// PQ35_46_CAN_Antrieb_5.7.6 Generated by BUSNETPQ 7.3.2  © 2009 Sulzer GmbH
VERSION "HNNBNNNYNNNNNNNNNNNNNNNNNNNNNNNNNNNNNNNNNN/4/%%%/4/'%**4NNN///"

NS_ :

BS_:

BU_: AFS Airbag Allrad BAP_Tester BMS_Hybrid Bremse_MK60EC Bremse_MK70MABS Bremse_TRW_EBC450M Bremse_TRW_ESP Daempfer EPB_TRW EPB_TRW_VW411CS FLA Gateway_PQ35 Gateway_Zusatz_EGolf Getriebe_AG6 Getriebe_DQ Getriebe_DQ_Hyb Getriebe_Sele Gurtmikro_PQ35 HCA Ladegeraet_EGolf LEH_Hybrid LH_EPS_APA LH_EPS_ZF_2G LH_EPS_ZF_3G LPG_Interface_Box LWR LWS Magne_Ride Motor_Diesel Motor_EGolf Motor_Hybrid Motor_Otto PDC_PLA Quersperre_VAQ RKA_Plus SAK Waehlhebel Waehlhebel_Sele

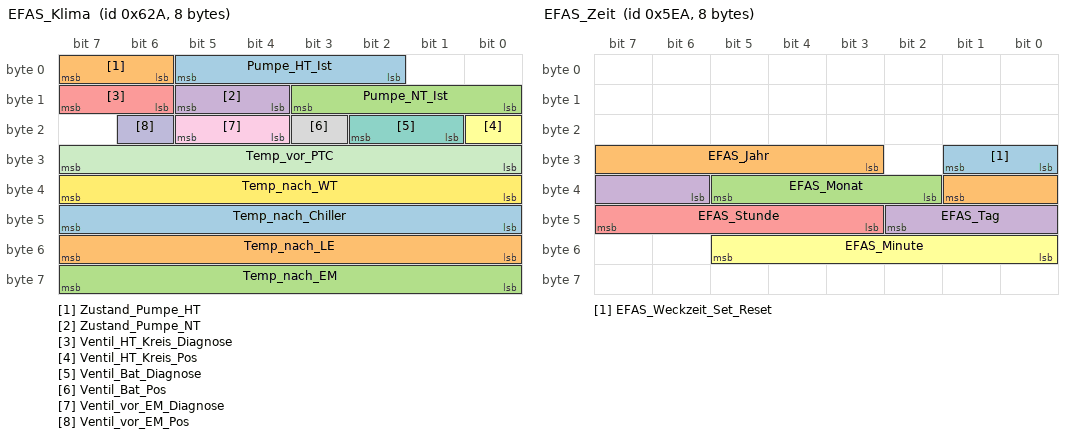
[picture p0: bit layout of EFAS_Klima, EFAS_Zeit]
BO_ 1578 EFAS_Klima: 8 Motor_EGolf
 SG_ Pumpe_HT_Ist : 2|4@1+ (10,0) [0|100] "Unit_PerCent"  Gateway_Zusatz_EGolf
 SG_ Zustand_Pumpe_HT : 6|2@1+ (1,0) [0|3] ""  Gateway_Zusatz_EGolf
 SG_ Pumpe_NT_Ist : 8|4@1+ (10,0) [0|100] "Unit_PerCent"  Gateway_Zusatz_EGolf
 SG_ Zustand_Pumpe_NT : 12|2@1+ (1,0) [0|3] ""  Gateway_Zusatz_EGolf
 SG_ Ventil_HT_Kreis_Diagnose : 14|2@1+ (1,0) [0|3] ""  Gateway_Zusatz_EGolf
 SG_ Ventil_HT_Kreis_Pos : 16|1@1+ (1,0) [0|1] ""  Gateway_Zusatz_EGolf
 SG_ Ventil_Bat_Diagnose : 17|2@1+ (1,0) [0|3] ""  Gateway_Zusatz_EGolf
 SG_ Ventil_Bat_Pos : 19|1@1+ (1,0) [0|1] ""  Gateway_Zusatz_EGolf
 SG_ Ventil_vor_EM_Diagnose : 20|2@1+ (1,0) [0|3] ""  Gateway_Zusatz_EGolf
 SG_ Ventil_vor_EM_Pos : 22|1@1+ (1,0) [0|1] ""  Gateway_Zusatz_EGolf
 SG_ Temp_vor_PTC : 24|8@1+ (1,-40) [-40|213] "Unit_DegreCelsi"  Gateway_Zusatz_EGolf
 SG_ Temp_nach_WT : 32|8@1+ (1,-40) [-40|213] "Unit_DegreCelsi"  Gateway_Zusatz_EGolf
 SG_ Temp_nach_Chiller : 40|8@1+ (1,-40) [-40|213] "Unit_DegreCelsi"  BMS_Hybrid,Gateway_Zusatz_EGolf
 SG_ Temp_nach_LE : 48|8@1+ (1,-40) [-40|213] "Unit_DegreCelsi"  Gateway_Zusatz_EGolf
 SG_ Temp_nach_EM : 56|8@1+ (1,-40) [-40|213] "Unit_DegreCelsi"  Gateway_Zusatz_EGolf

BO_ 1514 EFAS_Zeit: 8 Ladegeraet_EGolf
 SG_ EFAS_Weckzeit_Set_Reset : 24|2@1+ (1,0) [0|3] ""  Gateway_Zusatz_EGolf
 SG_ EFAS_Jahr : 27|7@1+ (1,2000) [2000|2127] "Unit_Year"  Gateway_Zusatz_EGolf
 SG_ EFAS_Monat : 34|4@1+ (1,0) [1|12] "Unit_Month"  Gateway_Zusatz_EGolf
 SG_ EFAS_Tag : 38|5@1+ (1,0) [0|31] "Unit_Day"  Gateway_Zusatz_EGolf
 SG_ EFAS_Stunde : 43|5@1+ (1,0) [0|23] "Unit_Hours"  Gateway_Zusatz_EGolf
 SG_ EFAS_Minute : 48|6@1+ (1,0) [0|59] "Unit_Minut"  Gateway_Zusatz_EGolf

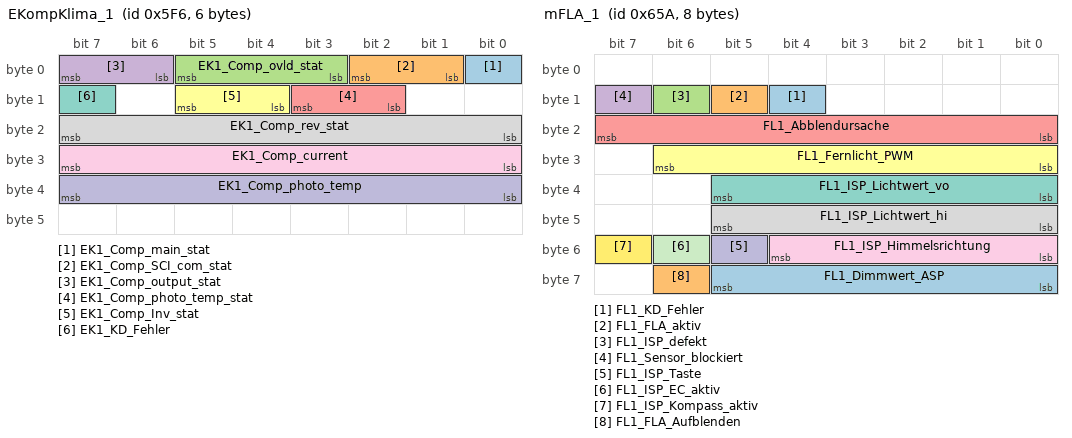
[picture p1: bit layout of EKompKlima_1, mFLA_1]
BO_ 1526 EKompKlima_1: 6 Gateway_PQ35
 SG_ EK1_Comp_main_stat : 0|1@1+ (1,0) [0|1] ""  Gateway_PQ35
 SG_ EK1_Comp_SCI_com_stat : 1|2@1+ (1,0) [0|3] ""  Gateway_PQ35
 SG_ EK1_Comp_ovld_stat : 3|3@1+ (1,0) [0|7] ""  Gateway_PQ35
 SG_ EK1_Comp_output_stat : 6|2@1+ (1,0) [0|3] ""  Gateway_PQ35
 SG_ EK1_Comp_photo_temp_stat : 10|2@1+ (1,0) [0|3] ""  Gateway_PQ35
 SG_ EK1_Comp_Inv_stat : 12|2@1+ (1,0) [0|3] ""  Gateway_PQ35
 SG_ EK1_KD_Fehler : 15|1@1+ (1,0) [0|1] ""  Gateway_PQ35
 SG_ EK1_Comp_rev_stat : 16|8@1+ (50,0) [0|8600] "Unit_MinutInver"  Gateway_PQ35
 SG_ EK1_Comp_current : 24|8@1+ (0.1,0) [0|25.4] "Unit_Amper"  Gateway_PQ35,Motor_Hybrid
 SG_ EK1_Comp_photo_temp : 32|8@1+ (1,0) [0|254] "Unit_DegreCelsi"  Gateway_PQ35

BO_ 1406 EM_Hybrid_1: 1 LEH_Hybrid
 SG_ EY1_KD_Fehler : 0|1@1+ (1,0) [0|1] ""  Gateway_PQ35

BO_ 1472 EPB_1: 8 EPB_TRW
 SG_ EP1_Zaehler : 0|4@1+ (1,0) [0|15] ""  Bremse_MK60EC,Daempfer,Gateway_PQ35,Motor_Diesel,Motor_Otto
 SG_ EP1_Fehler_Sta : 4|2@1+ (1,0) [0|3] ""  Bremse_MK60EC,Gateway_PQ35,PDC_PLA
 SG_ EP1_Sta_EPB : 6|1@1+ (1,0) [0|1] ""  Bremse_MK60EC,Gateway_PQ35,Getriebe_DQ,Getriebe_DQ_Hyb,PDC_PLA
 SG_ EP1_Sta_Schalter : 7|1@1+ (1,0) [0|1] ""  Gateway_PQ35
 SG_ EP1_Spannkraft : 8|5@1+ (1,0) [0|30] "Unit_KiloNewto"  Bremse_MK60EC,Gateway_PQ35,Getriebe_DQ,Getriebe_DQ_Hyb
 SG_ EP1_Schalterinfo : 13|2@1+ (1,0) [0|3] ""  Gateway_PQ35,Motor_Diesel,Motor_Otto
 SG_ EP1_Sta_NWS : 15|1@1+ (1,0) [0|1] ""  Gateway_PQ35,Motor_Diesel,Motor_Otto
 SG_ EP1_Neig_winkel : 16|8@1+ (1,-128) [-128|127] "Unit_PerCentOfForceOfGravi"  Gateway_PQ35,Motor_Diesel,Motor_Otto
 SG_ EP1_Verzoegerung : 24|8@1+ (0.048,-7.968) [-7.968|4.224] "Unit_MeterPerSeconSquar"  Bremse_MK60EC,Daempfer,Gateway_PQ35
 SG_ EP1_Fehlereintr : 32|1@1+ (1,0) [0|1] ""  Gateway_PQ35
 SG_ EP1_Freigabe_Ver : 33|1@1+ (1,0) [0|1] ""  Bremse_MK60EC,Daempfer,Gateway_PQ35
 SG_ EP1_AutoHold_zul : 34|1@1+ (1,0) [0|1] ""  Gateway_PQ35
 SG_ EP1_AutoHold_aktiv : 35|1@1+ (1,0) [0|1] ""  Gateway_PQ35,Motor_Diesel,Motor_Otto
 SG_ EP1_SleepInd : 36|1@1+ (1,0) [0|1] ""  Gateway_PQ35
 SG_ EP1_Status_Kl_15 : 37|1@1+ (1,0) [0|1] ""  Gateway_PQ35
 SG_ EP1_Lampe_AutoP : 38|1@1+ (1,0) [0|1] ""  Gateway_PQ35
 SG_ EP1_Bremslicht : 39|1@1+ (1,0) [0|1] ""  Gateway_PQ35
 SG_ EP1_Warnton1 : 40|1@1+ (1,0) [0|1] ""  Gateway_PQ35
 SG_ EP1_Warnton2 : 41|1@1+ (1,0) [0|1] ""  Gateway_PQ35
 SG_ EP1_AnfShLock : 42|1@1+ (1,0) [0|1] ""  Gateway_PQ35
 SG_ EP1_Auto_Schl_Oe : 43|1@1+ (1,0) [0|1] ""  Gateway_PQ35
 SG_ EP1_QualNeigWi : 44|1@1+ (1,0) [0|1] ""  Gateway_PQ35
 SG_ EP1_KuppModBer : 45|2@1+ (1,0) [0|3] ""  Gateway_PQ35,Motor_Diesel,Motor_Otto
 SG_ EP1_HydrHalten : 47|1@1+ (1,0) [0|1] ""  Gateway_PQ35,Getriebe_DQ,Getriebe_DQ_Hyb,Motor_Diesel,Motor_Otto
 SG_ EP1_Fkt_Lampe : 48|1@1+ (1,0) [0|1] ""  Bremse_MK60EC,Gateway_PQ35
 SG_ EP1_Warnton : 49|1@1+ (1,0) [0|1] ""  Gateway_PQ35
 SG_ EP1_Fehler_BKL : 50|1@1+ (1,0) [0|1] ""  Gateway_PQ35
 SG_ EP1_Fehler_gelb : 51|1@1+ (1,0) [0|1] ""  Gateway_PQ35
 SG_ EP1__Text : 52|4@1+ (1,0) [0|15] ""  Gateway_PQ35,Getriebe_DQ,Getriebe_DQ_Hyb
 SG_ EP1_Checksum : 56|8@1+ (1,0) [0|255] ""  Bremse_MK60EC,Daempfer,Gateway_PQ35,Motor_Diesel,Motor_Otto

BO_ 1626 mFLA_1: 8 FLA
 SG_ FL1_KD_Fehler : 12|1@1+ (1,0) [0|1] ""  Gateway_PQ35
 SG_ FL1_FLA_aktiv : 13|1@1+ (1,0) [0|1] ""  Gateway_PQ35
 SG_ FL1_ISP_defekt : 14|1@1+ (1,0) [0|1] ""  Gateway_PQ35
 SG_ FL1_Sensor_blockiert : 15|1@1+ (1,0) [0|1] ""  Gateway_PQ35
 SG_ FL1_Abblendursache : 16|8@1+ (1,0) [0|255] ""  Gateway_PQ35
 SG_ FL1_Fernlicht_PWM : 24|7@1+ (1,0) [0|100] "Unit_PerCent"  Gateway_PQ35
 SG_ FL1_ISP_Lichtwert_vo : 32|6@1+ (1,0) [0|61] ""  Gateway_PQ35
 SG_ FL1_ISP_Lichtwert_hi : 40|6@1+ (1,0) [0|61] ""  Gateway_PQ35
 SG_ FL1_ISP_Himmelsrichtung : 48|5@1+ (12,0) [0|348] "Unit_DegreOfArc"  Gateway_PQ35
 SG_ FL1_ISP_Taste : 53|1@1+ (1,0) [0|1] ""  Gateway_PQ35
 SG_ FL1_ISP_EC_aktiv : 54|1@1+ (1,0) [0|1] ""  Gateway_PQ35
 SG_ FL1_ISP_Kompass_aktiv : 55|1@1+ (1,0) [0|1] ""  Gateway_PQ35
 SG_ FL1_Dimmwert_ASP : 56|6@1+ (1.613,0) [0|100.006] "Unit_PerCent"  Gateway_PQ35
 SG_ FL1_FLA_Aufblenden : 62|1@1+ (1,0) [0|1] ""  Gateway_PQ35

BO_ 912 Gate_Komf_1: 8 Gateway_PQ35
 SG_ GK1_Sta_RDK_Warn : 0|1@1+ (1,0) [0|1] "" Vector__XXX
 SG_ GK1_Sta_Anhaen : 1|1@1+ (1,0) [0|1] ""  Bremse_MK60EC,Bremse_TRW_EBC450M,Bremse_TRW_ESP,Getriebe_DQ,Getriebe_DQ_Hyb,HCA,Motor_Diesel,Motor_Otto,PDC_PLA,RKA_Plus
 SG_ GK1_Sta_Licht1 : 2|1@1+ (1,0) [0|1] ""  AFS,Bremse_MK60EC,Bremse_MK70MABS,Bremse_TRW_EBC450M,Bremse_TRW_ESP,EPB_TRW,EPB_TRW_VW411CS,FLA,LH_EPS_APA,LH_EPS_ZF_2G,LH_EPS_ZF_3G,Motor_Diesel,Motor_Otto,PDC_PLA
 SG_ GK1_Sta_Licht3 : 3|1@1+ (1,0) [0|1] ""  AFS
 SG_ GK1_Sta_Tuerkont : 4|1@1+ (1,0) [0|1] ""  Bremse_MK60EC,Bremse_MK70MABS,Bremse_TRW_EBC450M,Bremse_TRW_ESP,EPB_TRW,EPB_TRW_VW411CS,Getriebe_DQ,Getriebe_DQ_Hyb,Motor_Diesel,Motor_EGolf,Motor_Hybrid,Motor_Otto,PDC_PLA
 SG_ GK1_Sta_Li_vorn : 5|1@1+ (1,0) [0|1] ""  AFS
 SG_ GK1_SleepAckn : 7|1@1+ (1,0) [0|1] ""  Bremse_MK60EC,Bremse_MK70MABS,Bremse_TRW_ESP,EPB_TRW,Getriebe_AG6,Getriebe_DQ,Getriebe_DQ_Hyb,Getriebe_Sele,LH_EPS_APA,LH_EPS_ZF_2G,LH_EPS_ZF_3G,LWS,Motor_Diesel,Motor_EGolf,Motor_Hybrid,Motor_Otto,Waehlhebel,Waehlhebel_Sele
 SG_ GK1_CharismaModus m1 : 8|4@1+ (1,0) [0|15] ""  Daempfer,Getriebe_AG6,Getriebe_DQ,Getriebe_DQ_Hyb,LH_EPS_APA,LH_EPS_ZF_2G,LH_EPS_ZF_3G,Magne_Ride,Motor_Diesel,Motor_Otto
 SG_ GK1_EfficiencyModus m2 : 8|4@1+ (1,0) [0|15] "" Vector__XXX
 SG_ GK1_SportModus m3 : 8|4@1+ (1,0) [0|15] "" Vector__XXX
 SG_ GK1_DriveSelectModus_1 m4 : 8|4@1+ (1,0) [0|15] "" Vector__XXX
 SG_ GK1_DriveSelectModus_2 m5 : 8|4@1+ (1,0) [0|15] "" Vector__XXX
 SG_ GK1_SamFktNr M : 12|4@1+ (1,0) [0|15] ""  Daempfer,Getriebe_AG6,Getriebe_DQ,Getriebe_DQ_Hyb,LH_EPS_APA,LH_EPS_ZF_2G,LH_EPS_ZF_3G,Magne_Ride,Motor_Diesel,Motor_Otto
 SG_ GK1_Fa_Tuerkont : 16|1@1+ (1,0) [0|1] ""  Bremse_MK60EC,Bremse_MK70MABS,Bremse_TRW_EBC450M,Bremse_TRW_ESP,EPB_TRW,EPB_TRW_VW411CS,Getriebe_DQ,Getriebe_DQ_Hyb,Motor_Diesel,Motor_EGolf,Motor_Hybrid,Motor_Otto
 SG_ GK1_RueckfahrSch : 17|1@1+ (1,0) [0|1] "" Vector__XXX
 SG_ GK1_ELV_verrieg : 18|1@1+ (1,0) [0|1] "" Vector__XXX
 SG_ GK1_Sta_Kessy_2 : 19|1@1+ (1,0) [0|1] "" Vector__XXX
 SG_ GK1_Sta_Stdhzg : 20|1@1+ (1,0) [0|1] ""  Motor_Diesel,Motor_Hybrid,Motor_Otto
 SG_ GK1_SH_Verbau : 21|1@1+ (1,0) [0|1] ""  Motor_Diesel,Motor_Hybrid,Motor_Otto
 SG_ GK1_ParkFrontWi : 22|1@1+ (1,0) [0|1] "" Vector__XXX
 SG_ GK1_KW_Warm : 23|1@1+ (1,0) [0|1] ""  Motor_Diesel,Motor_Hybrid,Motor_Otto
 SG_ BCM_Remotestart_Betrieb : 24|1@1+ (1,0) [0|1] ""  Motor_Diesel,Motor_Otto
 SG_ BCM_Offroad_Taster : 25|1@1+ (1,0) [0|1] ""  Motor_Diesel,Motor_Otto
 SG_ BSK_HL_geoeffnet : 26|1@1+ (1,0) [0|1] ""  Motor_Diesel,Motor_Otto,PDC_PLA
 SG_ BSK_HR_geoeffnet : 27|1@1+ (1,0) [0|1] ""  Motor_Diesel,Motor_Otto,PDC_PLA
 SG_ GK1_Rueckfahr : 28|1@1+ (1,0) [0|1] ""  AFS,Bremse_MK60EC,Bremse_MK70MABS,Bremse_TRW_EBC450M,Bremse_TRW_ESP,EPB_TRW,EPB_TRW_VW411CS,FLA,LH_EPS_APA,LH_EPS_ZF_2G,LH_EPS_ZF_3G,Motor_Diesel,Motor_Otto,PDC_PLA
 SG_ GK1_BrLi_links : 29|1@1+ (1,0) [0|1] "" Vector__XXX
 SG_ GK1_BrLi_rechts : 30|1@1+ (1,0) [0|1] "" Vector__XXX
 SG_ GK1_BrLi_mitte : 31|1@1+ (1,0) [0|1] "" Vector__XXX
 SG_ GK1_BLS_ILM : 32|1@1+ (1,0) [0|1] "" Vector__XXX
 SG_ GK1_EDC_ILM : 33|1@1+ (1,0) [0|1] "" Vector__XXX
 SG_ GK1_Blinker_li : 34|1@1+ (1,0) [0|1] ""  AFS,LWR,Motor_Diesel,Motor_Otto,PDC_PLA
 SG_ GK1_Blinker_re : 35|1@1+ (1,0) [0|1] ""  AFS,LWR,Motor_Diesel,Motor_Otto,PDC_PLA
 SG_ GK1_def_P_verr : 36|1@1+ (1,0) [0|1] ""  Getriebe_AG6,Motor_EGolf
 SG_ GK1_LS1_Fernlicht : 37|1@1+ (1,0) [0|1] ""  FLA
 SG_ GK1_Sta_Licht2 : 38|1@1+ (1,0) [0|1] ""  AFS
 SG_ GK1_Sta_LSM : 39|1@1+ (1,0) [0|1] ""  AFS,FLA,Getriebe_AG6,Motor_Diesel,Motor_Otto,PDC_PLA
 SG_ WI1_Front_Wasch : 40|1@1+ (1,0) [0|1] "" Vector__XXX
 SG_ BSK_BT_geoeffnet : 41|1@1+ (1,0) [0|1] ""  Motor_Diesel,Motor_Otto
 SG_ BCM_CV_Taster : 42|1@1+ (1,0) [0|1] "" Vector__XXX
 SG_ BSK_HD_Hauptraste : 43|1@1+ (1,0) [0|1] ""  Motor_Diesel,Motor_Otto
 SG_ GK1_Anhaenger : 46|1@1+ (1,0) [0|1] ""  Bremse_MK60EC,Bremse_TRW_EBC450M,Bremse_TRW_ESP,Getriebe_DQ,Getriebe_DQ_Hyb,HCA,Motor_Diesel,Motor_Otto,PDC_PLA,RKA_Plus
 SG_ GK1_BrLi_Anhaen : 47|1@1+ (1,0) [0|1] "" Vector__XXX
 SG_ GK1_Abblendlicht : 48|1@1+ (1,0) [0|1] ""  AFS,FLA,LWR
 SG_ GK1_Fernlicht : 49|1@1+ (1,0) [0|1] ""  AFS,FLA,LWR
 SG_ GK1_Wischer_vorn : 50|1@1+ (1,0) [0|1] ""  AFS,Bremse_MK60EC,Bremse_MK70MABS,Bremse_TRW_EBC450M,Bremse_TRW_ESP,HCA,Motor_Diesel
 SG_ GK1_Sta_ILM_F_1 : 51|1@1+ (1,0) [0|1] ""  AFS,Bremse_MK60EC,Bremse_MK70MABS,Bremse_TRW_EBC450M,Bremse_TRW_ESP,HCA
 SG_ GK1_Abbl_VL_def : 52|1@1+ (1,0) [0|1] ""  AFS
 SG_ GK1_Abbl_VR_def : 53|1@1+ (1,0) [0|1] ""  AFS
 SG_ GK1_Blink_Autob : 54|1@1+ (1,0) [0|1] "" Vector__XXX
 SG_ GK1_Warnblk_Status : 55|1@1+ (1,0) [0|1] ""  Bremse_TRW_EBC450M,Bremse_TRW_ESP
 SG_ GK1_SH_laeuft : 56|1@1+ (1,0) [0|1] "" Vector__XXX
 SG_ SH1_ein_Wasserpumpe : 57|1@1+ (1,0) [0|1] "" Vector__XXX
 SG_ GK1_Nebel_ein : 58|1@1+ (1,0) [0|1] ""  AFS,FLA
 SG_ GK1_Bremslicht : 59|1@1+ (1,0) [0|1] "" Vector__XXX
 SG_ GK1_Anh_abgesteckt : 60|1@1+ (1,0) [0|1] "" Vector__XXX
 SG_ GK1_AnhKonLamp : 61|1@1+ (1,0) [0|1] "" Vector__XXX
 SG_ LDS_Stellung_AFL : 62|1@1+ (1,0) [0|1] "" Vector__XXX
 SG_ GK1_SH_Zusatzfkt : 63|1@1+ (1,0) [0|1] "" Vector__XXX

BO_ 914 Gate_Komf_2: 8 Gateway_PQ35
 SG_ GK2_Sta_LSM : 0|1@1+ (1,0) [0|1] "" Vector__XXX
 SG_ GK2_Sta_Lichtsensor : 1|1@1+ (1,0) [0|1] ""  AFS
 SG_ GK2_Sta_Licht1 : 2|1@1+ (1,0) [0|1] ""  AFS,HCA
 SG_ GK2_Sta_VSG : 3|1@1+ (1,0) [0|1] ""  Airbag,Motor_Otto,PDC_PLA
 SG_ GK2_Sta_Schluessel : 4|1@1+ (1,0) [0|1] ""  Daempfer
 SG_ GK2_Sta_Profil : 5|1@1+ (1,0) [0|1] ""  PDC_PLA
 SG_ GK2_Sta_Clima2 : 6|1@1+ (1,0) [0|1] ""  Motor_Diesel,Motor_Otto
 SG_ GK2_Sta_BSG4 : 7|1@1+ (1,0) [0|1] ""  Motor_Diesel,Motor_Otto
 SG_ GK2_Sta_Kessy_4 : 8|1@1+ (1,0) [0|1] ""  Motor_Diesel,Motor_Otto
 SG_ BS4_Gleitende_Leuchtw_Anf : 9|1@1+ (1,0) [0|1] "" Vector__XXX
 SG_ BS4_GLW_Fernlicht_Anf : 10|1@1+ (1,0) [0|1] "" Vector__XXX
 SG_ GK2_Blk_L_Kontrolle : 11|1@1+ (1,0) [0|1] ""  HCA
 SG_ GK2_Blk_R_Kontrolle : 12|1@1+ (1,0) [0|1] ""  HCA
 SG_ GK2_LS_KomFehler : 14|1@1+ (1,0) [0|1] ""  AFS
 SG_ GK2_LS_def : 15|1@1+ (1,0) [0|1] ""  AFS
 SG_ GK2_Helligkeit : 16|3@1+ (714.286,0) [0|5000.002] "Unit_Lux"  AFS
 SG_ GK2_VD_zu_ver : 19|1@1+ (1,0) [0|1] ""  PDC_PLA
 SG_ GK2_VD_entriegelt : 20|1@1+ (1,0) [0|1] ""  PDC_PLA
 SG_ GK2_VD_offen_ver : 21|1@1+ (1,0) [0|1] ""  Airbag,Motor_Otto,PDC_PLA
 SG_ GK2_Verdeck_Anf : 22|1@1+ (1,0) [0|1] ""  PDC_PLA
 SG_ GK2_VDKD_auf : 23|1@1+ (1,0) [0|1] ""  PDC_PLA
 SG_ GK2_Schluessel : 24|4@1+ (1,0) [0|15] "" Vector__XXX
 SG_ GK2_Hardtop : 28|1@1+ (1,0) [0|1] ""  PDC_PLA
 SG_ GK2_AFL_Schalter : 29|1@1+ (1,0) [0|1] ""  AFS
 SG_ GK2_Nebelschluss : 30|1@1+ (1,0) [0|1] ""  AFS
 SG_ GK2_EM_LIN_ungueltig : 31|1@1+ (1,0) [0|1] ""  Motor_Diesel,Motor_Otto
 SG_ GK2_Profil : 32|4@1+ (1,0) [0|15] ""  PDC_PLA
 SG_ GK2_Kl_StSt_Info : 36|2@1+ (1,0) [0|3] ""  Motor_Diesel,Motor_Otto
 SG_ GK2_BSG_StSt_Info : 38|2@1+ (1,0) [0|3] ""  Motor_Diesel,Motor_Otto
 SG_ GK2_BEM_P_Generator : 40|8@1+ (50,0) [0|12700] "Unit_Watt"  Motor_Diesel,Motor_Otto
 SG_ GK2_BEM_Abschaltstufen : 48|3@1+ (1,0) [0|7] "" Vector__XXX
 SG_ GK2_BEM_DFM : 51|5@1+ (3.225,0.025) [0.025|100] "Unit_PerCent"  Motor_Diesel,Motor_Otto
 SG_ GK2_Kessy_StSt_Info : 56|2@1+ (1,0) [0|3] ""  Motor_Diesel,Motor_Otto
 SG_ GK2_BEM_StSt_Info : 58|2@1+ (1,0) [0|3] ""  Motor_Diesel,Motor_Otto
 SG_ BEM_Segel_Info : 60|2@1+ (1,0) [0|3] ""  Getriebe_DQ,Getriebe_DQ_Hyb,Motor_Diesel,Motor_Otto
 SG_ LS1_FAS_Taster : 62|1@1+ (1,0) [0|1] "" Vector__XXX
 SG_ LS1_Fehler_FAS_Taster : 63|1@1+ (1,0) [0|1] "" Vector__XXX

BO_ 915 Gate_Komf_3: 8 Gateway_PQ35
 SG_ GK3_Sta_Kessy_4 : 0|1@1+ (1,0) [0|1] "" Vector__XXX
 SG_ GK3_Sta_BCM_KY1 : 1|1@1+ (1,0) [0|1] "" Vector__XXX
 SG_ GK3_Sta_Clima_3 : 2|1@1+ (1,0) [0|1] "" Vector__XXX
 SG_ GK3_Sta_TSG_FT_3 : 3|1@1+ (1,0) [0|1] "" Vector__XXX
 SG_ GK3_Sta_HD_1 : 4|1@1+ (1,0) [0|1] ""  PDC_PLA
 SG_ GK3_Sta_Memory_1 : 5|1@1+ (1,0) [0|1] "" Vector__XXX
 SG_ GK3_Sta_res_06 : 6|1@1+ (1,0) [0|1] "" Vector__XXX
 SG_ GK3_Sta_res_07 : 7|1@1+ (1,0) [0|1] "" Vector__XXX
 SG_ GK3_KY4_Meldungen : 8|4@1+ (1,0) [0|15] "" Vector__XXX
 SG_ GK3_KY4_Gong_600 : 12|1@1+ (1,0) [0|1] "" Vector__XXX
 SG_ GK3_KY4_PassAL_Menue : 14|1@1+ (1,0) [0|1] "" Vector__XXX
 SG_ GK3_KY4_PassAL_akt : 15|1@1+ (1,0) [0|1] "" Vector__XXX
 SG_ GK3_BK1_IDGeb_1_Sta : 16|3@1+ (1,0) [0|7] "" Vector__XXX
 SG_ GK3_BK1_IDGeb_2_Sta : 19|3@1+ (1,0) [0|7] "" Vector__XXX
 SG_ ME1_EasyEntry_Menu : 22|1@1+ (1,0) [0|1] "" Vector__XXX
 SG_ ME1_EasyEntry_aktiv : 23|1@1+ (1,0) [0|1] "" Vector__XXX
 SG_ GK3_BK1_IDGeb_3_Sta : 24|3@1+ (1,0) [0|7] "" Vector__XXX
 SG_ GK3_BK1_IDGeb_4_Sta : 27|3@1+ (1,0) [0|7] "" Vector__XXX
 SG_ GK3_BK1_Anlern_Info : 30|1@1+ (1,0) [0|1] "" Vector__XXX
 SG_ CL3_SH_Wasserpumpe : 32|1@1+ (1,0) [0|1] "" Vector__XXX
 SG_ FT3_Auto_eKiSi_Menu : 33|1@1+ (1,0) [0|1] "" Vector__XXX
 SG_ FT3_Auto_eKiSi_Aktiv : 34|1@1+ (1,0) [0|1] "" Vector__XXX
 SG_ MKE_Texte : 35|3@1+ (1,0) [0|7] "" Vector__XXX
 SG_ HSA_unplausibel : 38|1@1+ (1,0) [0|1] "" Vector__XXX
 SG_ CHA_Kombi_Texte : 40|4@1+ (1,0) [0|15] "" Vector__XXX
 SG_ HD1_Position : 56|8@1+ (0.5,0) [0|100] "Unit_PerCent"  PDC_PLA

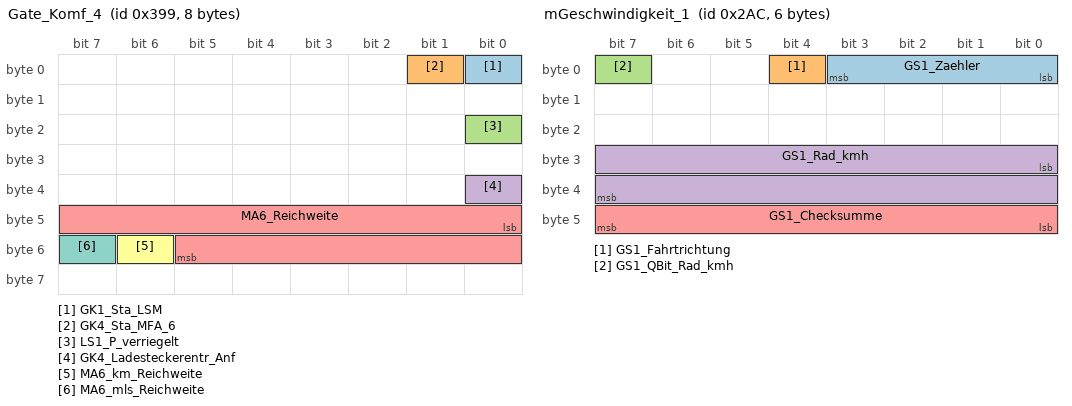
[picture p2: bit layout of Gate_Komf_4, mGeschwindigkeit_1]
BO_ 921 Gate_Komf_4: 8 Gateway_Zusatz_EGolf
 SG_ GK1_Sta_LSM : 0|1@1+ (1,0) [0|1] ""  Motor_EGolf
 SG_ GK4_Sta_MFA_6 : 1|1@1+ (1,0) [0|1] ""  Motor_EGolf
 SG_ LS1_P_verriegelt : 16|1@1+ (1,0) [0|1] ""  Motor_EGolf
 SG_ GK4_Ladesteckerentr_Anf : 32|1@1+ (1,0) [0|1] ""  Ladegeraet_EGolf,Motor_EGolf
 SG_ MA6_Reichweite : 40|14@1+ (1,0) [0|16382] ""  Motor_EGolf
 SG_ MA6_km_Reichweite : 54|1@1+ (1,0) [0|1] ""  Motor_EGolf
 SG_ MA6_mls_Reichweite : 55|1@1+ (1,0) [0|1] ""  Motor_EGolf

BO_ 684 mGeschwindigkeit_1: 6 Bremse_MK60EC
 SG_ GS1_Zaehler : 0|4@1+ (1,0) [0|15] ""  Magne_Ride
 SG_ GS1_Fahrtrichtung : 4|1@1+ (1,0) [0|1] "" Vector__XXX
 SG_ GS1_QBit_Rad_kmh : 7|1@1+ (1,0) [0|1] ""  Magne_Ride
 SG_ GS1_Rad_kmh : 24|16@1+ (0.01,0) [0|654.15] "Unit_KiloMeterPerHour"  Magne_Ride,SAK
 SG_ GS1_Checksumme : 40|8@1+ (1,0) [0|255] ""  Magne_Ride

BO_ 1088 Getriebe_1: 8 Getriebe_AG6
 SG_ GE1_Schaltung : 0|1@1+ (1,0) [0|1] ""  Bremse_MK60EC,Bremse_MK70MABS,Bremse_TRW_EBC450M,Bremse_TRW_ESP,Gateway_PQ35,Motor_Diesel,Motor_Hybrid,Motor_Otto,RKA_Plus
 SG_ GE1_Sta_Schutz : 1|1@1+ (1,0) [0|1] ""  Gateway_PQ35,Motor_Diesel,Motor_Hybrid,Motor_Otto
 SG_ GE1_Klimakompr : 2|1@1+ (1,0) [0|1] ""  Gateway_PQ35,Motor_Diesel,Motor_Hybrid,Motor_Otto
 SG_ GE1_WK : 3|2@1+ (1,0) [0|3] ""  Allrad,Gateway_PQ35,Motor_Diesel,Motor_Hybrid,Motor_Otto,RKA_Plus
 SG_ GE1_StSt_Info : 5|2@1+ (1,0) [0|3] ""  Gateway_PQ35,Motor_Diesel,Motor_Otto
 SG_ GE1_EGS_Anf : 7|1@1+ (1,0) [0|1] ""  Gateway_PQ35,Motor_Diesel,Motor_Hybrid,Motor_Otto
 SG_ GE1_Zielgang : 8|4@1+ (1,0) [0|15] ""  Allrad,Bremse_MK60EC,Bremse_MK70MABS,Bremse_TRW_EBC450M,Bremse_TRW_ESP,Gateway_PQ35,Motor_Diesel,Motor_Hybrid,Motor_Otto,RKA_Plus
 SG_ GE1_Wahl_Pos : 12|4@1+ (1,0) [0|15] ""  BMS_Hybrid,Bremse_MK60EC,Bremse_MK70MABS,Bremse_TRW_EBC450M,Bremse_TRW_ESP,EPB_TRW,EPB_TRW_VW411CS,Gateway_PQ35,Motor_Diesel,Motor_Hybrid,Motor_Otto,PDC_PLA,RKA_Plus
 SG_ GE1_Mrad_Mkurb : 16|8@1+ (0.1,0) [0|25.4] ""  Bremse_MK60EC,Bremse_MK70MABS,Bremse_TRW_EBC450M,Bremse_TRW_ESP,EPB_TRW,EPB_TRW_VW411CS,Gateway_PQ35,Motor_Diesel,Motor_Hybrid,Motor_Otto
 SG_ GE1_Soll_Mo : 24|8@1+ (0.39,0) [0|99.06] "Unit_PerCent"  Gateway_PQ35,Motor_Diesel,Motor_Hybrid,Motor_Otto
 SG_ GE1_Fahrwistd : 32|8@1+ (0.249,-31.623) [-31.623|31.623] ""  Gateway_PQ35,Motor_Diesel,Motor_Hybrid,Motor_Otto
 SG_ GE1_Notlauf : 40|4@1+ (1,0) [0|15] ""  Bremse_TRW_EBC450M,Bremse_TRW_ESP,Gateway_PQ35,Motor_Diesel,Motor_Hybrid,Motor_Otto
 SG_ GE1_Kuehlung : 44|2@1+ (1,0) [0|3] ""  Gateway_PQ35,Motor_Diesel,Motor_Hybrid,Motor_Otto
 SG_ GE1_Sta_OBD : 47|1@1+ (1,0) [0|1] ""  Gateway_PQ35,Motor_Diesel,Motor_Hybrid,Motor_Otto
 SG_ GE1_LaunchControl : 48|1@1+ (1,0) [0|1] ""  Bremse_MK60EC,Bremse_MK70MABS,Gateway_PQ35,Motor_Diesel,Motor_Hybrid,Motor_Otto
 SG_ GE1_Infobit : 49|1@1+ (1,0) [0|1] ""  Gateway_PQ35
 SG_ GE1_SleepInd : 50|1@1+ (1,0) [0|1] ""  Gateway_PQ35
 SG_ GE1_Zaehler : 51|4@1+ (1,0) [0|15] ""  Bremse_MK60EC,Bremse_TRW_EBC450M,Bremse_TRW_ESP,EPB_TRW,EPB_TRW_VW411CS,Gateway_PQ35,Motor_Diesel,Motor_Hybrid,Motor_Otto
 SG_ GE1_Fehlereintr : 55|1@1+ (1,0) [0|1] ""  Gateway_PQ35
 SG_ GE1_WaVerl_Mo : 56|8@1+ (0.39,0) [0|99.06] "Unit_PerCent"  Gateway_PQ35,Motor_Diesel,Motor_Hybrid,Motor_Otto

BO_ 1344 Getriebe_2: 8 Getriebe_AG6
 SG_ GE2_LFR_Adap : 0|1@1+ (1,0) [0|1] ""  Gateway_PQ35,Motor_Diesel,Motor_Hybrid,Motor_Otto
 SG_ GE2_Sta_SAS : 1|1@1+ (1,0) [0|1] ""  Gateway_PQ35,Motor_Otto
 SG_ GE2_SlipStDZEingr : 2|1@1+ (1,0) [0|1] ""  Gateway_PQ35,Motor_Hybrid
 SG_ GE2_Sta_ZwGas : 3|1@1+ (1,0) [0|1] ""  Gateway_PQ35,Motor_Diesel,Motor_Hybrid,Motor_Otto
 SG_ GE2_Zaehler : 4|4@1+ (1,0) [0|15] ""  Gateway_PQ35,Motor_Diesel,Motor_Hybrid,Motor_Otto
 SG_ GE2_LL_Solldz : 8|8@1+ (10,0) [0|2540] "Unit_MinutInver"  Gateway_PQ35,Motor_Diesel,Motor_Hybrid,Motor_Otto
 SG_ GE2_Grad_begr : 16|8@1+ (10,0) [0|2540] "Unit_NewtoMeterPerSecon"  Gateway_PQ35,Motor_Diesel,Motor_Hybrid,Motor_Otto
 SG_ GE2_Sync_Dz : 24|8@1+ (25,0) [0|6375] "Unit_MinutInver"  Gateway_PQ35,Motor_Diesel,Motor_Hybrid,Motor_Otto
 SG_ GE2_invSync_Dz : 32|8@1+ (-25,6375) [0|6375] "Unit_MinutInver"  Gateway_PQ35,Motor_Diesel,Motor_Hybrid,Motor_Otto
 SG_ GE2_Sync_Zeit : 40|8@1+ (20,0) [0|5080] "Unit_MilliSecon"  Gateway_PQ35,Motor_Diesel,Motor_Hybrid,Motor_Otto
 SG_ GE2_DZM_Daempf : 48|1@1+ (1,0) [0|1] ""  Gateway_PQ35,Motor_Diesel,Motor_Otto
 SG_ GE2_invMSB_Sync : 49|1@1+ (1,0) [0|1] ""  Gateway_PQ35,Motor_Otto
 SG_ GE2_Gong : 50|1@1+ (1,0) [0|1] ""  Gateway_PQ35
 SG_ GE2_Segeln_aktiv : 51|1@1+ (1,0) [0|1] ""  Gateway_PQ35
 SG_ GE2_Shift_Lock : 52|1@1+ (1,0) [0|1] ""  Gateway_PQ35
 SG_ GE2_Senderkennung : 53|1@1+ (1,0) [0|1] ""  Allrad,Gateway_PQ35
 SG_ GE2_MSB_Sync : 54|1@1+ (1,0) [0|1] ""  Gateway_PQ35,Motor_Otto
 SG_ GE2_WBA_Blinken : 55|1@1+ (1,0) [0|1] ""  Gateway_PQ35,Motor_Diesel,Motor_Hybrid,Motor_Otto
 SG_ GE2_Variante M : 56|4@1+ (1,0) [0|15] ""  Allrad,Gateway_PQ35,Waehlhebel_Sele
 SG_ GE2_5Gang m0 : 60|4@1+ (1,0) [0|15] ""  Gateway_PQ35
 SG_ GE2_PRND m1 : 60|4@1+ (1,0) [0|15] ""  Gateway_PQ35
 SG_ GE2_4Gang m2 : 60|4@1+ (1,0) [0|15] ""  Gateway_PQ35
 SG_ GE2_ASG m3 : 60|4@1+ (1,0) [0|15] ""  Gateway_PQ35
 SG_ GE2_Selespeed m4 : 60|4@1+ (1,0) [0|15] ""  Gateway_PQ35,Waehlhebel_Sele
 SG_ GE2_res_MUX5 m5 : 60|4@1+ (1,0) [0|15] ""  Gateway_PQ35
 SG_ GE2_PRNDS m6 : 60|4@1+ (1,0) [0|15] ""  Gateway_PQ35
 SG_ GE2_PRNED m7 : 60|4@1+ (1,0) [0|15] ""  Gateway_PQ35
 SG_ GE2_Tip4Gang m8 : 60|4@1+ (1,0) [0|15] ""  Gateway_PQ35
 SG_ GE2_Tip5Gang m9 : 60|4@1+ (1,0) [0|15] ""  Gateway_PQ35
 SG_ GE2_res_MUX10 m10 : 60|4@1+ (1,0) [0|15] ""  Gateway_PQ35
 SG_ GE2_PRNDB m11 : 60|4@1+ (1,0) [0|15] ""  Gateway_PQ35
 SG_ GE2_Tip6Gang m12 : 60|4@1+ (1,0) [0|15] ""  Gateway_PQ35
 SG_ GE2_Tip7Gang m13 : 60|4@1+ (1,0) [0|15] ""  Gateway_PQ35
 SG_ GE2_Tip8Gang m14 : 60|4@1+ (1,0) [0|15] ""  Gateway_PQ35
 SG_ GE2_akt_Gang m15 : 60|4@1+ (1,0) [0|15] ""  Gateway_PQ35,Waehlhebel_Sele

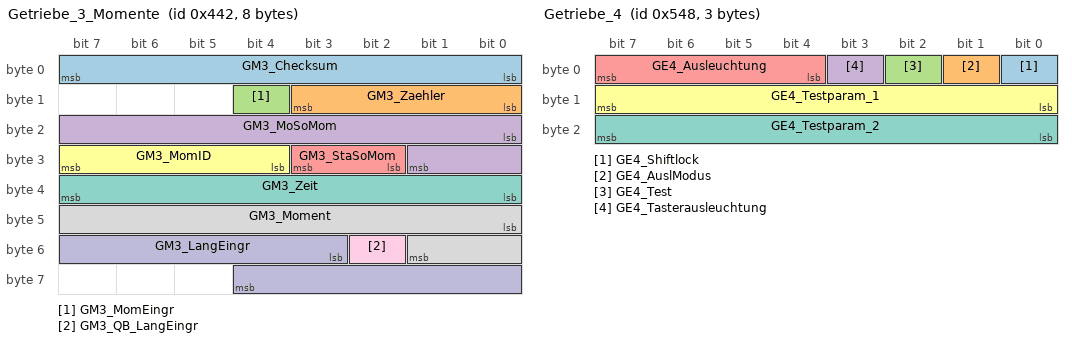
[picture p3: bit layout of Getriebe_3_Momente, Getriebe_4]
BO_ 1090 Getriebe_3_Momente: 8 Getriebe_DQ
 SG_ GM3_Checksum : 0|8@1+ (1,0) [0|255] ""  Motor_Otto
 SG_ GM3_Zaehler : 8|4@1+ (1,0) [0|15] ""  Motor_Otto
 SG_ GM3_MomEingr : 12|1@1+ (1,0) [0|1] ""  Motor_Hybrid,Motor_Otto
 SG_ GM3_MoSoMom : 16|10@1+ (1,0) [0|1021] "Unit_NewtoMeter"  Motor_Hybrid,Motor_Otto
 SG_ GM3_StaSoMom : 26|2@1+ (1,0) [0|3] ""  Motor_Otto
 SG_ GM3_MomID : 28|4@1+ (1,0) [0|15] ""  Motor_Otto
 SG_ GM3_Zeit : 32|8@1+ (10,0) [0|2550] "Unit_MilliSecon"  Motor_Otto
 SG_ GM3_Moment : 40|10@1+ (1,0) [0|1022] "Unit_NewtoMeter"  Motor_Otto
 SG_ GM3_QB_LangEingr : 50|1@1+ (1,0) [0|1] ""  Motor_Otto
 SG_ GM3_LangEingr : 51|10@1+ (1,0) [0|1021] "Unit_NewtoMeter"  Motor_Otto

BO_ 1352 Getriebe_4: 3 Getriebe_DQ
 SG_ GE4_Shiftlock : 0|1@1+ (1,0) [0|1] ""  Waehlhebel
 SG_ GE4_AuslModus : 1|1@1+ (1,0) [0|1] ""  Waehlhebel
 SG_ GE4_Test : 2|1@1+ (1,0) [0|1] ""  Waehlhebel
 SG_ GE4_Tasterausleuchtung : 3|1@1+ (1,0) [0|1] "" Vector__XXX
 SG_ GE4_Ausleuchtung : 4|4@1+ (1,0) [0|15] ""  Waehlhebel
 SG_ GE4_Testparam_1 : 8|8@1+ (1,0) [0|255] ""  Waehlhebel
 SG_ GE4_Testparam_2 : 16|8@1+ (1,0) [0|255] ""  Waehlhebel

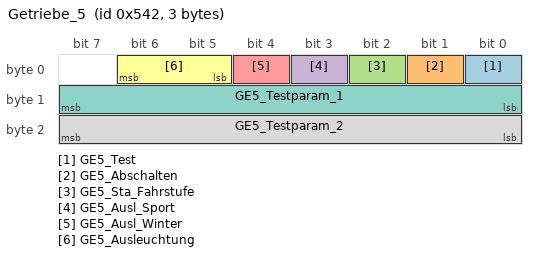
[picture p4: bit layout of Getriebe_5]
BO_ 1346 Getriebe_5: 3 Getriebe_Sele
 SG_ GE5_Test : 0|1@1+ (1,0) [0|1] ""  Waehlhebel_Sele
 SG_ GE5_Abschalten : 1|1@1+ (1,0) [0|1] ""  Waehlhebel_Sele
 SG_ GE5_Sta_Fahrstufe : 2|1@1+ (1,0) [0|1] ""  Waehlhebel_Sele
 SG_ GE5_Ausl_Sport : 3|1@1+ (1,0) [0|1] ""  Waehlhebel_Sele
 SG_ GE5_Ausl_Winter : 4|1@1+ (1,0) [0|1] ""  Waehlhebel_Sele
 SG_ GE5_Ausleuchtung : 5|2@1+ (1,0) [0|3] ""  Waehlhebel_Sele
 SG_ GE5_Testparam_1 : 8|8@1+ (1,0) [0|255] ""  Waehlhebel_Sele
 SG_ GE5_Testparam_2 : 16|8@1+ (1,0) [0|255] ""  Waehlhebel_Sele

BO_TX_BU_ 1472 : EPB_TRW,EPB_TRW_VW411CS;
BO_TX_BU_ 1088 : Getriebe_AG6,Getriebe_DQ,Getriebe_DQ_Hyb,Getriebe_Sele,Motor_EGolf;
BO_TX_BU_ 1344 : Getriebe_AG6,Getriebe_DQ,Getriebe_DQ_Hyb,Getriebe_Sele,Motor_Diesel,Motor_EGolf,Motor_Otto;
BO_TX_BU_ 1090 : Getriebe_DQ,Getriebe_DQ_Hyb,Getriebe_Sele;
BO_TX_BU_ 1352 : Getriebe_DQ,Getriebe_DQ_Hyb,Motor_EGolf;
CM_ SG_ 1578 Pumpe_HT_Ist "Info an das KBT über Ansteuerung der HT-Pumpe für Funktion und Thermomanagement";
CM_ SG_ 1578 Zustand_Pumpe_HT "Zustandsrückmeldung HT Wasserpumpe von MED an Klima";
CM_ SG_ 1578 Pumpe_NT_Ist "Info an das KBT über Ansteuerung der NT-Pumpe für Funktion und Thermomanagement";
CM_ SG_ 1578 Zustand_Pumpe_NT "Zustandsrückmeldung NT Wasserpumpe";
CM_ SG_ 1578 Ventil_HT_Kreis_Diagnose "Diagnoseinformation des 3/2 Wegeventils im HT Absperrkreis";
CM_ SG_ 1578 Ventil_HT_Kreis_Pos "Positionsrückmeldung des Ventils HT-Kreislauf für Klima-SG";
CM_ SG_ 1578 Ventil_Bat_Diagnose "Diagnoseinformation des 3/2 Wegeventils für die HV-Batterie";
CM_ SG_ 1578 Ventil_Bat_Pos "Positionsrückmeldung des Ventils HV-Batterie für Klima-SG";
CM_ SG_ 1578 Ventil_vor_EM_Diagnose "Diagnoseinformation des 3/2 Wegeventils vor der E-Maschine";
CM_ SG_ 1578 Ventil_vor_EM_Pos "Positionsrückmeldung des Ventils vor der E-Maschine für Klima-SG";
CM_ SG_ 1578 Temp_vor_PTC "Wassertemperatur vor PTC";
CM_ SG_ 1578 Temp_nach_WT "Wassertemperatur nach Wärmetauscher";
CM_ SG_ 1578 Temp_nach_Chiller "Wassertemperatur nach Chiller";
CM_ SG_ 1578 Temp_nach_LE "Wassertemperatur nach Leistungselektronik";
CM_ SG_ 1578 Temp_nach_EM "Wassertemperatur nach E-Maschine und Ausgleichsbehälter";
CM_ SG_ 1514 EFAS_Weckzeit_Set_Reset "Weckzeit im GSM setzen oder löschen";
CM_ SG_ 1514 EFAS_Jahr "0 für Datum unbekannt (z.B. keine Funkuhr)
(bei relativem Datum ist auch der Wert 0 gültig siehe Spezifikation_Tageszähler_Kombi_01.doc)";
CM_ SG_ 1514 EFAS_Monat "0 = Monat unbekannt
Dh = ungueltig
Eh = relatives Datum siehe Spezifikation_Tageszähler_Kombi_01.doc
Fh = Keine Funkuhrinformation vorhanden und 12 h Anzeige (Monat, Tag, Jahr fehlen)";
CM_ SG_ 1514 EFAS_Tag "0 für Datum unbekannt (z.B. keine Funkuhr)
(bei relativem Datum ist auch der Wert 0 gültig siehe Spezifikation_Tageszähler_Kombi_01.doc)";
CM_ SG_ 1514 EFAS_Stunde "18h - 1Fh ungueltig";
CM_ SG_ 1514 EFAS_Minute "3Ch - 3Fh ungueltig";
CM_ SG_ 1526 EK1_Comp_main_stat "Real compressor status not CAN board status";
CM_ SG_ 1526 EK1_Comp_SCI_com_stat "'00' normal
'x1' CAN_error (abnormal)
'1x' Inverter_error";
CM_ SG_ 1526 EK1_Comp_ovld_stat "Diagnosis series 1 'Over load'
'0' normal
'2' current restriction
'3' software over current
'4' over load
'6' over input current";
CM_ SG_ 1526 EK1_Comp_output_stat "Diagnosis series 1 'Output'
'0' normal
'1' output line short
'2' output line cut out
'3' abnormal current detection";
CM_ SG_ 1526 EK1_Comp_photo_temp_stat "Diagnosis series 2 'Inverter temp.'
'0' normal
'1' over heat L
'2' over heat S
'3' sermister abnormal";
CM_ SG_ 1526 EK1_Comp_Inv_stat "Diagnosis series 2 'Startability'
'0' normal
'1' start fail
'2' temp protection
'3' system abnormal stop";
CM_ SG_ 1526 EK1_KD_Fehler "Mind. ein Kundendienstfehler ist eingetragen";
CM_ SG_ 1526 EK1_Comp_rev_stat "compressor real revolution
0-8624 rpm is outputted
'output = (actual speed + 25) / 50' speed over 8625rpm: '172'";
CM_ SG_ 1526 EK1_Comp_current "Compressor input current";
CM_ SG_ 1526 EK1_Comp_photo_temp "IGBT temp. measured by inverter.;Photo coupler temp. is not measured in compressor temp. of IGBT (same as EK1_Comp_Inv_temp) will be sent";
CM_ SG_ 1406 EY1_KD_Fehler "Info für Diagnose
bei gesetztem Bit befindet sich mindestens ein Kundendienstfehler im Fehlerspeicher";
CM_ SG_ 1472 EP1_Zaehler "Freilaufender Botschaftszähler";
CM_ SG_ 1472 EP1_Fehler_Sta "Fehlerstatus Parkbremse";
CM_ SG_ 1472 EP1_Sta_EPB "Gibt den Zustand der EPB-Aktuatoren an. Verknüpfung mit Fehlerstatus; wenn z.B. 'Linke Seite Fehlerhaft' und 'Bremse geschlossen', dann ist nur die rechte Seite geschlossen. Das Bit gesetzt, wenn auf einer Seite Spannkraft aufgebaut wird. Wenn auf beiden ";
CM_ SG_ 1472 EP1_Sta_Schalter "Auch bei vollen Funktion kann kurzfristig ein Schalterfehler vorliegen
Schalterstatus Parkbremse";
CM_ SG_ 1472 EP1_Spannkraft "Erzeugte Spannkraft. Bezieht sich auf die Aktuatoren";
CM_ SG_ 1472 EP1_Schalterinfo "Spiegelt die Schalterstellung wider
Schalterinfo Parkbremse";
CM_ SG_ 1472 EP1_Sta_NWS "Funktion des Neigungswinkelsensors
1: Dauerhafter Ausfall oder Fehler Neigungswinkelgeber
Status Neigungswinkelgeber";
CM_ SG_ 1472 EP1_Neig_winkel "Neigungswinkelsignal";
CM_ SG_ 1472 EP1_Verzoegerung "Steuerungsanforderung an andere Systeme (z.B. ESP), um während der Fahrt, durch den Handbremsschalter ausgelöst, zu Bremsen (ECD-Funktion).
Verzoegerungsanforderung (EPB)";
CM_ SG_ 1472 EP1_Fehlereintr "Bei gesetztem Bit ist mindestens ein Kundendienstfehler eingetragen";
CM_ SG_ 1472 EP1_Freigabe_Ver "Freigabe Verzögerungs-Anforderung";
CM_ SG_ 1472 EP1_AutoHold_zul "Mit diesem Bit soll das Kombi den Menüpunkt 'Auto Hold' zur Verfügung stellen und das Bit 'Auto Hold umschalten' (Kombi_3, Byte 3, Bit 6) bedienen.
(geplant für PQ46 ab 22/08, VW469)
Personalisierung Auto Hold zulässig";
CM_ SG_ 1472 EP1_AutoHold_aktiv "Funktion 'Auto Hold' ist in der EPB aktiviert und wird im Kombi zur Anzeige gebracht (nur gültig, wenn Byte 5, Bit 2 Personalisierung zulässt)
(geplant für PQ46 ab 22/08, VW469)
Auto Hold aktiviert";
CM_ SG_ 1472 EP1_SleepInd "Sleep Indication
NMHigh-Teilnehmer der PQ35/46 müssen das Signal nach Kl.-15 aus weiterhin bedienen oder dauerhaft auf 1 = 'Sleep bereit' setzen!";
CM_ SG_ 1472 EP1_Status_Kl_15 "Klemme 15 am EPB-Steuergerät
Statusbit Klemme 15";
CM_ SG_ 1472 EP1_Lampe_AutoP "Fahrerwunsch 'Auto Hold': im Stillstand wird die Parkstellung eingenommen (nur im PQ46)
Funktionslampe Auto Hold";
CM_ SG_ 1472 EP1_Bremslicht "Bremslichtansteuerung bei dynamischer Abbremsung (nur im PQ46)";
CM_ SG_ 1472 EP1_Warnton1 "PQ46-Kombi löst einmal Warnton aus
wird nur zusammen mit gelber Fehlerlampe (Byte 7, Bit 3) gesetzt";
CM_ SG_ 1472 EP1_Warnton2 "PQ46-Kombi löst dreimal Warnton
wird zusammen mit roter Fehlerlampe (Byte 7, Bit 2) gesetzt";
CM_ SG_ 1472 EP1_AnfShLock "EPB kann manuell nur bei betätigter Fußbremse geöffnet werden. Wenn Bit gesetzt ist zeigt PQ46-Kombi die Shift-Lock-Lampe an
Anforderung Shift-Lock-Lampe";
CM_ SG_ 1472 EP1_Auto_Schl_Oe "Automatisches schließen/öffnen' der EPB: z. Zt. nur bei Audi für CVT-Getriebe Projekte
Automatisches Schließen, Öffnen erlaubt";
CM_ SG_ 1472 EP1_QualNeigWi "Mitteilung z. Zt. für ACC um unter bestimmten Zuständen mitzuteilen, dass Neigungswinkel temporär ungültig ist.
Beispiel: Selbsttest Neigungswinkelsensor
Erstmalig Audi C6
Qualifizierungsbit Neigungswinkel";
CM_ SG_ 1472 EP1_KuppModBer "Nur für Handschalter. Wird auf 01 gesetzt, wenn das PWM-Signal des Kupplungspedalsensors im Bereich zwischen 80%-Signalpegel und Minimum liegt.
Der Zustand 10b kann derzeit nur von Audi bedient werden, da der PQ46-Sensor keine Plausibilisierung des Signa";
CM_ SG_ 1472 EP1_HydrHalten "Bit wird gesetzt, wenn das Fahrzeug im Auto-Hold-Modus hydraulisch gehalten wird
Hydraulisches Halten aktiv (Auto-Hold)";
CM_ SG_ 1472 EP1_Fkt_Lampe "Bit wird nur gesetzt, wenn volle Spannkraft auf beiden Seiten erreicht
PQ46: Bit wird gesetzt, wenn BKL direkt vom EPB-SG als Funktionslampe angesteuert wird";
CM_ SG_ 1472 EP1_Warnton "Bit wird gesetzt, wenn bei v > 0 eine Fahreranforderung schließen vorhanden ist (ECD angefordert)
PQ46-Kombi sendet Warnton (600 Hz) solange dieses Bit gesetzt ist
Warnton (EPB 1)";
CM_ SG_ 1472 EP1_Fehler_BKL "Die BKL dient als rote Fehlerlampe für die EPB. Sie wird vom EPB-SG aktiv ausgeschaltet.
(nicht PQ46)
Fehlerlampe (BKL)";
CM_ SG_ 1472 EP1_Fehler_gelb "Fehlerlampe für nicht 'liegenbleiberelevante' Fehler
Fehlerlampe (gelb)";
CM_ SG_ 1472 EP1__Text "0000 keine Textanzeige im Kombi
0001 Neigungswinkel zu groß (nicht PQ46)
0010 Parkbremse von Hand öffnen
0011 EPB in Diagnose (nicht PQ46)
0100 Bremspedal betätigen (wird solange angezeigt, wie Fahrer das Bedienteil drückt und Bremspedal nicht betätig";
CM_ SG_ 1472 EP1_Checksum "Prüfsumme mit Endwert 0x0, Definition im CAN Lastenheft (HS-CAN V4.2a, LS-CAN V1.42)";
CM_ SG_ 1626 FL1_KD_Fehler "mindestens ein Fehler ist im Kundendienstfehlerspeicher eingetragen
(separates FLA-SG Inhibit 200ms)";
CM_ SG_ 1626 FL1_FLA_aktiv "FLA aktiv
(separates FLA-SG Inhibit 200ms)";
CM_ SG_ 1626 FL1_ISP_defekt "FLA Innenspiegel defekt
interner Fehler
(separates FLA-SG Inhibit 200ms)";
CM_ SG_ 1626 FL1_Sensor_blockiert "FLA Sensor blockiert
Sichtbeeinträchtigung CMOS-Kamera
(separates FLA-SG Inhibit 200ms)";
CM_ SG_ 1626 FL1_Abblendursache "FLA Abblendursache
0x0 keine
0x1 entgegenkommendes Fahrzeug
0x2 vorausfahrendes Fahrzeug
0x4 Geschwindigkeitslimit unterschritten
0x8 Ort erkannt
0x10 Umgebungshelligkeit generell zu hell, Abblendlicht aus
0x20 Nebel erkannt
0x40 Übertemperatur Im";
CM_ SG_ 1626 FL1_Fernlicht_PWM "FLA PWM Vorgabe Fernlicht
(separates FLA-SG Inhibit 20ms)";
CM_ SG_ 1626 FL1_ISP_Lichtwert_vo "Innenspiegel: Lichtwert vorne
ISP Lichtwert vorne
(separates FLA-SG Inhibit 200ms)";
CM_ SG_ 1626 FL1_ISP_Lichtwert_hi "Innenspiegel: Lichtwert hinten
ISP Lichtwert hinten
(separates FLA-SG Inhibit 200ms)";
CM_ SG_ 1626 FL1_ISP_Himmelsrichtung "Himmelsrichtung Kompass im EC Spiegel
Wertebereich 0-29 (12°-Schritte, 0-348°)
12 x Wert [Grad]
0x1E nicht verfügbar / Init
0x1F Fehler
ISP Himmelsrichtung
(separates FLA-SG Inhibit 200ms)";
CM_ SG_ 1626 FL1_ISP_Taste "Innenspiegel Taste betätigt
ISP Taste betätigt
(separates FLA-SG Inhibit 200ms)";
CM_ SG_ 1626 FL1_ISP_EC_aktiv "Status Innenspiegel (EC-Spiegel)
ISP EC aktiv
(separates FLA-SG Inhibit 200ms)";
CM_ SG_ 1626 FL1_ISP_Kompass_aktiv "Status Kompass Innenspiegel
ISP Kompass aktiv
(separates FLA-SG Inhibit 200ms)";
CM_ SG_ 1626 FL1_Dimmwert_ASP "Dimmwertvorgabe für Aussenspiegel
0x0 - 0x3E = Dimmwert (0-62 = 0-100%)
ISP Dimmwert ASP
(separates FLA-SG Inhibit 20ms)";
CM_ SG_ 1626 FL1_FLA_Aufblenden "FLA Aufblenden
(separates FLA-SG Inhibit 20ms)";
CM_ SG_ 912 GK1_Sta_RDK_Warn "RDK-Botschaft nicht empfangen (1,6 s/200 ms)";
CM_ SG_ 912 GK1_Sta_Anhaen "Anhänger-Botschaft nicht empfangen (1,6 s/200 ms)

Veraltet-Bit für die Signale:
Byte 6, Bit 6
Byte 6, Bit 7 ";
CM_ SG_ 912 GK1_Sta_Licht1 "Licht-Botschaft nicht empfangen (100 ms)";
CM_ SG_ 912 GK1_Sta_Licht3 "Licht_hinten-Botschaft nicht empfangen (200 ms nur Audi)
mLicht_3-Botschaft veraltet (2 s Colorado)
reserviert im PQ35/46 (Init 0 im PQ35/46)";
CM_ SG_ 912 GK1_Sta_Tuerkont "mBSG_Kombi-Botschaft nicht empfangen (100 ms)

Veraltet-Bit für die Signale:
Byte 3, Bit 0 GK1_Fa_Tuerkont
Byte 4, Bit 0 BCM_Remotestart_Betrieb
Byte 4, Bit 1 BCM_Offroad_Taster
Byte 4, Bit 2 BSK_HL_geoeffnet
Byte 4, Bit 3 BSK_HR_geoeffnet
Byte 6,";
CM_ SG_ 912 GK1_Sta_Li_vorn "Licht_vorne-Botschaft nicht empfangen (2 s, nur Audi)
reserviert im PQ35/46 (Init 0 im PQ35/46)";
CM_ SG_ 912 GK1_SleepAckn "Nach Empfang des 'Sleep-Acknowledge' (Klemme 15 aus) muß der Sendebetrieb sofort eingestellt werden
Die CAN-Schnittstelle (empfangseitig) wird nach der Wartezeit (750 ms) komplett abgeschaltet (nicht Colorado)
Touareg GP u. D1GP setzen das Bit nach 'Kl.";
CM_ SG_ 912 GK1_CharismaModus "Charisma-Modus
Nur gültig, wenn GK1_SamFktNr auf den Wert 1 gesetzt ist
";
CM_ SG_ 912 GK1_EfficiencyModus "Efficiency-Modus
Nur gültig, wenn GK1_SamFktNr auf den Wert 2 gesetzt ist
";
CM_ SG_ 912 GK1_SportModus "Sport-Modus
Nur gültig, wenn GK1_SamFktNr auf den Wert 3 gesetzt ist
";
CM_ SG_ 912 GK1_DriveSelectModus_1 "DriveSelect-Modus 1
Nur gültig, wenn GK1_SamFktNr auf den Wert 4 gesetzt ist
";
CM_ SG_ 912 GK1_DriveSelectModus_2 "DriveSelect-Modus 2
Nur gültig, wenn GK1_SamFktNr auf den Wert 5 gesetzt ist
";
CM_ SG_ 912 GK1_SamFktNr "Sammelfunktions-Nr.
Die gültigen SF werden mit jeder neuen Botschaft hochgezählt. Bei Änderung wird mit Inhibit 50ms das Hochzählen mit der entsprech. SF-Nr. unterbrochen.";
CM_ SG_ 912 GK1_Fa_Tuerkont "Status der Drehfalle Fahrertuer";
CM_ SG_ 912 GK1_RueckfahrSch "Info wird aus 'ILM_Fahrer_1', Byte 2, Bit 1 (nur bei Audi) entnommen
Rückfahrlichtschalter";
CM_ SG_ 912 GK1_ELV_verrieg "ELV im Zustand verriegelt
Für das Signal in der mELV_Kessy_WFS [0x373] gilt: Signal erst nach Rücksprache mit ELV Funktionsverantwortung nutzen.";
CM_ SG_ 912 GK1_Sta_Kessy_2 "Kessy 2 (400 msec Col.), mELV_Kessy_WFS (200 msec PQ46), mELV_1 (2000msec PQ35/PQ25) wird nicht empfangen";
CM_ SG_ 912 GK1_Sta_Stdhzg "mStheizung_1 wird nicht empfangen (400 ms)";
CM_ SG_ 912 GK1_SH_Verbau "1 = Steuergeraet ist Standheizung, d.h. kann auch ohne Klemme 15 heizen
0 = Steuergeraet ist Zuheizer, d.h. kann nur mit Klemme 15 betrieben werden
Status (Verbau) SH-Steuergeraet";
CM_ SG_ 912 GK1_ParkFrontWi "1= Frontwischer in Parklage";
CM_ SG_ 912 GK1_KW_Warm "Bit zeigt an, dass die Standheizung das Wasser im Heizungskreislauf erwaermt hat und dieses in den Kuehlkreislauf des Motors abgibt bzw. kuerzlich abgegeben hat.
Kuehlwasser erwaermt";
CM_ SG_ 912 BCM_Remotestart_Betrieb "Anforderung Remotestartbetrieb";
CM_ SG_ 912 BCM_Offroad_Taster "Zeigt die Betätigung des am BCM angeschlossenen Offroad-Tasters";
CM_ SG_ 912 BSK_HL_geoeffnet "Status der Drehfalle Tuer hinten links";
CM_ SG_ 912 BSK_HR_geoeffnet "Status der Drehfalle Tuer hinten rechts";
CM_ SG_ 912 GK1_Rueckfahr "1 = Rueckfahrlicht ein";
CM_ SG_ 912 GK1_BrLi_links "1 = defekt
Bremsleuchte hinten links defekt (s. Gateway Komfort 1)";
CM_ SG_ 912 GK1_BrLi_rechts "1 = defekt
Bremsleuchte hinten rechts defekt (s. Gateway Komfort 1)";
CM_ SG_ 912 GK1_BrLi_mitte "1 = defekt
3. Bremsleuchte defekt (s. Gateway Komfort 1)";
CM_ SG_ 912 GK1_BLS_ILM "Bremse 1, Byte 2, Bit 3 widerspricht der Hardware-Leitung vom BLS zum ILM hinten (nur bei Audi): Info wird aus 'Licht hinten' entnommen
BLS ILM unplausibel";
CM_ SG_ 912 GK1_EDC_ILM "Bremse 5, Byte 7, Bit 3 widerspricht der Hardware-Leitung vom ESP zum ILM hinten (nur bei Audi): Info wird aus 'Licht hinten' entnommen
ECD ILM unplausibel";
CM_ SG_ 912 GK1_Blinker_li "Richtungsblinken links betaetigt (s. Gateway Komfort)";
CM_ SG_ 912 GK1_Blinker_re "Richtungsblinken rechts betaetigt (s. Gateway Komfort)";
CM_ SG_ 912 GK1_def_P_verr "1 = Defekt des P-Verriegelt-Schalters erkannt
0 = P-Verriegelt-Schalter o.K
eine Anzeige im Kombi soll mit diesem Bit realisiert werden.
Defekterkennung des Park Verriegeltschalters im Waehlhebel";
CM_ SG_ 912 GK1_LS1_Fernlicht "Fernlichtschalter
PQ25: Das Signal wird nur bei verbautem BCM-Licht aktiv bedient. Das Signal kennzeichnet die Betätigung der Lichthupe oder des Fernlichtes.";
CM_ SG_ 912 GK1_Sta_Licht2 "Licht 2-Botschaft wird nicht empfangen (2 s)
ACHTUNG: Quellbotschaft kommt als Event! Keine Ausfalldiagnose möglich!";
CM_ SG_ 912 GK1_Sta_LSM "LSM-Botschaft wird nicht empfangen (200 ms)";
CM_ SG_ 912 WI1_Front_Wasch "1 = Wascherpumpe Front aktiv";
CM_ SG_ 912 BSK_BT_geoeffnet "Status der Drehfalle Beifahrertuer";
CM_ SG_ 912 BCM_CV_Taster "Zeigt die Betätigung des am BCM angeschlossenen Tasters zur Umschaltung des CV-Sensors";
CM_ SG_ 912 BSK_HD_Hauptraste "Status der Heckdeckel-Hauptraste";
CM_ SG_ 912 GK1_Anhaenger "1 = Anhaenger erkannt
Anhaenger erkannt (Gateway Komfort 1)";
CM_ SG_ 912 GK1_BrLi_Anhaen "1 = Anhaenger Bremslicht defekt
Anhaenger Bremslicht defekt (s. Gateway_Komfort_1)";
CM_ SG_ 912 GK1_Abblendlicht "Statusmeldungen fuer Anzeige im Kombi
Kl56b Abblendlicht ein";
CM_ SG_ 912 GK1_Fernlicht "1 = Licht ein
Kl56a Fernlicht ein
PQ25: Das Signal wird nur bei verbautem BCM-Licht aktiv bedient";
CM_ SG_ 912 GK1_Wischer_vorn "1 = Frontwischer aktiv, d.h. Intervall / Regensensor / Sufe1 / Stufe2, d.h. Wischer ist in Bewegung";
CM_ SG_ 912 GK1_Sta_ILM_F_1 "ILM_Fahrer_1-Botschaft nicht empfangen (2 s)
Wischer_1 Botschaft nicht empfangen (400 msec)
ILM_Fahrer_1 veraltet / Wischer 1 veraltet";
CM_ SG_ 912 GK1_Abbl_VL_def "1 = defekt
Abblendlicht vorne links defekt";
CM_ SG_ 912 GK1_Abbl_VR_def "1 = defekt
Abblendlicht vorne rechts defekt";
CM_ SG_ 912 GK1_Blink_Autob "Aktueller Zustand aus Blinkmodi-Botschaft entnommen
Blinken_Autobahn";
CM_ SG_ 912 GK1_Warnblk_Status "1 = solange Warnblinken aktiviert ist
0 = kein Warnblinken aktiv
Statische Anzeige Warnblinklicht ist eingeschaltet";
CM_ SG_ 912 GK1_SH_laeuft "Nur im D3 wird diese Info auch aus 'Klima1_D3' entnommen
Standheizung läuft";
CM_ SG_ 912 SH1_ein_Wasserpumpe "1 = Wasserpumpe der Standheizung (gesteuert von der Climatonic) einschalten";
CM_ SG_ 912 GK1_Nebel_ein "1 = Nebelscheinwerfer eingeschaltet
Kl83a Nebellicht ein";
CM_ SG_ 912 GK1_Bremslicht "1 = Bremslicht eingeschaltet";
CM_ SG_ 912 GK1_Anh_abgesteckt "Aktueller Zustand des Anhängers wird aus Anhänger-Botschaft entnommen
Anhänger abgesteckt";
CM_ SG_ 912 GK1_AnhKonLamp "Akt. Zustand der Anhängerblinklampe (Taktsignal) wird aus BSG-Botschaft entnommen (nur T5)
Kontrolllampe Anhänger";
CM_ SG_ 912 LDS_Stellung_AFL "Nur im Q7: Lichtdrehschalterstellung Auto";
CM_ SG_ 912 GK1_SH_Zusatzfkt "Zusatzfunktionen der Standheizung sind verfügbar, wenn DLC von mStHeizung_1 >=7";
CM_ SG_ 914 GK2_Sta_LSM "LSM-Botschaft wird nicht empfangen (200 ms)";
CM_ SG_ 914 GK2_Sta_Lichtsensor "mLichtsensor_1 - Botschaft nicht empfangen (100 msec) oder mRegen_Licht_Sensor-Botschaft nicht empfangen (200 msec)";
CM_ SG_ 914 GK2_Sta_Licht1 "Licht-Botschaft nicht empfangen (100 ms)";
CM_ SG_ 914 GK2_Sta_VSG "VSG - Botschaft nicht empfangen (200 msec)";
CM_ SG_ 914 GK2_Sta_Schluessel "Botschaft für Fahrberechtigungsschlüssel (Verweis auf Wegfahrsperre) nicht empfangen (200 msec)";
CM_ SG_ 914 GK2_Sta_Profil "Botschaft für Profilnummer nicht empfangen (2000 msec)";
CM_ SG_ 914 GK2_Sta_Clima2 "mClima2-Botschaft nicht empfangen (1600 ms)";
CM_ SG_ 914 GK2_Sta_BSG4 "mBSG4-Botschaft nicht empfangen (1000ms)";
CM_ SG_ 914 GK2_Sta_Kessy_4 "mKessy_4-Botschaft nicht empfangen (400 msec) (PQ35, PQ25)
mELV_Kessy_WFS-Botschaft nicht empfangen (200msec) (VW47x)

Veraltet-Bit für die Signale:
KY4_Kessy_StSt_Info";
CM_ SG_ 914 BS4_Gleitende_Leuchtw_Anf "Funktion 'Gleitende Leuchtweite' im AFS-SG  freischalten";
CM_ SG_ 914 BS4_GLW_Fernlicht_Anf "Harte Fernlichtanforderung von BCM an die Funktion 'gleitende Leuchtweite' im AFS-SG";
CM_ SG_ 914 GK2_Blk_L_Kontrolle "1 = Kontrollampe Blinker links ein
0 = Kontrollampe Blinker links aus
Ansteuerung Blinkerkontrollampe links";
CM_ SG_ 914 GK2_Blk_R_Kontrolle "1 = Kontrollampe Blinker rechts ein
0 = Kontrollampe Blinker rechts aus
Ansteuerung Blinkerkontrollampe rechts";
CM_ SG_ 914 GK2_LS_KomFehler "Veraltetinformation. Der LIN Master setzt dieses Bit, wenn er aktuell keine Daten vom Slave erhalten hat. (z.B. Hochlauf, Nachlauf, Kommunikationsfehler)
Lin Information veraltet";
CM_ SG_ 914 GK2_LS_def "Lichtsensor ist defekt. Signal wird vom Master gesetzt, wenn keine Daten vom Lichtsensor bei aktiver Kommunikation vorliegen";
CM_ SG_ 914 GK2_Helligkeit "Signale bilden die Helligkeit, die der Lichtsensor empfaengt
Helligkeitsinformation in LUX";
CM_ SG_ 914 GK2_VD_zu_ver "1 = Zustand des Verdecks verriegelt und geschlossen";
CM_ SG_ 914 GK2_VD_entriegelt "Verrriegeltzustand des Verdeck bzw. des Verdeckkastendeckel (VDKD)";
CM_ SG_ 914 GK2_VD_offen_ver "1 = Zustand des Verdecks geoeffnet und abgelegt (In Ablage verriegelt)";
CM_ SG_ 914 GK2_Verdeck_Anf "1 = Verdeck nicht in den Zustaenden 'geschlossen verriegelt' oder 'offen verriegelt'";
CM_ SG_ 914 GK2_VDKD_auf "Signal wird gesetzt, wenn der Verdeckkastendeckel vollstaendig geoeffnet ist";
CM_ SG_ 914 GK2_Schluessel "0 = ungueltig, xxxx = Schluessel-Nr.
Schluesselinformation (s. Kombi_3)";
CM_ SG_ 914 GK2_Hardtop "1 = Hardtop ist montiert";
CM_ SG_ 914 GK2_AFL_Schalter "1 = Schalter in Stellung Assistenzfahrlicht";
CM_ SG_ 914 GK2_Nebelschluss "1 = Nebelschlusslicht eingeschaltet
Kl83b Nebelschlussleuchte ein
PQ25: Das Signal wird nur bei verbautem BCM-Licht aktiv bedient";
CM_ SG_ 914 GK2_EM_LIN_ungueltig "Energie-Lin-Signale sind ungültig vom Slave Batteriedatenmodul oder Generator
0 = Signale gültig
1 = Signale ungültig";
CM_ SG_ 914 GK2_Profil "aktuelle Profilnummer";
CM_ SG_ 914 GK2_Kl_StSt_Info "Stopp-Freigabe/Start-Anforderung für den Start-Stopp-Koordinator";
CM_ SG_ 914 GK2_BSG_StSt_Info "Stopp-Freigabe/Start-Anforderung für den Start-Stopp-Koordinator";
CM_ SG_ 914 GK2_BEM_P_Generator "Mechanische Generatorleistung dient dem Motorsteuergerät zur Berechnung der Motorlast; Genauigkeit ca. +/- (500W + 20% vom Messwert)";
CM_ SG_ 914 GK2_BEM_Abschaltstufen "Abschaltstufen des Ruhestrommanagements (Initialisierungswert aus EEprom)
0 = Stufe 0 (keine Einschraenkungen)
1 = Stufe 1
2 = Stufe 2
3 = Stufe 3";
CM_ SG_ 914 GK2_BEM_DFM "Generatorauslastungsgrad, vom Generator über LIN an das Gateway gesandt. Das Motorsteuergerät regelt auf dieses Signal die PTC, das Energiemanagement im BSG/BCM kalkuliert die Bordnetzauslastung";
CM_ SG_ 914 GK2_Kessy_StSt_Info "Stopp-Freigabe/Start-Anforderung für den Start-Stopp-Koordinator
Wert 1:
- Schlüssel nicht gefunden bei KL15=EIN
- Transponderstart
- Antennenfehler (Kessy defekt)";
CM_ SG_ 914 GK2_BEM_StSt_Info "Stopp-Freigabe/Start-Anforderung für den Start-Stopp-Koordinator";
CM_ SG_ 914 BEM_Segel_Info "0: keine Anforderung
(Segeln ist ohne Einschänkung erlaubt)
1: Mindestdrehzahl 1
(Segeln ist mit Einschänkung erlaubt)
2: Mindestdrehzahl 2
(Segeln ist mit Einschänkung erlaubt)
3: Segelveto
(Segeln ist nicht erlaubt)";
CM_ SG_ 914 LS1_FAS_Taster "1 = Bedientaster fuer Fahrerassistenzsysteme betätigt";
CM_ SG_ 914 LS1_Fehler_FAS_Taster "Fehler in Bedientaster fuer Fahrerassistenzsysteme";
CM_ SG_ 915 GK3_Sta_Kessy_4 "mKessy_4-Botschaft nicht empfangen (400 msec)";
CM_ SG_ 915 GK3_Sta_HD_1 "Veraltet-Bit für Botschaft mHeckdeckel_1 (400ms nicht empfangen)";
CM_ SG_ 915 GK3_Sta_Memory_1 "mMemory_1-Botschaft nicht empfangen (1000ms)";
CM_ SG_ 915 GK3_KY4_Meldungen "Kessy-Meldungen:
0 = keine Meldung
1 = Meldung: 'Schlüssel nicht gefunden!' bei Kl.15 ein
2= Meldung: 'Schlüssel im Kofferraum!'
3 = Meldung: 'Schlüssel im Fahrzeug'
4 = Meldung: 'KESSY defekt'
5-15: tbd";
CM_ SG_ 915 GK3_KY4_Gong_600 "Gong zum Meldungstext (1=aktiv)";
CM_ SG_ 915 GK3_KY4_PassAL_Menue "1 = Menue-Eintrag 'Passiv Autolock / Autounlock' aktivieren";
CM_ SG_ 915 GK3_KY4_PassAL_akt "1 = Funktionszustand im Kessy-SG: 'Passiv Autolock / Autounlock'";
CM_ SG_ 915 GK3_BK1_IDGeb_1_Sta "ID Geber 1 Status Authentifizierung (0 = keine Antwort, 1 = authentifiziert, 2 = UHF Antwort, aber nicht authentifiziert, 3 - 7 tbd.)";
CM_ SG_ 915 GK3_BK1_IDGeb_2_Sta "ID Geber 2 wurde authentifiziert (0 = keine Antwort, 1 = authentifiziert, 2 = UHF Antwort, aber nicht authentifiziert, 3 - 7 tbd.)";
CM_ SG_ 915 ME1_EasyEntry_Menu "Easy-Entry-Funktion im Memorysitz verfügbar/nicht verfügbar";
CM_ SG_ 915 ME1_EasyEntry_aktiv "Rückmeldung vom Sitz-Memory-SG an das Kombi-SG (MFA), dass die Easy-Entry-Funktion für den Memorysitz aktiviert wurde.";
CM_ SG_ 915 GK3_BK1_IDGeb_3_Sta "ID Geber 3 wurde authentifiziert (0 = keine Antwort, 1 = authentifiziert, 2 = UHF Antwort, aber nicht authentifiziert, 3 - 7 tbd.)";
CM_ SG_ 915 GK3_BK1_IDGeb_4_Sta "ID Geber 4 wurde authentifiziert (0 = keine Antwort, 1 = authentifiziert, 2 = UHF Antwort, aber nicht authentifiziert, 3 - 7 tbd.)";
CM_ SG_ 915 GK3_BK1_Anlern_Info "1 = Anlernfunkschuß empfangen, Ergebnis in Byte 1+2 der mBCM_Kessy_1-Botschaft.";
CM_ SG_ 915 CL3_SH_Wasserpumpe "Anforderung zur Ansteuerung der SH- Wasserpunmpe im Restwaermebetrieb; 1 = Wasserpumpe ein; 0 = aus";
CM_ SG_ 915 MKE_Texte "Systemhinweis und Sicherheitshinweis für Anzeige im Kombi";
CM_ SG_ 915 HSA_unplausibel "Überblendung der Schaltanzeige im Kombi: vom Motorsteuergerät gesendete Informationen zur Darstellung der Schaltanzeige unplausibel";
CM_ SG_ 915 CHA_Kombi_Texte "Anzeige des aktuellen Charisma-Fahrprofiles im Kombi.
Die Texte werden HUT-Spezifisch in einem Schnittstellen-LAH definiert.";
CM_ SG_ 915 HD1_Position "Dieses Byte zeigt die Oeffnung des Heckdeckels in Prozent
VW428: Sonderwert 0xC8 kennzeichnet die obere Endlage oder eine nicht normierte Heckklappe.";
CM_ SG_ 921 GK1_Sta_LSM "LSM-Botschaft wird nicht empfangen (200 ms)";
CM_ SG_ 921 GK4_Sta_MFA_6 "MFA_6-Botschaft wird nicht empfangen (2000 ms)";
CM_ SG_ 921 LS1_P_verriegelt "Zustand der Zuendschluesselabzugssperre (entsprechend Waehlhebelstellung, aber ueber Draht vom Waehlhebel) Achtung kein weiterer Empfaenger als ELV, da Signal nicht sicher ermittelt werden kann.
Zustand P_verriegelt_Schalter Lenkschloss";
CM_ SG_ 921 GK4_Ladesteckerentr_Anf "Anforderung Ladestecker entriegeln nach ZV Auf Befehl";
CM_ SG_ 921 MA6_Reichweite "3FFF - Ungueltig -> Anzeige lt. HMI-Sezifikation
Gesamtreichweite Fahrzeug";
CM_ SG_ 921 MA6_km_Reichweite "1 = Gesamtreichweite Fahrzeug aus Bit 0...13 wird in km dargestellt
Einheit km";
CM_ SG_ 921 MA6_mls_Reichweite "1 = Gesamtreichweite Fahrzeug aus Bit 0...13 wird in Meilen dargestellt
Einheit mls";
CM_ SG_ 684 GS1_Zaehler "Definition nach CAN-Lastenheft";
CM_ SG_ 684 GS1_Fahrtrichtung "Fahrtrichtung";
CM_ SG_ 684 GS1_QBit_Rad_kmh "Definition nach CAN-Lastenheft
Qualifizierungsbit Geschwindigkeit";
CM_ SG_ 684 GS1_Rad_kmh "Low Byte 4, High Byte 5
Bremse holt sich den Radumfang aus der Botschaft 'Kombi_3'
ESP 5.7: Ausgegeben wird die Geschwindigkeit des linken Vorderrades
ESP 8 Quattro: 4 Räder
ESP 8 Front: 2 Räder VA
Bei MSR oder ASR-Eingriffen wird für >=200ms die ABS";
CM_ SG_ 684 GS1_Checksumme "Prüfsumme mit Endwert 0x0, Definition im CAN Lastenheft (HS-CAN V4.2a, LS-CAN V1.42)";
CM_ SG_ 1088 GE1_Schaltung "Schaltung aktiv (Getriebe 1)";
CM_ SG_ 1088 GE1_Sta_Schutz "Umschaltung permanente Leistungsreduzierung (Ein-spritzausblendung) oder Zündwinkelverstellung (Otto)

Hybrid: Langsamer Eingriff soll für Hybrid implementiert werden.
Status Getriebe und Wandlerschutz";
CM_ SG_ 1088 GE1_Klimakompr "Weiterleiten an Motor, der Klima ausschaltet
Klimakompressor aus (Getriebe 1)";
CM_ SG_ 1088 GE1_WK "auch für Anfahrkupplung beim VL30 und Kupplung beim Ecodrive (geregelt bedeutet in diesem Fall die Kupplung ist nicht vollständig getrennt bzw hat Schlupf) genutzt; bei starken Verstellwegen wird geöffnet gesendet (VQ250)
Wandlerkupplung";
CM_ SG_ 1088 GE1_StSt_Info "Stopp-Freigabe/Start-Anforderung für den Start-Stopp-Koordinator
(Verriegelt über Systemstatus Start/Stopp wegen ESP8 bei AUDI und ggf. alter Motoren: Getriebe darf nur einen Wert ungleich 0 senden, wenn mMotor_10 empfangen wurde und der 'Systemstatus St";
CM_ SG_ 1088 GE1_EGS_Anf "Byte 4 wird damit gültig
EGS-Anforderung";
CM_ SG_ 1088 GE1_Zielgang "Zielgang, wenn Schaltung aktiv
Zielgang oder eingelegter Gang";
CM_ SG_ 1088 GE1_Wahl_Pos "Wählhebelposition / Fahrprogramm

Bei Selespeed Bedeutung 'Fahrprogramm', da keine Wählhebelgasse vorhanden ist.
Empfänger erwartet 'P' wegen Zündschlüsselabzugsperre. Das Selespeed-Getriebe (automatisierter Handschalter) hat den Zustand 'P' nicht, bed";
CM_ SG_ 1088 GE1_Mrad_Mkurb "Mrad / Mkurbelwelle
Übertragungsfunktion";
CM_ SG_ 1088 GE1_Soll_Mo "Getriebeeingriff an den Motor

Hybrid: Getriebeeingriff auf indiziertes Moment (Absolutwert)
Inneres Soll-Motormoment";
CM_ SG_ 1088 GE1_Fahrwistd "auf % Steigung am Berg normiert
Fahrwiderstandsindex";
CM_ SG_ 1088 GE1_Notlauf "Notlauf:
0000B kein Notlauf; Gangwechsel=0; Zielgang erreicht=0
0001B kein Schalten
0010B Schalten nach n
0011B 50% Schalten
0100B Fahren ohne ÜK
0101B kein Notlauf; Gangwechsel=0; Zielgang erreicht=1
0110B kein Notlauf; Gangwechsel=1; Zielgang err";
CM_ SG_ 1088 GE1_Kuehlung "00: keine zusätzliche Kühlleistung
01: Lüfterleistung um 20% erhöhen
10: Lüfterleistung um 40% erhöhen, Wassertemp. ¿10
11: maximale Lüfterleistung; Wassertemp. Senken (max)
Kühlleistung";
CM_ SG_ 1088 GE1_Sta_OBD "Bit 7 steuert (nicht mehr Bit 6) die MIL-Lampe an (Motor-SG reicht diese Info an Kombi weiter)
OBD Status";
CM_ SG_ 1088 GE1_LaunchControl "Während einer LaunchControl-Anfahrt sendet das Getriebesteuergerät das Bit LaunchControl_aktiv. Die Bremse wertet dieses Bit aus, um während einer solchen Anfahrt die Regelgrenzen der Schlupfregelung zu erweitern (z. Zt. nur DQ250)
LaunchControl";
CM_ SG_ 1088 GE1_Infobit "CVT-Getriebe (VL30,..) setzen Bit auf 1
Sonstige Getriebe (z. B. Stufenautomat) geben 0 aus
Getriebeinfobit";
CM_ SG_ 1088 GE1_SleepInd "Die Sleep-Bereitschaft wird nach Klemme 15 aus durch Setzen dieses Bits signalisiert
NMHigh-Teilnehmer der PQ35/46 müssen das Signal nach Kl.-15 aus weiterhin bedienen oder dauerhaft auf 1 = 'Sleep bereit' setzen!";
CM_ SG_ 1088 GE1_Zaehler "Zähler läuft synchron mit dem Zähler in der Getriebe 2 Botschaft (zur Sicherstellung der Synchronität)
Botschaftszähler (Getriebe 1)";
CM_ SG_ 1088 GE1_Fehlereintr "Bei gesetztem Bit ist mindestens ein Kundendienstfehler eingetragen
Fehlerspeichereintrag (Getriebe 1)";
CM_ SG_ 1088 GE1_WaVerl_Mo "Kupplungsmoment bei ASG / DQ-Getriebe; wird als Vorsteuermoment für LFR genutzt
Gesamtes Aufnahmemoment des Getriebes
Hybrid: Kriechvorsteuerung soll bei Hybrid PL71 und PQ35 implementiert sein.
PL71H: im Low-Speed-Modus (elektrisch mit geschlossenem T";
CM_ SG_ 1344 GE2_LFR_Adap "Da das VL30-Getriebe im Stillstand unter gewissen Randbedingungen wechselnde Kupplungsmomente ein-stellt (z.B. Hillholder), sollte die Leerlauffüllungsadaption im Motorsteuergerät für diese Zustände gesperrt werden

Falls Senderkennung = 1 (MSG): Bedien";
CM_ SG_ 1344 GE2_Sta_SAS "Wenn die SAS-Unterstützung aktiv ist, wird vom VL30-Steuergerät sichergestellt, daß die Kupplung nicht schlagartig geöffnet wird.

Falls Senderkennung = 1 (MSG): Bedienung mit Initwert
Schubabschaltunterstützung";
CM_ SG_ 1344 GE2_SlipStDZEingr "(war 'Ecomatic')

Hybrid:
PL71H: Falls Bit 2 aktiv und Bit 3 nicht aktiv, dann wird ein DZ-Eingriff wegen einer Wiederstartanforderung durchgeführt: Byte 4, 5 und 6 sollen ausgeführt werden.
PL71H/PQ35H: Verwendung für DZ-Eingriff Low-Speed-Mode
DZ-E";
CM_ SG_ 1344 GE2_Sta_ZwGas "Byte 4,5 und 6 sollen ausgeführt werden

Hybrid:
Falls Bit 3 aktiv, dann sollen Byte 4, 5 und 6 ausgeführt werden.
- falls Bit 3 und Bit 2 aktiv: DZ-Vorgabe von Getriebe im Low-Speed-Modus (s. Byte 7 Bit 3 (Motor_Hybrid_1)).
- Falls Bit 3 aktiv und B";
CM_ SG_ 1344 GE2_Zaehler "Überwachung von Byte 4 und 5
Zähler läuft synchron mit Zähler in Getriebe 1
Bedienung unabhängig von Senderkennung
Botschaftszähler (Getriebe 2)";
CM_ SG_ 1344 GE2_LL_Solldz "Wunschvorgabewert vom CVT Getriebe, 5HP19, 5HP24 und ASG an Motor

Hybrid:
Getriebe kann auch im Low-Speed-Modus Verbrenner-LLSoll-DZ anfordern (Spiegelung Byte 6 aus Motor 2)

Falls Senderkennung = 1 (MSG): Bedienung mit Initwert
Leerlaufsolldrehza";
CM_ SG_ 1344 GE2_Grad_begr "Drehmomenten-Gradientenbegrenzung für Teillastanfahrten mit dem VL30-Getriebe und Standabkopplung beim 5HP19

Hybrid (Signal 'Gradientenbegrenzung Summenmoment'):
Soll für Summenmoment VM + EM gelten. Soll auch negative Gradienten (Rekuperation) gelten";
CM_ SG_ 1344 GE2_Sync_Dz "Drehzahlverhalten zu Schaltvorgang
(Bei Selespeed-Getriebe im AU714 größerer Wertebereich 0-8128 mit Auflösung 32/min)

Hybrid:
ASG-Drehschnittstelle soll bei Hybrid implementiert sein.
Neu: Soll auch tauglich sein für DZ-reduzierende Eingriffe!

F";
CM_ SG_ 1344 GE2_invSync_Dz "bitinvertiertes Byte 4
(Bei Selespeed-Getriebe im AU714 größerer Wertebereich 0-8128 mit Auflösung 32/min)

Hybrid:
ASG-Drehschnittstelle soll bei Hybrid implementiert sein.
Neu: Soll auch tauglich sein für DZ-reduzierende Eingriffe!
Falls Senderken";
CM_ SG_ 1344 GE2_Sync_Zeit "Falls Senderkennung = 1 (MSG): Bedienung mit Initwert
Synchronisationszeit";
CM_ SG_ 1344 GE2_DZM_Daempf "Beim Getriebe kann die Anzeigedämpfung des Drehzahlmessers beim Schalten geändert werden
Falls Senderkennung = 1 (MSG): Bedienung mit Initwert
Drehzahlmesserdämpfung";
CM_ SG_ 1344 GE2_invMSB_Sync "(war: 'Starter wird angesteuert')
bitinvertiertes Byte 7, Bit 6
Falls Senderkennung = 1 (MSG): Bedienung mit 0
Invertiertes MSB Synchronisations Wunschdrehzahl";
CM_ SG_ 1344 GE2_Gong "Wichtiger Warnhinweis vom Getriebe:
Textanzeige Kupplungstemperaturwarnung für DQ-Getriebe: 'Getriebe überhitzt Stopp Bordbuch'
(VW Text-ID: ID_TXT_2029.0)
Falls Senderkennung = 1 (MSG): Bedienung mit Initwert
Gong / Kupplungstemperaturwarnung";
CM_ SG_ 1344 GE2_Segeln_aktiv "(war 'Unterdrückung von Warnungen')
Getriebe geht in den Segelbetrieb, Antriebsstrang offen
Falls Senderkennung = 1 (MSG): Bedienung mit Initwert";
CM_ SG_ 1344 GE2_Shift_Lock "Wählhebel ist durch Shift-Lock Funktion blockiert
Falls Senderkennung = 1 (MSG): Bedienung mit Initwert
Shift-Lock-Lampe";
CM_ SG_ 1344 GE2_Senderkennung "(war 'ECO-Anzeige')
Die Botschaft Getriebe 2 wird vom Automatgetriebe gesendet, bei Handschaltern alternativ vom Motor. Das Getriebe stellt damit die Wählbereichsanzeige dar, der Motor beim Handschalter die Hochschaltaufforderung für den Fahrer im Kombi.";
CM_ SG_ 1344 GE2_MSB_Sync "(war: 'Anforderung Kriechadaptionsmodus');Bei gesetztem Bit sind zu der Synchronisationswunschdrehzahl in Byte 4 6400 /min (Selespeed 8192) zu addieren. Inverses Bit in Byte 7, Bit 1 beachten
Falls Senderkennung = 1 (MSG): Bedienung mit Initwert
MSB Syn";
CM_ SG_ 1344 GE2_WBA_Blinken "Dieses Bit steuert die Fehlerlampe an oder wird zum Blinken der WBA-Anzeige genutzt (5HP, 6HP, PNG, ASG, VL30)
Falls Senderkennung = 1 (MSG): Bedienung mit Initwert
Fehlerlampe für Kupplung / WBA Blinken";
CM_ SG_ 1344 GE2_Variante "Falls Senderkennung = 0 (GSG): Ganganzeige Kombi Getriebe Variante und eingelegter Gang:
vgl. Multiplex-Information. Übertragung 4x Getriebe-Variante (0x0 bis 0xE möglich), danach 4x der eingelegte Gang (0xFF)

Falls Senderkennung = 1 (MSG): Istgang
W";
CM_ SG_ 1344 GE2_5Gang "5-Gang Automat (PRND432)";
CM_ SG_ 1344 GE2_PRND "Automat (PRND) (4/5/6-Gang), z.B. CVT-Getriebe";
CM_ SG_ 1344 GE2_4Gang "4-Gang Automat (PRND321)";
CM_ SG_ 1344 GE2_ASG "ASG-Getriebe";
CM_ SG_ 1344 GE2_Selespeed "Selespeed-Getriebe
Besonderheit Selespeed:
0000: Es wird nur ein M angezeigt. Diese Anzeige erfolgt, wenn das Getriebe keine Gangposition bestimmen kann. Selespeed besitzt keine Normaldarstellung wie ein echter Automat. Die Fahrstufen M/S/A sind zueinan";
CM_ SG_ 1344 GE2_res_MUX5 "reserviert für Multiplexer Signal 5";
CM_ SG_ 1344 GE2_PRNDS "Automat (PRNDS) (4/5/6-Gang)";
CM_ SG_ 1344 GE2_PRNED "Automat (PRNED) (4/5/6-Gang)";
CM_ SG_ 1344 GE2_Tip4Gang "4 Gang Automat Tiptronic";
CM_ SG_ 1344 GE2_Tip5Gang "5 Gang Automat Tiptronic (auch im 3l Auto)";
CM_ SG_ 1344 GE2_res_MUX10 "reserviert für Multiplexer Signal 10";
CM_ SG_ 1344 GE2_PRNDB "für EGolf (Sender Motor)";
CM_ SG_ 1344 GE2_Tip6Gang "6 Gang Automat Tiptronic";
CM_ SG_ 1344 GE2_Tip7Gang "7 Gang Automat Tiptronic";
CM_ SG_ 1344 GE2_Tip8Gang "8 Gang Automat Tiptronic";
CM_ SG_ 1344 GE2_akt_Gang "Falls Senderkennung = 0 (GSG): aktuell eingelegter Gang/Fahrstufe bei Automatik-Getrieben
vgl. Wertetabelle

Falls Senderkennung = 1 (MSG): Motor sendet bei Handschaltern den Sollgang (Signal wird hierbei nicht von GE2_Variante gemuxt), in den der Fahr";
CM_ SG_ 1090 GM3_Checksum "Prüfsumme mit Endwert 0x0, Definition im CAN Lastenheft (HS-CAN V4.2a, LS-CAN V1.42)";
CM_ SG_ 1090 GM3_Zaehler "Freilaufender Botschaftszähler
Zähler (Getriebe_3_Momente)";
CM_ SG_ 1090 GM3_MomEingr "Freigabe-Bit z. Zt. nur für Luftpfad-Eingriff gültig: 'Eine möglichr Anforderung Momentenreduktion für Hochschaltungen kann umgesetzt werden', Näheres im Lastenheft Luftpfad

Hybrid:
PQ35H: parallel zu Byte 1 Bit 7 aus Getriebe 1.
Freigabe Momentenein";
CM_ SG_ 1090 GM3_MoSoMom "Hybrid:
Getriebeeingriff auf indiziertes Moment (Absolutwert).
- Reduzierendes Moment kann auch von EM erzeugt werden => Eingriff beinhaltet auch EMAnteile.
- Erhöhendes Moment kann auch von EM erzeugt werden => Eingriff beinhaltet auch EM-Anteile.
Mo";
CM_ SG_ 1090 GM3_StaSoMom "Status Sollmoment";
CM_ SG_ 1090 GM3_MomID "Zur Identifizierung der Moment-Zeit-Paare";
CM_ SG_ 1090 GM3_Zeit "Zeit des Moment-Zeit-Paares";
CM_ SG_ 1090 GM3_Moment "Moment des Moment-Zeit-Paares;Anmerkung: Der Faktor zur Normierung der Momente (0,25, 0,5, 1, 2) wird zukünftig aus der 'Motor_Momente'-Botschaft entnommen (vorrübergehend 1)";
CM_ SG_ 1090 GM3_QB_LangEingr "Definition nach CAN Lastenheft
Qualifizierungsbit Langfristiger Eingriff";
CM_ SG_ 1090 GM3_LangEingr "Getriebeschutzmoment
Langfristiger Eingriff";
CM_ BO_ 1352 "zukünftig Zykluszeit 20ms durchgängig für alle Projekte wg. Buslastreduzierung geplant
Für alte Getriebe-Projekte weiterhin 10ms erlaubt!";
CM_ SG_ 1352 GE4_Shiftlock "Shiftlockaktivierung";
CM_ SG_ 1352 GE4_AuslModus "Bei RDW ist die Ausleuchtungsdauer begrenzt (Wählhebel nicht in P)
Ausleuchtungsmodus für Wählhebel";
CM_ SG_ 1352 GE4_Test "Controllertest mit den Testparametern 1 + 2 durchführen
Testfreigabeflag";
CM_ SG_ 1352 GE4_Tasterausleuchtung "Ansteuerung der Ausleuchtung des WH Tasters z.B. S-Taste";
CM_ SG_ 1352 GE4_Ausleuchtung "Mit dieser Botschaft wird die aktive Istgangausleuchtung des Wählhebels gesteuert.
Wählhebelausleuchtung";
CM_ SG_ 1352 GE4_Testparam_1 "Testparameter 1 zum Funktionstest des Wählhebel-Controllers";
CM_ SG_ 1352 GE4_Testparam_2 "Testparameter 2 zum Funktionstest des Wählhebel-Controllers";
CM_ SG_ 1346 GE5_Test "Controllertest mit den Testparametern 1+2 durchführen
Testfreigabeflag";
CM_ SG_ 1346 GE5_Abschalten "Mit diesem Bit kann das Getriebe den Wählhebel im Fehlerfall deaktivieren. Der Wählhebel geht dann in einen Standby-Modus. Alle Wählhebelanzeigen blinken.
Wählhebelmodul abschalten";
CM_ SG_ 1346 GE5_Sta_Fahrstufe "Kann das Getriebe keine Information über die aktuell eingelegte Fahrstufe an den Wählhebel übergeben, so wird dieses Bit gesetzt. Am Wählhebel wird keine Fahrstufe angezeigt, solange das Bit gesetzt ist.
Fahrstufeninformation ungültig";
CM_ SG_ 1346 GE5_Ausl_Sport "Mit dieser Bit wird Ausleuchtung der Sportfunktion am Wählhebel gesteuert
Wählhebelausleuchtung Sport";
CM_ SG_ 1346 GE5_Ausl_Winter "Mit dieser Botschaft wird Ausleuchtung der Winterfunktion am Wählhebel gesteuert
Wählhebelausleuchtung Winter";
CM_ SG_ 1346 GE5_Ausleuchtung "Mit dieser Botschaft wird die aktive Istgangausleuchtung des Wählhebels gesteuert.
Wählhebelausleuchtung Istgang";
CM_ SG_ 1346 GE5_Testparam_1 "Testparameter 1 zum Funktionstest des Wählhebel-Controllers";
CM_ SG_ 1346 GE5_Testparam_2 "Testparameter 2 zum Funktionstest des Wählhebel-Controllers";
BA_DEF_ BO_  "GenMsgAutoGenDsp" ENUM  "No","Yes";
BA_DEF_ BO_  "GenMsgAutoGenSnd" ENUM  "No","Yes";
BA_DEF_ BO_  "GenMsgCycleTime" INT 0 65535;
BA_DEF_ BO_  "GenMsgCycleTimeFast" INT 0 65535;
BA_DEF_ BO_  "GenMsgDelayTime" INT 0 100000;
BA_DEF_ BO_  "GenMsgILSupport" ENUM  "No","Yes";
BA_DEF_ BO_  "GenMsgSendType" ENUM  "Cyclic","not_used","not_used","not_used","not_used","not_used","not_used","IfActive","NoMsgSendType";
BA_DEF_ BO_  "GenMsgStartDelayTime" INT 0 100000;
BA_DEF_ BO_  "NmMessage" ENUM  "No","Yes";
BA_DEF_ BO_  "NmhMessage" ENUM  "No","Yes";
BA_DEF_ BO_  "VAGTP20_API" HEX 0 255;
BA_DEF_ BO_  "VAGTP20_DynConnection" ENUM  "No","Yes";
BA_DEF_ BO_  "VAGTP20_DynSetup" ENUM  "No","Yes";
BA_DEF_ BO_  "VAGTP20_StatConnection" ENUM  "No","Yes";
BA_DEF_ BO_  "Timeoutzeit" INT 0 1000000;
BA_DEF_ BO_  "DiagRequest" ENUM  "No","Yes";
BA_DEF_ BO_  "DiagResponse" ENUM  "No","Yes";
BA_DEF_ BO_  "DiagState" ENUM  "No","Yes";
BA_DEF_ BO_  "GenMsgChkConstant" HEX 0 4095;
BA_DEF_ SG_  "GenSigAutoGenDsp" ENUM  "No","Yes";
BA_DEF_ SG_  "GenSigAutoGenSnd" ENUM  "No","Yes";
BA_DEF_ SG_  "GenSigEnvVarType" ENUM  "int","float","undef";
BA_DEF_ SG_  "GenSigInactiveValue" INT -2147483648 2147483647;
BA_DEF_ SG_  "GenSigSendType" ENUM  "Cyclic","OnWrite","OnWriteWithRepetition","OnChange","OnChangeWithRepetition","IfActive","IfActiveWithRepetition","NoSigSendType","OnChangeAndIfActive","OnChangeAndIfActiveWithRepetition";
BA_DEF_ SG_  "GenSigStartValue" INT -2147483648 2147483647;
BA_DEF_ SG_  "NWM-WakeupAllowed" ENUM  "No","Yes";
BA_DEF_ SG_  "GenSigFuncType" ENUM  "NoFunction","MsgCounter","CRC-8","XOR","XOR-2","DatedBit","SW-Kl15","CHK","Constant","Protocol";
BA_DEF_ SG_  "GenSigSwitchedByIgnition" ENUM  "No","Yes";
BA_DEF_ SG_  "Fehlerwert" HEX 0 2147483647;
BA_DEF_ SG_  "GenSigMissingSourceValue" HEX 0 2147483647;
BA_DEF_REL_ BU_SG_REL_  "GenSigTimeoutTime" INT 0 65535;
BA_DEF_DEF_REL_ "GenSigTimeoutTime" 0;
BA_DEF_DEF_  "GenMsgAutoGenDsp" "Yes";
BA_DEF_DEF_  "GenMsgAutoGenSnd" "Yes";
BA_DEF_DEF_  "GenMsgCycleTime" 0;
BA_DEF_DEF_  "GenMsgCycleTimeFast" 0;
BA_DEF_DEF_  "GenMsgDelayTime" 0;
BA_DEF_DEF_  "GenMsgILSupport" "No";
BA_DEF_DEF_  "GenMsgSendType" "NoMsgSendType";
BA_DEF_DEF_  "GenMsgStartDelayTime" 0;
BA_DEF_DEF_  "NmMessage" "No";
BA_DEF_DEF_  "NmhMessage" "No";
BA_DEF_DEF_  "VAGTP20_API" 0;
BA_DEF_DEF_  "VAGTP20_DynConnection" "No";
BA_DEF_DEF_  "VAGTP20_DynSetup" "No";
BA_DEF_DEF_  "VAGTP20_StatConnection" "No";
BA_DEF_DEF_  "Timeoutzeit" 0;
BA_DEF_DEF_  "DiagRequest" "No";
BA_DEF_DEF_  "DiagResponse" "No";
BA_DEF_DEF_  "DiagState" "No";
BA_DEF_DEF_  "GenMsgChkConstant" 0;
BA_DEF_DEF_  "GenSigAutoGenDsp" "No";
BA_DEF_DEF_  "GenSigAutoGenSnd" "No";
BA_DEF_DEF_  "GenSigEnvVarType" "undef";
BA_DEF_DEF_  "GenSigInactiveValue" 0;
BA_DEF_DEF_  "GenSigSendType" "NoSigSendType";
BA_DEF_DEF_  "GenSigStartValue" 0;
BA_DEF_DEF_  "NWM-WakeupAllowed" "No";
BA_DEF_DEF_  "GenSigFuncType" "NoFunction";
BA_DEF_DEF_  "GenSigSwitchedByIgnition" "Yes";
BA_DEF_DEF_  "Fehlerwert" 0;
BA_DEF_DEF_  "GenSigMissingSourceValue" 0;
BA_ "GenMsgSendType" BO_ 1578 0;
BA_ "GenMsgCycleTime" BO_ 1578 1000;
BA_ "GenMsgSendType" BO_ 1514 0;
BA_ "GenMsgCycleTime" BO_ 1514 1000;
BA_ "GenMsgSendType" BO_ 1526 0;
BA_ "GenMsgILSupport" BO_ 1526 1;
BA_ "GenMsgCycleTime" BO_ 1526 500;
BA_ "GenMsgSendType" BO_ 1406 0;
BA_ "GenMsgILSupport" BO_ 1406 1;
BA_ "GenMsgCycleTime" BO_ 1406 1000;
BA_ "GenMsgSendType" BO_ 1472 0;
BA_ "GenMsgILSupport" BO_ 1472 1;
BA_ "GenMsgCycleTime" BO_ 1472 20;
BA_ "GenMsgSendType" BO_ 1626 0;
BA_ "GenMsgILSupport" BO_ 1626 1;
BA_ "GenMsgDelayTime" BO_ 1626 20;
BA_ "GenMsgCycleTime" BO_ 1626 1000;
BA_ "GenMsgSendType" BO_ 912 0;
BA_ "GenMsgDelayTime" BO_ 912 50;
BA_ "GenMsgCycleTime" BO_ 912 100;
BA_ "GenMsgSendType" BO_ 914 0;
BA_ "GenMsgDelayTime" BO_ 914 10;
BA_ "GenMsgCycleTime" BO_ 914 100;
BA_ "GenMsgSendType" BO_ 915 0;
BA_ "GenMsgDelayTime" BO_ 915 20;
BA_ "GenMsgCycleTime" BO_ 915 200;
BA_ "GenMsgSendType" BO_ 921 0;
BA_ "GenMsgCycleTime" BO_ 921 200;
BA_ "GenMsgSendType" BO_ 684 0;
BA_ "GenMsgILSupport" BO_ 684 1;
BA_ "GenMsgCycleTime" BO_ 684 20;
BA_ "GenMsgSendType" BO_ 1088 0;
BA_ "GenMsgILSupport" BO_ 1088 1;
BA_ "GenMsgCycleTime" BO_ 1088 10;
BA_ "GenMsgSendType" BO_ 1344 0;
BA_ "GenMsgILSupport" BO_ 1344 1;
BA_ "GenMsgCycleTime" BO_ 1344 10;
BA_ "GenMsgSendType" BO_ 1090 0;
BA_ "GenMsgILSupport" BO_ 1090 1;
BA_ "GenMsgCycleTime" BO_ 1090 10;
BA_ "GenMsgSendType" BO_ 1352 0;
BA_ "GenMsgILSupport" BO_ 1352 1;
BA_ "GenMsgCycleTime" BO_ 1352 20;
BA_ "GenMsgSendType" BO_ 1346 0;
BA_ "GenMsgILSupport" BO_ 1346 1;
BA_ "GenMsgCycleTime" BO_ 1346 10;
BA_ "GenSigSwitchedByIgnition" SG_ 1578 Pumpe_HT_Ist 0;
BA_ "GenSigSendType" SG_ 1578 Pumpe_HT_Ist 0;
BA_ "GenSigSwitchedByIgnition" SG_ 1578 Zustand_Pumpe_HT 0;
BA_ "GenSigSendType" SG_ 1578 Zustand_Pumpe_HT 0;
BA_ "GenSigSwitchedByIgnition" SG_ 1578 Pumpe_NT_Ist 0;
BA_ "GenSigSendType" SG_ 1578 Pumpe_NT_Ist 0;
BA_ "GenSigSwitchedByIgnition" SG_ 1578 Zustand_Pumpe_NT 0;
BA_ "GenSigSendType" SG_ 1578 Zustand_Pumpe_NT 0;
BA_ "GenSigSwitchedByIgnition" SG_ 1578 Ventil_HT_Kreis_Diagnose 0;
BA_ "GenSigSendType" SG_ 1578 Ventil_HT_Kreis_Diagnose 0;
BA_ "GenSigSwitchedByIgnition" SG_ 1578 Ventil_HT_Kreis_Pos 0;
BA_ "GenSigSendType" SG_ 1578 Ventil_HT_Kreis_Pos 0;
BA_ "GenSigSwitchedByIgnition" SG_ 1578 Ventil_Bat_Diagnose 0;
BA_ "GenSigSendType" SG_ 1578 Ventil_Bat_Diagnose 0;
BA_ "GenSigSwitchedByIgnition" SG_ 1578 Ventil_Bat_Pos 0;
BA_ "GenSigSendType" SG_ 1578 Ventil_Bat_Pos 0;
BA_ "GenSigSwitchedByIgnition" SG_ 1578 Ventil_vor_EM_Diagnose 0;
BA_ "GenSigSendType" SG_ 1578 Ventil_vor_EM_Diagnose 0;
BA_ "GenSigSwitchedByIgnition" SG_ 1578 Ventil_vor_EM_Pos 0;
BA_ "GenSigSendType" SG_ 1578 Ventil_vor_EM_Pos 0;
BA_ "Fehlerwert" SG_ 1578 Temp_vor_PTC 255;
BA_ "GenSigSwitchedByIgnition" SG_ 1578 Temp_vor_PTC 0;
BA_ "GenSigStartValue" SG_ 1578 Temp_vor_PTC 254;
BA_ "GenSigSendType" SG_ 1578 Temp_vor_PTC 0;
BA_ "Fehlerwert" SG_ 1578 Temp_nach_WT 255;
BA_ "GenSigSwitchedByIgnition" SG_ 1578 Temp_nach_WT 0;
BA_ "GenSigStartValue" SG_ 1578 Temp_nach_WT 254;
BA_ "GenSigSendType" SG_ 1578 Temp_nach_WT 0;
BA_ "Fehlerwert" SG_ 1578 Temp_nach_Chiller 255;
BA_ "GenSigSwitchedByIgnition" SG_ 1578 Temp_nach_Chiller 0;
BA_ "GenSigStartValue" SG_ 1578 Temp_nach_Chiller 254;
BA_ "GenSigSendType" SG_ 1578 Temp_nach_Chiller 0;
BA_ "Fehlerwert" SG_ 1578 Temp_nach_LE 255;
BA_ "GenSigSwitchedByIgnition" SG_ 1578 Temp_nach_LE 0;
BA_ "GenSigStartValue" SG_ 1578 Temp_nach_LE 254;
BA_ "GenSigSendType" SG_ 1578 Temp_nach_LE 0;
BA_ "Fehlerwert" SG_ 1578 Temp_nach_EM 255;
BA_ "GenSigSwitchedByIgnition" SG_ 1578 Temp_nach_EM 0;
BA_ "GenSigStartValue" SG_ 1578 Temp_nach_EM 254;
BA_ "GenSigSendType" SG_ 1578 Temp_nach_EM 0;
BA_ "GenSigSwitchedByIgnition" SG_ 1514 EFAS_Weckzeit_Set_Reset 0;
BA_ "GenSigSendType" SG_ 1514 EFAS_Weckzeit_Set_Reset 0;
BA_ "GenSigSwitchedByIgnition" SG_ 1514 EFAS_Jahr 0;
BA_ "GenSigSendType" SG_ 1514 EFAS_Jahr 0;
BA_ "GenSigAutoGenSnd" SG_ 1514 EFAS_Jahr 1;
BA_ "GenSigAutoGenDsp" SG_ 1514 EFAS_Jahr 1;
BA_ "GenSigSwitchedByIgnition" SG_ 1514 EFAS_Monat 0;
BA_ "GenSigSendType" SG_ 1514 EFAS_Monat 0;
BA_ "GenSigAutoGenSnd" SG_ 1514 EFAS_Monat 1;
BA_ "GenSigAutoGenDsp" SG_ 1514 EFAS_Monat 1;
BA_ "GenSigSwitchedByIgnition" SG_ 1514 EFAS_Tag 0;
BA_ "GenSigSendType" SG_ 1514 EFAS_Tag 0;
BA_ "GenSigAutoGenSnd" SG_ 1514 EFAS_Tag 1;
BA_ "GenSigAutoGenDsp" SG_ 1514 EFAS_Tag 1;
BA_ "GenSigSwitchedByIgnition" SG_ 1514 EFAS_Stunde 0;
BA_ "GenSigSendType" SG_ 1514 EFAS_Stunde 0;
BA_ "GenSigAutoGenSnd" SG_ 1514 EFAS_Stunde 1;
BA_ "GenSigAutoGenDsp" SG_ 1514 EFAS_Stunde 1;
BA_ "GenSigSwitchedByIgnition" SG_ 1514 EFAS_Minute 0;
BA_ "GenSigSendType" SG_ 1514 EFAS_Minute 0;
BA_ "GenSigAutoGenSnd" SG_ 1514 EFAS_Minute 1;
BA_ "GenSigAutoGenDsp" SG_ 1514 EFAS_Minute 1;
BA_ "GenSigSendType" SG_ 1526 EK1_Comp_main_stat 0;
BA_ "GenSigAutoGenSnd" SG_ 1526 EK1_Comp_main_stat 1;
BA_ "GenSigAutoGenDsp" SG_ 1526 EK1_Comp_main_stat 1;
BA_ "GenSigSendType" SG_ 1526 EK1_Comp_SCI_com_stat 0;
BA_ "GenSigAutoGenSnd" SG_ 1526 EK1_Comp_SCI_com_stat 1;
BA_ "GenSigAutoGenDsp" SG_ 1526 EK1_Comp_SCI_com_stat 1;
BA_ "GenSigSendType" SG_ 1526 EK1_Comp_ovld_stat 0;
BA_ "GenSigAutoGenSnd" SG_ 1526 EK1_Comp_ovld_stat 1;
BA_ "GenSigAutoGenDsp" SG_ 1526 EK1_Comp_ovld_stat 1;
BA_ "GenSigSendType" SG_ 1526 EK1_Comp_output_stat 0;
BA_ "GenSigAutoGenSnd" SG_ 1526 EK1_Comp_output_stat 1;
BA_ "GenSigAutoGenDsp" SG_ 1526 EK1_Comp_output_stat 1;
BA_ "GenSigSendType" SG_ 1526 EK1_Comp_photo_temp_stat 0;
BA_ "GenSigAutoGenSnd" SG_ 1526 EK1_Comp_photo_temp_stat 1;
BA_ "GenSigAutoGenDsp" SG_ 1526 EK1_Comp_photo_temp_stat 1;
BA_ "GenSigSendType" SG_ 1526 EK1_Comp_Inv_stat 0;
BA_ "GenSigAutoGenSnd" SG_ 1526 EK1_Comp_Inv_stat 1;
BA_ "GenSigAutoGenDsp" SG_ 1526 EK1_Comp_Inv_stat 1;
BA_ "Fehlerwert" SG_ 1526 EK1_KD_Fehler 1;
BA_ "GenSigSendType" SG_ 1526 EK1_KD_Fehler 0;
BA_ "GenSigAutoGenSnd" SG_ 1526 EK1_KD_Fehler 1;
BA_ "GenSigAutoGenDsp" SG_ 1526 EK1_KD_Fehler 1;
BA_ "GenSigSendType" SG_ 1526 EK1_Comp_rev_stat 0;
BA_ "GenSigAutoGenSnd" SG_ 1526 EK1_Comp_rev_stat 1;
BA_ "GenSigAutoGenDsp" SG_ 1526 EK1_Comp_rev_stat 1;
BA_ "GenSigStartValue" SG_ 1526 EK1_Comp_current 255;
BA_ "GenSigSendType" SG_ 1526 EK1_Comp_current 0;
BA_ "GenSigAutoGenSnd" SG_ 1526 EK1_Comp_current 1;
BA_ "GenSigAutoGenDsp" SG_ 1526 EK1_Comp_current 1;
BA_ "GenSigStartValue" SG_ 1526 EK1_Comp_photo_temp 255;
BA_ "GenSigSendType" SG_ 1526 EK1_Comp_photo_temp 0;
BA_ "GenSigAutoGenSnd" SG_ 1526 EK1_Comp_photo_temp 1;
BA_ "GenSigAutoGenDsp" SG_ 1526 EK1_Comp_photo_temp 1;
BA_ "Fehlerwert" SG_ 1406 EY1_KD_Fehler 1;
BA_ "GenSigSendType" SG_ 1406 EY1_KD_Fehler 0;
BA_ "GenSigAutoGenSnd" SG_ 1406 EY1_KD_Fehler 1;
BA_ "GenSigAutoGenDsp" SG_ 1406 EY1_KD_Fehler 1;
BA_ "GenSigSwitchedByIgnition" SG_ 1472 EP1_Zaehler 0;
BA_ "GenSigFuncType" SG_ 1472 EP1_Zaehler 1;
BA_ "GenSigSendType" SG_ 1472 EP1_Zaehler 0;
BA_ "GenSigAutoGenSnd" SG_ 1472 EP1_Zaehler 1;
BA_ "GenSigAutoGenDsp" SG_ 1472 EP1_Zaehler 1;
BA_ "GenSigSendType" SG_ 1472 EP1_Fehler_Sta 0;
BA_ "GenSigAutoGenSnd" SG_ 1472 EP1_Fehler_Sta 1;
BA_ "GenSigAutoGenDsp" SG_ 1472 EP1_Fehler_Sta 1;
BA_ "GenSigSendType" SG_ 1472 EP1_Sta_EPB 0;
BA_ "GenSigAutoGenSnd" SG_ 1472 EP1_Sta_EPB 1;
BA_ "GenSigAutoGenDsp" SG_ 1472 EP1_Sta_EPB 1;
BA_ "GenSigSendType" SG_ 1472 EP1_Sta_Schalter 0;
BA_ "GenSigAutoGenSnd" SG_ 1472 EP1_Sta_Schalter 1;
BA_ "GenSigAutoGenDsp" SG_ 1472 EP1_Sta_Schalter 1;
BA_ "Fehlerwert" SG_ 1472 EP1_Spannkraft 31;
BA_ "GenSigSendType" SG_ 1472 EP1_Spannkraft 0;
BA_ "GenSigAutoGenSnd" SG_ 1472 EP1_Spannkraft 1;
BA_ "GenSigAutoGenDsp" SG_ 1472 EP1_Spannkraft 1;
BA_ "GenSigSendType" SG_ 1472 EP1_Schalterinfo 0;
BA_ "GenSigAutoGenSnd" SG_ 1472 EP1_Schalterinfo 1;
BA_ "GenSigAutoGenDsp" SG_ 1472 EP1_Schalterinfo 1;
BA_ "GenSigSendType" SG_ 1472 EP1_Sta_NWS 0;
BA_ "GenSigAutoGenSnd" SG_ 1472 EP1_Sta_NWS 1;
BA_ "GenSigAutoGenDsp" SG_ 1472 EP1_Sta_NWS 1;
BA_ "GenSigSendType" SG_ 1472 EP1_Neig_winkel 0;
BA_ "GenSigAutoGenSnd" SG_ 1472 EP1_Neig_winkel 1;
BA_ "GenSigAutoGenDsp" SG_ 1472 EP1_Neig_winkel 1;
BA_ "GenSigSendType" SG_ 1472 EP1_Verzoegerung 0;
BA_ "GenSigAutoGenSnd" SG_ 1472 EP1_Verzoegerung 1;
BA_ "GenSigAutoGenDsp" SG_ 1472 EP1_Verzoegerung 1;
BA_ "GenSigSwitchedByIgnition" SG_ 1472 EP1_Fehlereintr 0;
BA_ "GenSigSendType" SG_ 1472 EP1_Fehlereintr 0;
BA_ "GenSigAutoGenSnd" SG_ 1472 EP1_Fehlereintr 1;
BA_ "GenSigAutoGenDsp" SG_ 1472 EP1_Fehlereintr 1;
BA_ "GenSigSendType" SG_ 1472 EP1_Freigabe_Ver 0;
BA_ "GenSigAutoGenSnd" SG_ 1472 EP1_Freigabe_Ver 1;
BA_ "GenSigAutoGenDsp" SG_ 1472 EP1_Freigabe_Ver 1;
BA_ "GenSigSwitchedByIgnition" SG_ 1472 EP1_AutoHold_zul 0;
BA_ "GenSigSendType" SG_ 1472 EP1_AutoHold_zul 0;
BA_ "GenSigAutoGenSnd" SG_ 1472 EP1_AutoHold_zul 1;
BA_ "GenSigAutoGenDsp" SG_ 1472 EP1_AutoHold_zul 1;
BA_ "GenSigSendType" SG_ 1472 EP1_AutoHold_aktiv 0;
BA_ "GenSigAutoGenSnd" SG_ 1472 EP1_AutoHold_aktiv 1;
BA_ "GenSigAutoGenDsp" SG_ 1472 EP1_AutoHold_aktiv 1;
BA_ "GenSigSwitchedByIgnition" SG_ 1472 EP1_SleepInd 0;
BA_ "GenSigSendType" SG_ 1472 EP1_SleepInd 0;
BA_ "GenSigAutoGenSnd" SG_ 1472 EP1_SleepInd 1;
BA_ "GenSigAutoGenDsp" SG_ 1472 EP1_SleepInd 1;
BA_ "GenSigStartValue" SG_ 1472 EP1_Status_Kl_15 1;
BA_ "GenSigSendType" SG_ 1472 EP1_Status_Kl_15 0;
BA_ "GenSigAutoGenSnd" SG_ 1472 EP1_Status_Kl_15 1;
BA_ "GenSigAutoGenDsp" SG_ 1472 EP1_Status_Kl_15 1;
BA_ "GenSigSendType" SG_ 1472 EP1_Lampe_AutoP 0;
BA_ "GenSigAutoGenSnd" SG_ 1472 EP1_Lampe_AutoP 1;
BA_ "GenSigAutoGenDsp" SG_ 1472 EP1_Lampe_AutoP 1;
BA_ "GenSigSendType" SG_ 1472 EP1_Bremslicht 0;
BA_ "GenSigAutoGenSnd" SG_ 1472 EP1_Bremslicht 1;
BA_ "GenSigAutoGenDsp" SG_ 1472 EP1_Bremslicht 1;
BA_ "GenSigSendType" SG_ 1472 EP1_Warnton1 0;
BA_ "GenSigAutoGenSnd" SG_ 1472 EP1_Warnton1 1;
BA_ "GenSigAutoGenDsp" SG_ 1472 EP1_Warnton1 1;
BA_ "GenSigSendType" SG_ 1472 EP1_Warnton2 0;
BA_ "GenSigAutoGenSnd" SG_ 1472 EP1_Warnton2 1;
BA_ "GenSigAutoGenDsp" SG_ 1472 EP1_Warnton2 1;
BA_ "GenSigSendType" SG_ 1472 EP1_AnfShLock 0;
BA_ "GenSigAutoGenSnd" SG_ 1472 EP1_AnfShLock 1;
BA_ "GenSigAutoGenDsp" SG_ 1472 EP1_AnfShLock 1;
BA_ "GenSigSendType" SG_ 1472 EP1_Auto_Schl_Oe 0;
BA_ "GenSigAutoGenSnd" SG_ 1472 EP1_Auto_Schl_Oe 1;
BA_ "GenSigAutoGenDsp" SG_ 1472 EP1_Auto_Schl_Oe 1;
BA_ "GenSigStartValue" SG_ 1472 EP1_QualNeigWi 1;
BA_ "GenSigSendType" SG_ 1472 EP1_QualNeigWi 0;
BA_ "GenSigAutoGenSnd" SG_ 1472 EP1_QualNeigWi 1;
BA_ "GenSigAutoGenDsp" SG_ 1472 EP1_QualNeigWi 1;
BA_ "GenSigSendType" SG_ 1472 EP1_KuppModBer 0;
BA_ "GenSigAutoGenSnd" SG_ 1472 EP1_KuppModBer 1;
BA_ "GenSigAutoGenDsp" SG_ 1472 EP1_KuppModBer 1;
BA_ "GenSigSendType" SG_ 1472 EP1_HydrHalten 0;
BA_ "GenSigAutoGenSnd" SG_ 1472 EP1_HydrHalten 1;
BA_ "GenSigAutoGenDsp" SG_ 1472 EP1_HydrHalten 1;
BA_ "GenSigSendType" SG_ 1472 EP1_Fkt_Lampe 0;
BA_ "GenSigAutoGenSnd" SG_ 1472 EP1_Fkt_Lampe 1;
BA_ "GenSigAutoGenDsp" SG_ 1472 EP1_Fkt_Lampe 1;
BA_ "GenSigSendType" SG_ 1472 EP1_Warnton 0;
BA_ "GenSigAutoGenSnd" SG_ 1472 EP1_Warnton 1;
BA_ "GenSigAutoGenDsp" SG_ 1472 EP1_Warnton 1;
BA_ "GenSigSendType" SG_ 1472 EP1_Fehler_BKL 0;
BA_ "GenSigAutoGenSnd" SG_ 1472 EP1_Fehler_BKL 1;
BA_ "GenSigAutoGenDsp" SG_ 1472 EP1_Fehler_BKL 1;
BA_ "GenSigSendType" SG_ 1472 EP1_Fehler_gelb 0;
BA_ "GenSigAutoGenSnd" SG_ 1472 EP1_Fehler_gelb 1;
BA_ "GenSigAutoGenDsp" SG_ 1472 EP1_Fehler_gelb 1;
BA_ "GenSigSendType" SG_ 1472 EP1__Text 0;
BA_ "GenSigAutoGenSnd" SG_ 1472 EP1__Text 1;
BA_ "GenSigAutoGenDsp" SG_ 1472 EP1__Text 1;
BA_ "GenSigSwitchedByIgnition" SG_ 1472 EP1_Checksum 0;
BA_ "GenSigFuncType" SG_ 1472 EP1_Checksum 4;
BA_ "GenSigSendType" SG_ 1472 EP1_Checksum 0;
BA_ "GenSigAutoGenSnd" SG_ 1472 EP1_Checksum 1;
BA_ "GenSigAutoGenDsp" SG_ 1472 EP1_Checksum 1;
BA_ "Fehlerwert" SG_ 1626 FL1_KD_Fehler 1;
BA_ "GenSigSendType" SG_ 1626 FL1_KD_Fehler 3;
BA_ "GenSigAutoGenSnd" SG_ 1626 FL1_KD_Fehler 1;
BA_ "GenSigAutoGenDsp" SG_ 1626 FL1_KD_Fehler 1;
BA_ "GenSigSendType" SG_ 1626 FL1_FLA_aktiv 3;
BA_ "GenSigAutoGenSnd" SG_ 1626 FL1_FLA_aktiv 1;
BA_ "GenSigAutoGenDsp" SG_ 1626 FL1_FLA_aktiv 1;
BA_ "GenSigSendType" SG_ 1626 FL1_ISP_defekt 3;
BA_ "GenSigAutoGenSnd" SG_ 1626 FL1_ISP_defekt 1;
BA_ "GenSigAutoGenDsp" SG_ 1626 FL1_ISP_defekt 1;
BA_ "GenSigSendType" SG_ 1626 FL1_Sensor_blockiert 3;
BA_ "GenSigAutoGenSnd" SG_ 1626 FL1_Sensor_blockiert 1;
BA_ "GenSigAutoGenDsp" SG_ 1626 FL1_Sensor_blockiert 1;
BA_ "Fehlerwert" SG_ 1626 FL1_Abblendursache 255;
BA_ "GenSigSendType" SG_ 1626 FL1_Abblendursache 3;
BA_ "GenSigAutoGenSnd" SG_ 1626 FL1_Abblendursache 1;
BA_ "GenSigAutoGenDsp" SG_ 1626 FL1_Abblendursache 1;
BA_ "Fehlerwert" SG_ 1626 FL1_Fernlicht_PWM 127;
BA_ "GenSigStartValue" SG_ 1626 FL1_Fernlicht_PWM 100;
BA_ "GenSigSendType" SG_ 1626 FL1_Fernlicht_PWM 3;
BA_ "GenSigAutoGenSnd" SG_ 1626 FL1_Fernlicht_PWM 1;
BA_ "GenSigAutoGenDsp" SG_ 1626 FL1_Fernlicht_PWM 1;
BA_ "Fehlerwert" SG_ 1626 FL1_ISP_Lichtwert_vo 63;
BA_ "GenSigStartValue" SG_ 1626 FL1_ISP_Lichtwert_vo 62;
BA_ "GenSigSendType" SG_ 1626 FL1_ISP_Lichtwert_vo 3;
BA_ "GenSigAutoGenSnd" SG_ 1626 FL1_ISP_Lichtwert_vo 1;
BA_ "GenSigAutoGenDsp" SG_ 1626 FL1_ISP_Lichtwert_vo 1;
BA_ "Fehlerwert" SG_ 1626 FL1_ISP_Lichtwert_hi 63;
BA_ "GenSigStartValue" SG_ 1626 FL1_ISP_Lichtwert_hi 62;
BA_ "GenSigSendType" SG_ 1626 FL1_ISP_Lichtwert_hi 3;
BA_ "GenSigAutoGenSnd" SG_ 1626 FL1_ISP_Lichtwert_hi 1;
BA_ "GenSigAutoGenDsp" SG_ 1626 FL1_ISP_Lichtwert_hi 1;
BA_ "Fehlerwert" SG_ 1626 FL1_ISP_Himmelsrichtung 31;
BA_ "GenSigStartValue" SG_ 1626 FL1_ISP_Himmelsrichtung 30;
BA_ "GenSigSendType" SG_ 1626 FL1_ISP_Himmelsrichtung 3;
BA_ "GenSigAutoGenSnd" SG_ 1626 FL1_ISP_Himmelsrichtung 1;
BA_ "GenSigAutoGenDsp" SG_ 1626 FL1_ISP_Himmelsrichtung 1;
BA_ "GenSigSendType" SG_ 1626 FL1_ISP_Taste 3;
BA_ "GenSigAutoGenSnd" SG_ 1626 FL1_ISP_Taste 1;
BA_ "GenSigAutoGenDsp" SG_ 1626 FL1_ISP_Taste 1;
BA_ "GenSigStartValue" SG_ 1626 FL1_ISP_EC_aktiv 1;
BA_ "GenSigSendType" SG_ 1626 FL1_ISP_EC_aktiv 3;
BA_ "GenSigAutoGenSnd" SG_ 1626 FL1_ISP_EC_aktiv 1;
BA_ "GenSigAutoGenDsp" SG_ 1626 FL1_ISP_EC_aktiv 1;
BA_ "GenSigStartValue" SG_ 1626 FL1_ISP_Kompass_aktiv 1;
BA_ "GenSigSendType" SG_ 1626 FL1_ISP_Kompass_aktiv 3;
BA_ "GenSigAutoGenSnd" SG_ 1626 FL1_ISP_Kompass_aktiv 1;
BA_ "GenSigAutoGenDsp" SG_ 1626 FL1_ISP_Kompass_aktiv 1;
BA_ "Fehlerwert" SG_ 1626 FL1_Dimmwert_ASP 63;
BA_ "GenSigSendType" SG_ 1626 FL1_Dimmwert_ASP 3;
BA_ "GenSigAutoGenSnd" SG_ 1626 FL1_Dimmwert_ASP 1;
BA_ "GenSigAutoGenDsp" SG_ 1626 FL1_Dimmwert_ASP 1;
BA_ "GenSigSendType" SG_ 1626 FL1_FLA_Aufblenden 3;
BA_ "GenSigAutoGenSnd" SG_ 1626 FL1_FLA_Aufblenden 1;
BA_ "GenSigAutoGenDsp" SG_ 1626 FL1_FLA_Aufblenden 1;
BA_ "GenSigSwitchedByIgnition" SG_ 912 GK1_Sta_RDK_Warn 0;
BA_ "GenSigFuncType" SG_ 912 GK1_Sta_RDK_Warn 5;
BA_ "GenSigStartValue" SG_ 912 GK1_Sta_RDK_Warn 1;
BA_ "GenSigSendType" SG_ 912 GK1_Sta_RDK_Warn 0;
BA_ "GenSigAutoGenSnd" SG_ 912 GK1_Sta_RDK_Warn 1;
BA_ "GenSigAutoGenDsp" SG_ 912 GK1_Sta_RDK_Warn 1;
BA_ "GenSigSwitchedByIgnition" SG_ 912 GK1_Sta_Anhaen 0;
BA_ "GenSigFuncType" SG_ 912 GK1_Sta_Anhaen 5;
BA_ "GenSigStartValue" SG_ 912 GK1_Sta_Anhaen 1;
BA_ "GenSigSendType" SG_ 912 GK1_Sta_Anhaen 0;
BA_ "GenSigAutoGenSnd" SG_ 912 GK1_Sta_Anhaen 1;
BA_ "GenSigAutoGenDsp" SG_ 912 GK1_Sta_Anhaen 1;
BA_ "GenSigSwitchedByIgnition" SG_ 912 GK1_Sta_Licht1 0;
BA_ "GenSigFuncType" SG_ 912 GK1_Sta_Licht1 5;
BA_ "GenSigStartValue" SG_ 912 GK1_Sta_Licht1 1;
BA_ "GenSigSendType" SG_ 912 GK1_Sta_Licht1 0;
BA_ "GenSigAutoGenSnd" SG_ 912 GK1_Sta_Licht1 1;
BA_ "GenSigAutoGenDsp" SG_ 912 GK1_Sta_Licht1 1;
BA_ "GenSigSwitchedByIgnition" SG_ 912 GK1_Sta_Licht3 0;
BA_ "GenSigSendType" SG_ 912 GK1_Sta_Licht3 0;
BA_ "GenSigAutoGenSnd" SG_ 912 GK1_Sta_Licht3 1;
BA_ "GenSigAutoGenDsp" SG_ 912 GK1_Sta_Licht3 1;
BA_ "GenSigSwitchedByIgnition" SG_ 912 GK1_Sta_Tuerkont 0;
BA_ "GenSigFuncType" SG_ 912 GK1_Sta_Tuerkont 5;
BA_ "GenSigStartValue" SG_ 912 GK1_Sta_Tuerkont 1;
BA_ "GenSigSendType" SG_ 912 GK1_Sta_Tuerkont 0;
BA_ "GenSigAutoGenSnd" SG_ 912 GK1_Sta_Tuerkont 1;
BA_ "GenSigAutoGenDsp" SG_ 912 GK1_Sta_Tuerkont 1;
BA_ "GenSigSwitchedByIgnition" SG_ 912 GK1_Sta_Li_vorn 0;
BA_ "GenSigSendType" SG_ 912 GK1_Sta_Li_vorn 0;
BA_ "GenSigAutoGenSnd" SG_ 912 GK1_Sta_Li_vorn 1;
BA_ "GenSigAutoGenDsp" SG_ 912 GK1_Sta_Li_vorn 1;
BA_ "GenSigSwitchedByIgnition" SG_ 912 GK1_SleepAckn 0;
BA_ "GenSigSendType" SG_ 912 GK1_SleepAckn 0;
BA_ "GenSigAutoGenSnd" SG_ 912 GK1_SleepAckn 1;
BA_ "GenSigAutoGenDsp" SG_ 912 GK1_SleepAckn 1;
BA_ "GenSigSwitchedByIgnition" SG_ 912 GK1_CharismaModus 0;
BA_ "GenSigAutoGenSnd" SG_ 912 GK1_CharismaModus 1;
BA_ "GenSigAutoGenDsp" SG_ 912 GK1_CharismaModus 1;
BA_ "GenSigSwitchedByIgnition" SG_ 912 GK1_EfficiencyModus 0;
BA_ "GenSigAutoGenSnd" SG_ 912 GK1_EfficiencyModus 1;
BA_ "GenSigAutoGenDsp" SG_ 912 GK1_EfficiencyModus 1;
BA_ "GenSigSwitchedByIgnition" SG_ 912 GK1_SportModus 0;
BA_ "GenSigAutoGenSnd" SG_ 912 GK1_SportModus 1;
BA_ "GenSigAutoGenDsp" SG_ 912 GK1_SportModus 1;
BA_ "GenSigSwitchedByIgnition" SG_ 912 GK1_DriveSelectModus_1 0;
BA_ "GenSigAutoGenSnd" SG_ 912 GK1_DriveSelectModus_1 1;
BA_ "GenSigAutoGenDsp" SG_ 912 GK1_DriveSelectModus_1 1;
BA_ "GenSigSwitchedByIgnition" SG_ 912 GK1_DriveSelectModus_2 0;
BA_ "GenSigAutoGenSnd" SG_ 912 GK1_DriveSelectModus_2 1;
BA_ "GenSigAutoGenDsp" SG_ 912 GK1_DriveSelectModus_2 1;
BA_ "GenSigSwitchedByIgnition" SG_ 912 GK1_SamFktNr 0;
BA_ "GenSigSendType" SG_ 912 GK1_SamFktNr 3;
BA_ "GenSigAutoGenSnd" SG_ 912 GK1_SamFktNr 1;
BA_ "GenSigAutoGenDsp" SG_ 912 GK1_SamFktNr 1;
BA_ "GenSigSwitchedByIgnition" SG_ 912 GK1_Fa_Tuerkont 0;
BA_ "GenSigSendType" SG_ 912 GK1_Fa_Tuerkont 0;
BA_ "GenSigAutoGenSnd" SG_ 912 GK1_Fa_Tuerkont 1;
BA_ "GenSigAutoGenDsp" SG_ 912 GK1_Fa_Tuerkont 1;
BA_ "GenSigSendType" SG_ 912 GK1_RueckfahrSch 0;
BA_ "GenSigAutoGenSnd" SG_ 912 GK1_RueckfahrSch 1;
BA_ "GenSigAutoGenDsp" SG_ 912 GK1_RueckfahrSch 1;
BA_ "GenSigSwitchedByIgnition" SG_ 912 GK1_ELV_verrieg 0;
BA_ "GenSigSendType" SG_ 912 GK1_ELV_verrieg 3;
BA_ "GenSigAutoGenSnd" SG_ 912 GK1_ELV_verrieg 1;
BA_ "GenSigAutoGenDsp" SG_ 912 GK1_ELV_verrieg 1;
BA_ "GenSigSwitchedByIgnition" SG_ 912 GK1_Sta_Kessy_2 0;
BA_ "GenSigFuncType" SG_ 912 GK1_Sta_Kessy_2 5;
BA_ "GenSigStartValue" SG_ 912 GK1_Sta_Kessy_2 1;
BA_ "GenSigSendType" SG_ 912 GK1_Sta_Kessy_2 0;
BA_ "GenSigAutoGenSnd" SG_ 912 GK1_Sta_Kessy_2 1;
BA_ "GenSigAutoGenDsp" SG_ 912 GK1_Sta_Kessy_2 1;
BA_ "GenSigSwitchedByIgnition" SG_ 912 GK1_Sta_Stdhzg 0;
BA_ "GenSigFuncType" SG_ 912 GK1_Sta_Stdhzg 5;
BA_ "GenSigStartValue" SG_ 912 GK1_Sta_Stdhzg 1;
BA_ "GenSigSendType" SG_ 912 GK1_Sta_Stdhzg 0;
BA_ "GenSigAutoGenSnd" SG_ 912 GK1_Sta_Stdhzg 1;
BA_ "GenSigAutoGenDsp" SG_ 912 GK1_Sta_Stdhzg 1;
BA_ "GenSigSwitchedByIgnition" SG_ 912 GK1_SH_Verbau 0;
BA_ "GenSigSendType" SG_ 912 GK1_SH_Verbau 3;
BA_ "GenSigAutoGenSnd" SG_ 912 GK1_SH_Verbau 1;
BA_ "GenSigAutoGenDsp" SG_ 912 GK1_SH_Verbau 1;
BA_ "GenSigSwitchedByIgnition" SG_ 912 GK1_ParkFrontWi 0;
BA_ "GenSigSendType" SG_ 912 GK1_ParkFrontWi 3;
BA_ "GenSigAutoGenSnd" SG_ 912 GK1_ParkFrontWi 1;
BA_ "GenSigAutoGenDsp" SG_ 912 GK1_ParkFrontWi 1;
BA_ "GenSigSwitchedByIgnition" SG_ 912 GK1_KW_Warm 0;
BA_ "GenSigSendType" SG_ 912 GK1_KW_Warm 3;
BA_ "GenSigAutoGenSnd" SG_ 912 GK1_KW_Warm 1;
BA_ "GenSigAutoGenDsp" SG_ 912 GK1_KW_Warm 1;
BA_ "GenSigSwitchedByIgnition" SG_ 912 BCM_Remotestart_Betrieb 0;
BA_ "GenSigSendType" SG_ 912 BCM_Remotestart_Betrieb 3;
BA_ "GenSigSwitchedByIgnition" SG_ 912 BCM_Offroad_Taster 0;
BA_ "GenSigSendType" SG_ 912 BCM_Offroad_Taster 3;
BA_ "GenSigSwitchedByIgnition" SG_ 912 BSK_HL_geoeffnet 0;
BA_ "GenSigSendType" SG_ 912 BSK_HL_geoeffnet 0;
BA_ "GenSigAutoGenSnd" SG_ 912 BSK_HL_geoeffnet 1;
BA_ "GenSigAutoGenDsp" SG_ 912 BSK_HL_geoeffnet 1;
BA_ "GenSigSwitchedByIgnition" SG_ 912 BSK_HR_geoeffnet 0;
BA_ "GenSigSendType" SG_ 912 BSK_HR_geoeffnet 0;
BA_ "GenSigAutoGenSnd" SG_ 912 BSK_HR_geoeffnet 1;
BA_ "GenSigAutoGenDsp" SG_ 912 BSK_HR_geoeffnet 1;
BA_ "GenSigSwitchedByIgnition" SG_ 912 GK1_Rueckfahr 0;
BA_ "GenSigSendType" SG_ 912 GK1_Rueckfahr 3;
BA_ "GenSigAutoGenSnd" SG_ 912 GK1_Rueckfahr 1;
BA_ "GenSigAutoGenDsp" SG_ 912 GK1_Rueckfahr 1;
BA_ "GenSigSwitchedByIgnition" SG_ 912 GK1_BrLi_links 0;
BA_ "GenSigSendType" SG_ 912 GK1_BrLi_links 4;
BA_ "GenSigAutoGenSnd" SG_ 912 GK1_BrLi_links 1;
BA_ "GenSigAutoGenDsp" SG_ 912 GK1_BrLi_links 1;
BA_ "GenSigSwitchedByIgnition" SG_ 912 GK1_BrLi_rechts 0;
BA_ "GenSigSendType" SG_ 912 GK1_BrLi_rechts 4;
BA_ "GenSigAutoGenSnd" SG_ 912 GK1_BrLi_rechts 1;
BA_ "GenSigAutoGenDsp" SG_ 912 GK1_BrLi_rechts 1;
BA_ "GenSigSwitchedByIgnition" SG_ 912 GK1_BrLi_mitte 0;
BA_ "GenSigSendType" SG_ 912 GK1_BrLi_mitte 4;
BA_ "GenSigAutoGenSnd" SG_ 912 GK1_BrLi_mitte 1;
BA_ "GenSigAutoGenDsp" SG_ 912 GK1_BrLi_mitte 1;
BA_ "GenSigSendType" SG_ 912 GK1_BLS_ILM 0;
BA_ "GenSigAutoGenSnd" SG_ 912 GK1_BLS_ILM 1;
BA_ "GenSigAutoGenDsp" SG_ 912 GK1_BLS_ILM 1;
BA_ "GenSigSendType" SG_ 912 GK1_EDC_ILM 0;
BA_ "GenSigAutoGenSnd" SG_ 912 GK1_EDC_ILM 1;
BA_ "GenSigAutoGenDsp" SG_ 912 GK1_EDC_ILM 1;
BA_ "GenSigSwitchedByIgnition" SG_ 912 GK1_Blinker_li 0;
BA_ "GenSigSendType" SG_ 912 GK1_Blinker_li 3;
BA_ "GenSigAutoGenSnd" SG_ 912 GK1_Blinker_li 1;
BA_ "GenSigAutoGenDsp" SG_ 912 GK1_Blinker_li 1;
BA_ "GenSigSwitchedByIgnition" SG_ 912 GK1_Blinker_re 0;
BA_ "GenSigSendType" SG_ 912 GK1_Blinker_re 3;
BA_ "GenSigAutoGenSnd" SG_ 912 GK1_Blinker_re 1;
BA_ "GenSigAutoGenDsp" SG_ 912 GK1_Blinker_re 1;
BA_ "GenSigSwitchedByIgnition" SG_ 912 GK1_def_P_verr 0;
BA_ "GenSigSendType" SG_ 912 GK1_def_P_verr 3;
BA_ "GenSigAutoGenSnd" SG_ 912 GK1_def_P_verr 1;
BA_ "GenSigAutoGenDsp" SG_ 912 GK1_def_P_verr 1;
BA_ "GenSigSwitchedByIgnition" SG_ 912 GK1_LS1_Fernlicht 0;
BA_ "GenSigSendType" SG_ 912 GK1_LS1_Fernlicht 3;
BA_ "GenSigAutoGenSnd" SG_ 912 GK1_LS1_Fernlicht 1;
BA_ "GenSigAutoGenDsp" SG_ 912 GK1_LS1_Fernlicht 1;
BA_ "GenSigSwitchedByIgnition" SG_ 912 GK1_Sta_Licht2 0;
BA_ "GenSigFuncType" SG_ 912 GK1_Sta_Licht2 5;
BA_ "GenSigStartValue" SG_ 912 GK1_Sta_Licht2 1;
BA_ "GenSigSendType" SG_ 912 GK1_Sta_Licht2 0;
BA_ "GenSigAutoGenSnd" SG_ 912 GK1_Sta_Licht2 1;
BA_ "GenSigAutoGenDsp" SG_ 912 GK1_Sta_Licht2 1;
BA_ "GenSigSwitchedByIgnition" SG_ 912 GK1_Sta_LSM 0;
BA_ "GenSigFuncType" SG_ 912 GK1_Sta_LSM 5;
BA_ "GenSigStartValue" SG_ 912 GK1_Sta_LSM 1;
BA_ "GenSigSendType" SG_ 912 GK1_Sta_LSM 0;
BA_ "GenSigAutoGenSnd" SG_ 912 GK1_Sta_LSM 1;
BA_ "GenSigAutoGenDsp" SG_ 912 GK1_Sta_LSM 1;
BA_ "GenSigSwitchedByIgnition" SG_ 912 WI1_Front_Wasch 0;
BA_ "GenSigSendType" SG_ 912 WI1_Front_Wasch 3;
BA_ "GenSigAutoGenSnd" SG_ 912 WI1_Front_Wasch 1;
BA_ "GenSigAutoGenDsp" SG_ 912 WI1_Front_Wasch 1;
BA_ "GenSigSwitchedByIgnition" SG_ 912 BSK_BT_geoeffnet 0;
BA_ "GenSigSendType" SG_ 912 BSK_BT_geoeffnet 0;
BA_ "GenSigAutoGenSnd" SG_ 912 BSK_BT_geoeffnet 1;
BA_ "GenSigAutoGenDsp" SG_ 912 BSK_BT_geoeffnet 1;
BA_ "GenSigSwitchedByIgnition" SG_ 912 BCM_CV_Taster 0;
BA_ "GenSigSendType" SG_ 912 BCM_CV_Taster 3;
BA_ "GenSigSwitchedByIgnition" SG_ 912 BSK_HD_Hauptraste 0;
BA_ "GenSigSendType" SG_ 912 BSK_HD_Hauptraste 0;
BA_ "GenSigAutoGenSnd" SG_ 912 BSK_HD_Hauptraste 1;
BA_ "GenSigAutoGenDsp" SG_ 912 BSK_HD_Hauptraste 1;
BA_ "GenSigSwitchedByIgnition" SG_ 912 GK1_Anhaenger 0;
BA_ "GenSigSendType" SG_ 912 GK1_Anhaenger 3;
BA_ "GenSigAutoGenSnd" SG_ 912 GK1_Anhaenger 1;
BA_ "GenSigAutoGenDsp" SG_ 912 GK1_Anhaenger 1;
BA_ "GenSigSwitchedByIgnition" SG_ 912 GK1_BrLi_Anhaen 0;
BA_ "GenSigSendType" SG_ 912 GK1_BrLi_Anhaen 3;
BA_ "GenSigAutoGenSnd" SG_ 912 GK1_BrLi_Anhaen 1;
BA_ "GenSigAutoGenDsp" SG_ 912 GK1_BrLi_Anhaen 1;
BA_ "GenSigSwitchedByIgnition" SG_ 912 GK1_Abblendlicht 0;
BA_ "GenSigSendType" SG_ 912 GK1_Abblendlicht 3;
BA_ "GenSigAutoGenSnd" SG_ 912 GK1_Abblendlicht 1;
BA_ "GenSigAutoGenDsp" SG_ 912 GK1_Abblendlicht 1;
BA_ "GenSigSwitchedByIgnition" SG_ 912 GK1_Fernlicht 0;
BA_ "GenSigSendType" SG_ 912 GK1_Fernlicht 3;
BA_ "GenSigAutoGenSnd" SG_ 912 GK1_Fernlicht 1;
BA_ "GenSigAutoGenDsp" SG_ 912 GK1_Fernlicht 1;
BA_ "GenSigSwitchedByIgnition" SG_ 912 GK1_Wischer_vorn 0;
BA_ "GenSigSendType" SG_ 912 GK1_Wischer_vorn 3;
BA_ "GenSigAutoGenSnd" SG_ 912 GK1_Wischer_vorn 1;
BA_ "GenSigAutoGenDsp" SG_ 912 GK1_Wischer_vorn 1;
BA_ "GenSigSwitchedByIgnition" SG_ 912 GK1_Sta_ILM_F_1 0;
BA_ "GenSigFuncType" SG_ 912 GK1_Sta_ILM_F_1 5;
BA_ "GenSigStartValue" SG_ 912 GK1_Sta_ILM_F_1 1;
BA_ "GenSigSendType" SG_ 912 GK1_Sta_ILM_F_1 0;
BA_ "GenSigAutoGenSnd" SG_ 912 GK1_Sta_ILM_F_1 1;
BA_ "GenSigAutoGenDsp" SG_ 912 GK1_Sta_ILM_F_1 1;
BA_ "GenSigSwitchedByIgnition" SG_ 912 GK1_Abbl_VL_def 0;
BA_ "GenSigSendType" SG_ 912 GK1_Abbl_VL_def 4;
BA_ "GenSigAutoGenSnd" SG_ 912 GK1_Abbl_VL_def 1;
BA_ "GenSigAutoGenDsp" SG_ 912 GK1_Abbl_VL_def 1;
BA_ "GenSigSwitchedByIgnition" SG_ 912 GK1_Abbl_VR_def 0;
BA_ "GenSigSendType" SG_ 912 GK1_Abbl_VR_def 4;
BA_ "GenSigAutoGenSnd" SG_ 912 GK1_Abbl_VR_def 1;
BA_ "GenSigAutoGenDsp" SG_ 912 GK1_Abbl_VR_def 1;
BA_ "GenSigSendType" SG_ 912 GK1_Blink_Autob 0;
BA_ "GenSigAutoGenSnd" SG_ 912 GK1_Blink_Autob 1;
BA_ "GenSigAutoGenDsp" SG_ 912 GK1_Blink_Autob 1;
BA_ "GenSigSwitchedByIgnition" SG_ 912 GK1_Warnblk_Status 0;
BA_ "GenSigSendType" SG_ 912 GK1_Warnblk_Status 3;
BA_ "GenSigAutoGenSnd" SG_ 912 GK1_Warnblk_Status 1;
BA_ "GenSigAutoGenDsp" SG_ 912 GK1_Warnblk_Status 1;
BA_ "GenSigSendType" SG_ 912 GK1_SH_laeuft 0;
BA_ "GenSigAutoGenSnd" SG_ 912 GK1_SH_laeuft 1;
BA_ "GenSigAutoGenDsp" SG_ 912 GK1_SH_laeuft 1;
BA_ "GenSigSwitchedByIgnition" SG_ 912 SH1_ein_Wasserpumpe 0;
BA_ "GenSigSendType" SG_ 912 SH1_ein_Wasserpumpe 3;
BA_ "GenSigAutoGenSnd" SG_ 912 SH1_ein_Wasserpumpe 1;
BA_ "GenSigAutoGenDsp" SG_ 912 SH1_ein_Wasserpumpe 1;
BA_ "GenSigSwitchedByIgnition" SG_ 912 GK1_Nebel_ein 0;
BA_ "GenSigSendType" SG_ 912 GK1_Nebel_ein 3;
BA_ "GenSigAutoGenSnd" SG_ 912 GK1_Nebel_ein 1;
BA_ "GenSigAutoGenDsp" SG_ 912 GK1_Nebel_ein 1;
BA_ "GenSigSwitchedByIgnition" SG_ 912 GK1_Bremslicht 0;
BA_ "GenSigSendType" SG_ 912 GK1_Bremslicht 3;
BA_ "GenSigAutoGenSnd" SG_ 912 GK1_Bremslicht 1;
BA_ "GenSigAutoGenDsp" SG_ 912 GK1_Bremslicht 1;
BA_ "GenSigSendType" SG_ 912 GK1_Anh_abgesteckt 0;
BA_ "GenSigAutoGenSnd" SG_ 912 GK1_Anh_abgesteckt 1;
BA_ "GenSigAutoGenDsp" SG_ 912 GK1_Anh_abgesteckt 1;
BA_ "GenSigSendType" SG_ 912 GK1_AnhKonLamp 0;
BA_ "GenSigAutoGenSnd" SG_ 912 GK1_AnhKonLamp 1;
BA_ "GenSigAutoGenDsp" SG_ 912 GK1_AnhKonLamp 1;
BA_ "GenSigSwitchedByIgnition" SG_ 912 LDS_Stellung_AFL 0;
BA_ "GenSigSendType" SG_ 912 LDS_Stellung_AFL 0;
BA_ "GenSigAutoGenSnd" SG_ 912 LDS_Stellung_AFL 1;
BA_ "GenSigAutoGenDsp" SG_ 912 LDS_Stellung_AFL 1;
BA_ "GenSigSwitchedByIgnition" SG_ 912 GK1_SH_Zusatzfkt 0;
BA_ "GenSigSendType" SG_ 912 GK1_SH_Zusatzfkt 0;
BA_ "GenSigAutoGenSnd" SG_ 912 GK1_SH_Zusatzfkt 1;
BA_ "GenSigAutoGenDsp" SG_ 912 GK1_SH_Zusatzfkt 1;
BA_ "GenSigSwitchedByIgnition" SG_ 914 GK2_Sta_LSM 0;
BA_ "GenSigFuncType" SG_ 914 GK2_Sta_LSM 5;
BA_ "GenSigStartValue" SG_ 914 GK2_Sta_LSM 1;
BA_ "GenSigSendType" SG_ 914 GK2_Sta_LSM 0;
BA_ "GenSigAutoGenSnd" SG_ 914 GK2_Sta_LSM 1;
BA_ "GenSigAutoGenDsp" SG_ 914 GK2_Sta_LSM 1;
BA_ "GenSigSwitchedByIgnition" SG_ 914 GK2_Sta_Lichtsensor 0;
BA_ "GenSigFuncType" SG_ 914 GK2_Sta_Lichtsensor 5;
BA_ "GenSigStartValue" SG_ 914 GK2_Sta_Lichtsensor 1;
BA_ "GenSigSendType" SG_ 914 GK2_Sta_Lichtsensor 0;
BA_ "GenSigAutoGenSnd" SG_ 914 GK2_Sta_Lichtsensor 1;
BA_ "GenSigAutoGenDsp" SG_ 914 GK2_Sta_Lichtsensor 1;
BA_ "GenSigSwitchedByIgnition" SG_ 914 GK2_Sta_Licht1 0;
BA_ "GenSigFuncType" SG_ 914 GK2_Sta_Licht1 5;
BA_ "GenSigStartValue" SG_ 914 GK2_Sta_Licht1 1;
BA_ "GenSigSendType" SG_ 914 GK2_Sta_Licht1 0;
BA_ "GenSigAutoGenSnd" SG_ 914 GK2_Sta_Licht1 1;
BA_ "GenSigAutoGenDsp" SG_ 914 GK2_Sta_Licht1 1;
BA_ "GenSigSwitchedByIgnition" SG_ 914 GK2_Sta_VSG 0;
BA_ "GenSigFuncType" SG_ 914 GK2_Sta_VSG 5;
BA_ "GenSigStartValue" SG_ 914 GK2_Sta_VSG 1;
BA_ "GenSigSendType" SG_ 914 GK2_Sta_VSG 0;
BA_ "GenSigAutoGenSnd" SG_ 914 GK2_Sta_VSG 1;
BA_ "GenSigAutoGenDsp" SG_ 914 GK2_Sta_VSG 1;
BA_ "GenSigSwitchedByIgnition" SG_ 914 GK2_Sta_Schluessel 0;
BA_ "GenSigFuncType" SG_ 914 GK2_Sta_Schluessel 5;
BA_ "GenSigStartValue" SG_ 914 GK2_Sta_Schluessel 1;
BA_ "GenSigSendType" SG_ 914 GK2_Sta_Schluessel 0;
BA_ "GenSigAutoGenSnd" SG_ 914 GK2_Sta_Schluessel 1;
BA_ "GenSigAutoGenDsp" SG_ 914 GK2_Sta_Schluessel 1;
BA_ "GenSigSwitchedByIgnition" SG_ 914 GK2_Sta_Profil 0;
BA_ "GenSigFuncType" SG_ 914 GK2_Sta_Profil 5;
BA_ "GenSigStartValue" SG_ 914 GK2_Sta_Profil 1;
BA_ "GenSigSendType" SG_ 914 GK2_Sta_Profil 0;
BA_ "GenSigAutoGenSnd" SG_ 914 GK2_Sta_Profil 1;
BA_ "GenSigAutoGenDsp" SG_ 914 GK2_Sta_Profil 1;
BA_ "GenSigSwitchedByIgnition" SG_ 914 GK2_Sta_Clima2 0;
BA_ "GenSigFuncType" SG_ 914 GK2_Sta_Clima2 5;
BA_ "GenSigStartValue" SG_ 914 GK2_Sta_Clima2 1;
BA_ "GenSigSendType" SG_ 914 GK2_Sta_Clima2 0;
BA_ "GenSigAutoGenSnd" SG_ 914 GK2_Sta_Clima2 1;
BA_ "GenSigAutoGenDsp" SG_ 914 GK2_Sta_Clima2 1;
BA_ "GenSigSwitchedByIgnition" SG_ 914 GK2_Sta_BSG4 0;
BA_ "GenSigFuncType" SG_ 914 GK2_Sta_BSG4 5;
BA_ "GenSigStartValue" SG_ 914 GK2_Sta_BSG4 1;
BA_ "GenSigSendType" SG_ 914 GK2_Sta_BSG4 0;
BA_ "GenSigAutoGenSnd" SG_ 914 GK2_Sta_BSG4 1;
BA_ "GenSigAutoGenDsp" SG_ 914 GK2_Sta_BSG4 1;
BA_ "GenSigSwitchedByIgnition" SG_ 914 GK2_Sta_Kessy_4 0;
BA_ "GenSigFuncType" SG_ 914 GK2_Sta_Kessy_4 5;
BA_ "GenSigStartValue" SG_ 914 GK2_Sta_Kessy_4 1;
BA_ "GenSigSendType" SG_ 914 GK2_Sta_Kessy_4 0;
BA_ "GenSigAutoGenSnd" SG_ 914 GK2_Sta_Kessy_4 1;
BA_ "GenSigAutoGenDsp" SG_ 914 GK2_Sta_Kessy_4 1;
BA_ "GenSigSwitchedByIgnition" SG_ 914 BS4_Gleitende_Leuchtw_Anf 0;
BA_ "GenSigSendType" SG_ 914 BS4_Gleitende_Leuchtw_Anf 3;
BA_ "GenSigAutoGenSnd" SG_ 914 BS4_Gleitende_Leuchtw_Anf 1;
BA_ "GenSigAutoGenDsp" SG_ 914 BS4_Gleitende_Leuchtw_Anf 1;
BA_ "GenSigSwitchedByIgnition" SG_ 914 BS4_GLW_Fernlicht_Anf 0;
BA_ "GenSigSendType" SG_ 914 BS4_GLW_Fernlicht_Anf 3;
BA_ "GenSigAutoGenSnd" SG_ 914 BS4_GLW_Fernlicht_Anf 1;
BA_ "GenSigAutoGenDsp" SG_ 914 BS4_GLW_Fernlicht_Anf 1;
BA_ "GenSigSwitchedByIgnition" SG_ 914 GK2_Blk_L_Kontrolle 0;
BA_ "GenSigSendType" SG_ 914 GK2_Blk_L_Kontrolle 3;
BA_ "GenSigAutoGenSnd" SG_ 914 GK2_Blk_L_Kontrolle 1;
BA_ "GenSigAutoGenDsp" SG_ 914 GK2_Blk_L_Kontrolle 1;
BA_ "GenSigSwitchedByIgnition" SG_ 914 GK2_Blk_R_Kontrolle 0;
BA_ "GenSigSendType" SG_ 914 GK2_Blk_R_Kontrolle 3;
BA_ "GenSigAutoGenSnd" SG_ 914 GK2_Blk_R_Kontrolle 1;
BA_ "GenSigAutoGenDsp" SG_ 914 GK2_Blk_R_Kontrolle 1;
BA_ "GenSigSwitchedByIgnition" SG_ 914 GK2_LS_KomFehler 0;
BA_ "GenSigSendType" SG_ 914 GK2_LS_KomFehler 0;
BA_ "GenSigAutoGenSnd" SG_ 914 GK2_LS_KomFehler 1;
BA_ "GenSigAutoGenDsp" SG_ 914 GK2_LS_KomFehler 1;
BA_ "GenSigSendType" SG_ 914 GK2_LS_def 0;
BA_ "GenSigAutoGenSnd" SG_ 914 GK2_LS_def 1;
BA_ "GenSigAutoGenDsp" SG_ 914 GK2_LS_def 1;
BA_ "GenSigSwitchedByIgnition" SG_ 914 GK2_Helligkeit 0;
BA_ "GenSigSendType" SG_ 914 GK2_Helligkeit 0;
BA_ "GenSigAutoGenSnd" SG_ 914 GK2_Helligkeit 1;
BA_ "GenSigAutoGenDsp" SG_ 914 GK2_Helligkeit 1;
BA_ "GenSigSwitchedByIgnition" SG_ 914 GK2_VD_zu_ver 0;
BA_ "GenSigSendType" SG_ 914 GK2_VD_zu_ver 3;
BA_ "GenSigAutoGenSnd" SG_ 914 GK2_VD_zu_ver 1;
BA_ "GenSigAutoGenDsp" SG_ 914 GK2_VD_zu_ver 1;
BA_ "GenSigSwitchedByIgnition" SG_ 914 GK2_VD_entriegelt 0;
BA_ "GenSigSendType" SG_ 914 GK2_VD_entriegelt 3;
BA_ "GenSigAutoGenSnd" SG_ 914 GK2_VD_entriegelt 1;
BA_ "GenSigAutoGenDsp" SG_ 914 GK2_VD_entriegelt 1;
BA_ "GenSigSwitchedByIgnition" SG_ 914 GK2_VD_offen_ver 0;
BA_ "GenSigSendType" SG_ 914 GK2_VD_offen_ver 3;
BA_ "GenSigAutoGenSnd" SG_ 914 GK2_VD_offen_ver 1;
BA_ "GenSigAutoGenDsp" SG_ 914 GK2_VD_offen_ver 1;
BA_ "GenSigSwitchedByIgnition" SG_ 914 GK2_Verdeck_Anf 0;
BA_ "GenSigSendType" SG_ 914 GK2_Verdeck_Anf 3;
BA_ "GenSigAutoGenSnd" SG_ 914 GK2_Verdeck_Anf 1;
BA_ "GenSigAutoGenDsp" SG_ 914 GK2_Verdeck_Anf 1;
BA_ "GenSigSwitchedByIgnition" SG_ 914 GK2_VDKD_auf 0;
BA_ "GenSigSendType" SG_ 914 GK2_VDKD_auf 3;
BA_ "GenSigAutoGenSnd" SG_ 914 GK2_VDKD_auf 1;
BA_ "GenSigAutoGenDsp" SG_ 914 GK2_VDKD_auf 1;
BA_ "GenSigSwitchedByIgnition" SG_ 914 GK2_Schluessel 0;
BA_ "GenSigSendType" SG_ 914 GK2_Schluessel 0;
BA_ "GenSigAutoGenSnd" SG_ 914 GK2_Schluessel 1;
BA_ "GenSigAutoGenDsp" SG_ 914 GK2_Schluessel 1;
BA_ "GenSigSwitchedByIgnition" SG_ 914 GK2_Hardtop 0;
BA_ "GenSigSendType" SG_ 914 GK2_Hardtop 3;
BA_ "GenSigAutoGenSnd" SG_ 914 GK2_Hardtop 1;
BA_ "GenSigAutoGenDsp" SG_ 914 GK2_Hardtop 1;
BA_ "GenSigSwitchedByIgnition" SG_ 914 GK2_AFL_Schalter 0;
BA_ "GenSigSendType" SG_ 914 GK2_AFL_Schalter 3;
BA_ "GenSigAutoGenSnd" SG_ 914 GK2_AFL_Schalter 1;
BA_ "GenSigAutoGenDsp" SG_ 914 GK2_AFL_Schalter 1;
BA_ "GenSigSwitchedByIgnition" SG_ 914 GK2_Nebelschluss 0;
BA_ "GenSigSendType" SG_ 914 GK2_Nebelschluss 3;
BA_ "GenSigAutoGenSnd" SG_ 914 GK2_Nebelschluss 1;
BA_ "GenSigAutoGenDsp" SG_ 914 GK2_Nebelschluss 1;
BA_ "GenSigSwitchedByIgnition" SG_ 914 GK2_EM_LIN_ungueltig 0;
BA_ "GenSigStartValue" SG_ 914 GK2_EM_LIN_ungueltig 1;
BA_ "GenSigSendType" SG_ 914 GK2_EM_LIN_ungueltig 0;
BA_ "GenSigAutoGenSnd" SG_ 914 GK2_EM_LIN_ungueltig 1;
BA_ "GenSigAutoGenDsp" SG_ 914 GK2_EM_LIN_ungueltig 1;
BA_ "GenSigSwitchedByIgnition" SG_ 914 GK2_Profil 0;
BA_ "GenSigSendType" SG_ 914 GK2_Profil 3;
BA_ "GenSigAutoGenSnd" SG_ 914 GK2_Profil 1;
BA_ "GenSigAutoGenDsp" SG_ 914 GK2_Profil 1;
BA_ "GenSigSwitchedByIgnition" SG_ 914 GK2_Kl_StSt_Info 0;
BA_ "GenSigSendType" SG_ 914 GK2_Kl_StSt_Info 3;
BA_ "GenSigAutoGenSnd" SG_ 914 GK2_Kl_StSt_Info 1;
BA_ "GenSigAutoGenDsp" SG_ 914 GK2_Kl_StSt_Info 1;
BA_ "GenSigSwitchedByIgnition" SG_ 914 GK2_BSG_StSt_Info 0;
BA_ "GenSigSendType" SG_ 914 GK2_BSG_StSt_Info 3;
BA_ "GenSigAutoGenSnd" SG_ 914 GK2_BSG_StSt_Info 1;
BA_ "GenSigAutoGenDsp" SG_ 914 GK2_BSG_StSt_Info 1;
BA_ "Fehlerwert" SG_ 914 GK2_BEM_P_Generator 255;
BA_ "GenSigSwitchedByIgnition" SG_ 914 GK2_BEM_P_Generator 0;
BA_ "GenSigSendType" SG_ 914 GK2_BEM_P_Generator 0;
BA_ "GenSigAutoGenSnd" SG_ 914 GK2_BEM_P_Generator 1;
BA_ "GenSigAutoGenDsp" SG_ 914 GK2_BEM_P_Generator 1;
BA_ "GenSigSwitchedByIgnition" SG_ 914 GK2_BEM_Abschaltstufen 0;
BA_ "GenSigSendType" SG_ 914 GK2_BEM_Abschaltstufen 0;
BA_ "GenSigAutoGenSnd" SG_ 914 GK2_BEM_Abschaltstufen 1;
BA_ "GenSigAutoGenDsp" SG_ 914 GK2_BEM_Abschaltstufen 1;
BA_ "GenSigSwitchedByIgnition" SG_ 914 GK2_BEM_DFM 0;
BA_ "GenSigSendType" SG_ 914 GK2_BEM_DFM 0;
BA_ "GenSigAutoGenSnd" SG_ 914 GK2_BEM_DFM 1;
BA_ "GenSigAutoGenDsp" SG_ 914 GK2_BEM_DFM 1;
BA_ "GenSigSwitchedByIgnition" SG_ 914 GK2_Kessy_StSt_Info 0;
BA_ "GenSigSendType" SG_ 914 GK2_Kessy_StSt_Info 0;
BA_ "GenSigAutoGenSnd" SG_ 914 GK2_Kessy_StSt_Info 1;
BA_ "GenSigAutoGenDsp" SG_ 914 GK2_Kessy_StSt_Info 1;
BA_ "GenSigSwitchedByIgnition" SG_ 914 GK2_BEM_StSt_Info 0;
BA_ "GenSigSendType" SG_ 914 GK2_BEM_StSt_Info 0;
BA_ "GenSigAutoGenSnd" SG_ 914 GK2_BEM_StSt_Info 1;
BA_ "GenSigAutoGenDsp" SG_ 914 GK2_BEM_StSt_Info 1;
BA_ "GenSigSwitchedByIgnition" SG_ 914 BEM_Segel_Info 0;
BA_ "GenSigSendType" SG_ 914 BEM_Segel_Info 0;
BA_ "GenSigSwitchedByIgnition" SG_ 914 LS1_FAS_Taster 0;
BA_ "GenSigSendType" SG_ 914 LS1_FAS_Taster 3;
BA_ "GenSigAutoGenSnd" SG_ 914 LS1_FAS_Taster 1;
BA_ "GenSigAutoGenDsp" SG_ 914 LS1_FAS_Taster 1;
BA_ "Fehlerwert" SG_ 914 LS1_Fehler_FAS_Taster 1;
BA_ "GenSigSwitchedByIgnition" SG_ 914 LS1_Fehler_FAS_Taster 0;
BA_ "GenSigSendType" SG_ 914 LS1_Fehler_FAS_Taster 3;
BA_ "GenSigAutoGenSnd" SG_ 914 LS1_Fehler_FAS_Taster 1;
BA_ "GenSigAutoGenDsp" SG_ 914 LS1_Fehler_FAS_Taster 1;
BA_ "GenSigSwitchedByIgnition" SG_ 915 GK3_Sta_Kessy_4 0;
BA_ "GenSigFuncType" SG_ 915 GK3_Sta_Kessy_4 5;
BA_ "GenSigStartValue" SG_ 915 GK3_Sta_Kessy_4 1;
BA_ "GenSigSendType" SG_ 915 GK3_Sta_Kessy_4 0;
BA_ "GenSigAutoGenSnd" SG_ 915 GK3_Sta_Kessy_4 1;
BA_ "GenSigAutoGenDsp" SG_ 915 GK3_Sta_Kessy_4 1;
BA_ "GenSigSwitchedByIgnition" SG_ 915 GK3_Sta_BCM_KY1 0;
BA_ "GenSigFuncType" SG_ 915 GK3_Sta_BCM_KY1 5;
BA_ "GenSigStartValue" SG_ 915 GK3_Sta_BCM_KY1 1;
BA_ "GenSigSendType" SG_ 915 GK3_Sta_BCM_KY1 0;
BA_ "GenSigAutoGenSnd" SG_ 915 GK3_Sta_BCM_KY1 1;
BA_ "GenSigAutoGenDsp" SG_ 915 GK3_Sta_BCM_KY1 1;
BA_ "GenSigSwitchedByIgnition" SG_ 915 GK3_Sta_Clima_3 0;
BA_ "GenSigFuncType" SG_ 915 GK3_Sta_Clima_3 5;
BA_ "GenSigStartValue" SG_ 915 GK3_Sta_Clima_3 1;
BA_ "GenSigSendType" SG_ 915 GK3_Sta_Clima_3 0;
BA_ "GenSigAutoGenSnd" SG_ 915 GK3_Sta_Clima_3 1;
BA_ "GenSigAutoGenDsp" SG_ 915 GK3_Sta_Clima_3 1;
BA_ "GenSigSwitchedByIgnition" SG_ 915 GK3_Sta_TSG_FT_3 0;
BA_ "GenSigFuncType" SG_ 915 GK3_Sta_TSG_FT_3 5;
BA_ "GenSigStartValue" SG_ 915 GK3_Sta_TSG_FT_3 1;
BA_ "GenSigSendType" SG_ 915 GK3_Sta_TSG_FT_3 0;
BA_ "GenSigAutoGenSnd" SG_ 915 GK3_Sta_TSG_FT_3 1;
BA_ "GenSigAutoGenDsp" SG_ 915 GK3_Sta_TSG_FT_3 1;
BA_ "GenSigSwitchedByIgnition" SG_ 915 GK3_Sta_HD_1 0;
BA_ "GenSigFuncType" SG_ 915 GK3_Sta_HD_1 5;
BA_ "GenSigStartValue" SG_ 915 GK3_Sta_HD_1 1;
BA_ "GenSigSendType" SG_ 915 GK3_Sta_HD_1 0;
BA_ "GenSigAutoGenSnd" SG_ 915 GK3_Sta_HD_1 1;
BA_ "GenSigAutoGenDsp" SG_ 915 GK3_Sta_HD_1 1;
BA_ "GenSigSwitchedByIgnition" SG_ 915 GK3_Sta_Memory_1 0;
BA_ "GenSigFuncType" SG_ 915 GK3_Sta_Memory_1 5;
BA_ "GenSigStartValue" SG_ 915 GK3_Sta_Memory_1 1;
BA_ "GenSigSendType" SG_ 915 GK3_Sta_Memory_1 0;
BA_ "GenSigAutoGenSnd" SG_ 915 GK3_Sta_Memory_1 1;
BA_ "GenSigAutoGenDsp" SG_ 915 GK3_Sta_Memory_1 1;
BA_ "GenSigSwitchedByIgnition" SG_ 915 GK3_Sta_res_06 0;
BA_ "GenSigFuncType" SG_ 915 GK3_Sta_res_06 5;
BA_ "GenSigStartValue" SG_ 915 GK3_Sta_res_06 1;
BA_ "GenSigSendType" SG_ 915 GK3_Sta_res_06 0;
BA_ "GenSigAutoGenSnd" SG_ 915 GK3_Sta_res_06 1;
BA_ "GenSigAutoGenDsp" SG_ 915 GK3_Sta_res_06 1;
BA_ "GenSigSwitchedByIgnition" SG_ 915 GK3_Sta_res_07 0;
BA_ "GenSigFuncType" SG_ 915 GK3_Sta_res_07 5;
BA_ "GenSigStartValue" SG_ 915 GK3_Sta_res_07 1;
BA_ "GenSigSendType" SG_ 915 GK3_Sta_res_07 0;
BA_ "GenSigAutoGenSnd" SG_ 915 GK3_Sta_res_07 1;
BA_ "GenSigAutoGenDsp" SG_ 915 GK3_Sta_res_07 1;
BA_ "GenSigSwitchedByIgnition" SG_ 915 GK3_KY4_Meldungen 0;
BA_ "GenSigSendType" SG_ 915 GK3_KY4_Meldungen 3;
BA_ "GenSigAutoGenSnd" SG_ 915 GK3_KY4_Meldungen 1;
BA_ "GenSigAutoGenDsp" SG_ 915 GK3_KY4_Meldungen 1;
BA_ "GenSigSwitchedByIgnition" SG_ 915 GK3_KY4_Gong_600 0;
BA_ "GenSigSendType" SG_ 915 GK3_KY4_Gong_600 3;
BA_ "GenSigAutoGenSnd" SG_ 915 GK3_KY4_Gong_600 1;
BA_ "GenSigAutoGenDsp" SG_ 915 GK3_KY4_Gong_600 1;
BA_ "GenSigSwitchedByIgnition" SG_ 915 GK3_KY4_PassAL_Menue 0;
BA_ "GenSigSendType" SG_ 915 GK3_KY4_PassAL_Menue 3;
BA_ "GenSigAutoGenSnd" SG_ 915 GK3_KY4_PassAL_Menue 1;
BA_ "GenSigAutoGenDsp" SG_ 915 GK3_KY4_PassAL_Menue 1;
BA_ "GenSigSwitchedByIgnition" SG_ 915 GK3_KY4_PassAL_akt 0;
BA_ "GenSigSendType" SG_ 915 GK3_KY4_PassAL_akt 3;
BA_ "GenSigAutoGenSnd" SG_ 915 GK3_KY4_PassAL_akt 1;
BA_ "GenSigAutoGenDsp" SG_ 915 GK3_KY4_PassAL_akt 1;
BA_ "GenSigSwitchedByIgnition" SG_ 915 GK3_BK1_IDGeb_1_Sta 0;
BA_ "GenSigSendType" SG_ 915 GK3_BK1_IDGeb_1_Sta 3;
BA_ "GenSigAutoGenSnd" SG_ 915 GK3_BK1_IDGeb_1_Sta 1;
BA_ "GenSigAutoGenDsp" SG_ 915 GK3_BK1_IDGeb_1_Sta 1;
BA_ "GenSigSwitchedByIgnition" SG_ 915 GK3_BK1_IDGeb_2_Sta 0;
BA_ "GenSigSendType" SG_ 915 GK3_BK1_IDGeb_2_Sta 3;
BA_ "GenSigAutoGenSnd" SG_ 915 GK3_BK1_IDGeb_2_Sta 1;
BA_ "GenSigAutoGenDsp" SG_ 915 GK3_BK1_IDGeb_2_Sta 1;
BA_ "GenSigSwitchedByIgnition" SG_ 915 ME1_EasyEntry_Menu 0;
BA_ "GenSigSendType" SG_ 915 ME1_EasyEntry_Menu 0;
BA_ "GenSigAutoGenSnd" SG_ 915 ME1_EasyEntry_Menu 1;
BA_ "GenSigAutoGenDsp" SG_ 915 ME1_EasyEntry_Menu 1;
BA_ "GenSigSwitchedByIgnition" SG_ 915 ME1_EasyEntry_aktiv 0;
BA_ "GenSigSendType" SG_ 915 ME1_EasyEntry_aktiv 3;
BA_ "GenSigAutoGenSnd" SG_ 915 ME1_EasyEntry_aktiv 1;
BA_ "GenSigAutoGenDsp" SG_ 915 ME1_EasyEntry_aktiv 1;
BA_ "GenSigSwitchedByIgnition" SG_ 915 GK3_BK1_IDGeb_3_Sta 0;
BA_ "GenSigSendType" SG_ 915 GK3_BK1_IDGeb_3_Sta 3;
BA_ "GenSigAutoGenSnd" SG_ 915 GK3_BK1_IDGeb_3_Sta 1;
BA_ "GenSigAutoGenDsp" SG_ 915 GK3_BK1_IDGeb_3_Sta 1;
BA_ "GenSigSwitchedByIgnition" SG_ 915 GK3_BK1_IDGeb_4_Sta 0;
BA_ "GenSigSendType" SG_ 915 GK3_BK1_IDGeb_4_Sta 3;
BA_ "GenSigAutoGenSnd" SG_ 915 GK3_BK1_IDGeb_4_Sta 1;
BA_ "GenSigAutoGenDsp" SG_ 915 GK3_BK1_IDGeb_4_Sta 1;
BA_ "GenSigSwitchedByIgnition" SG_ 915 GK3_BK1_Anlern_Info 0;
BA_ "GenSigSendType" SG_ 915 GK3_BK1_Anlern_Info 3;
BA_ "GenSigAutoGenSnd" SG_ 915 GK3_BK1_Anlern_Info 1;
BA_ "GenSigAutoGenDsp" SG_ 915 GK3_BK1_Anlern_Info 1;
BA_ "GenSigSwitchedByIgnition" SG_ 915 CL3_SH_Wasserpumpe 0;
BA_ "GenSigSendType" SG_ 915 CL3_SH_Wasserpumpe 3;
BA_ "GenSigAutoGenSnd" SG_ 915 CL3_SH_Wasserpumpe 1;
BA_ "GenSigAutoGenDsp" SG_ 915 CL3_SH_Wasserpumpe 1;
BA_ "GenSigSwitchedByIgnition" SG_ 915 FT3_Auto_eKiSi_Menu 0;
BA_ "GenSigSendType" SG_ 915 FT3_Auto_eKiSi_Menu 0;
BA_ "GenSigAutoGenSnd" SG_ 915 FT3_Auto_eKiSi_Menu 1;
BA_ "GenSigAutoGenDsp" SG_ 915 FT3_Auto_eKiSi_Menu 1;
BA_ "GenSigSwitchedByIgnition" SG_ 915 FT3_Auto_eKiSi_Aktiv 0;
BA_ "GenSigSendType" SG_ 915 FT3_Auto_eKiSi_Aktiv 3;
BA_ "GenSigAutoGenSnd" SG_ 915 FT3_Auto_eKiSi_Aktiv 1;
BA_ "GenSigAutoGenDsp" SG_ 915 FT3_Auto_eKiSi_Aktiv 1;
BA_ "GenSigSwitchedByIgnition" SG_ 915 MKE_Texte 0;
BA_ "GenSigSendType" SG_ 915 MKE_Texte 0;
BA_ "GenSigAutoGenSnd" SG_ 915 MKE_Texte 1;
BA_ "GenSigAutoGenDsp" SG_ 915 MKE_Texte 1;
BA_ "GenSigSwitchedByIgnition" SG_ 915 HSA_unplausibel 0;
BA_ "GenSigSendType" SG_ 915 HSA_unplausibel 3;
BA_ "GenSigSwitchedByIgnition" SG_ 915 CHA_Kombi_Texte 0;
BA_ "GenSigSendType" SG_ 915 CHA_Kombi_Texte 1;
BA_ "GenSigSwitchedByIgnition" SG_ 915 HD1_Position 0;
BA_ "GenSigSendType" SG_ 915 HD1_Position 3;
BA_ "GenSigAutoGenSnd" SG_ 915 HD1_Position 1;
BA_ "GenSigAutoGenDsp" SG_ 915 HD1_Position 1;
BA_ "GenSigSwitchedByIgnition" SG_ 921 GK1_Sta_LSM 0;
BA_ "GenSigFuncType" SG_ 921 GK1_Sta_LSM 5;
BA_ "GenSigStartValue" SG_ 921 GK1_Sta_LSM 1;
BA_ "GenSigSendType" SG_ 921 GK1_Sta_LSM 0;
BA_ "GenSigAutoGenSnd" SG_ 921 GK1_Sta_LSM 1;
BA_ "GenSigAutoGenDsp" SG_ 921 GK1_Sta_LSM 1;
BA_ "GenSigSwitchedByIgnition" SG_ 921 GK4_Sta_MFA_6 0;
BA_ "GenSigFuncType" SG_ 921 GK4_Sta_MFA_6 5;
BA_ "GenSigStartValue" SG_ 921 GK4_Sta_MFA_6 1;
BA_ "GenSigSendType" SG_ 921 GK4_Sta_MFA_6 0;
BA_ "GenSigAutoGenSnd" SG_ 921 GK4_Sta_MFA_6 1;
BA_ "GenSigAutoGenDsp" SG_ 921 GK4_Sta_MFA_6 1;
BA_ "GenSigSwitchedByIgnition" SG_ 921 LS1_P_verriegelt 0;
BA_ "GenSigSendType" SG_ 921 LS1_P_verriegelt 3;
BA_ "GenSigAutoGenSnd" SG_ 921 LS1_P_verriegelt 1;
BA_ "GenSigAutoGenDsp" SG_ 921 LS1_P_verriegelt 1;
BA_ "GenSigSwitchedByIgnition" SG_ 921 GK4_Ladesteckerentr_Anf 0;
BA_ "GenSigSendType" SG_ 921 GK4_Ladesteckerentr_Anf 0;
BA_ "GenSigSwitchedByIgnition" SG_ 921 MA6_Reichweite 0;
BA_ "GenSigSendType" SG_ 921 MA6_Reichweite 0;
BA_ "GenSigAutoGenSnd" SG_ 921 MA6_Reichweite 1;
BA_ "GenSigAutoGenDsp" SG_ 921 MA6_Reichweite 1;
BA_ "GenSigSwitchedByIgnition" SG_ 921 MA6_km_Reichweite 0;
BA_ "GenSigSendType" SG_ 921 MA6_km_Reichweite 0;
BA_ "GenSigAutoGenSnd" SG_ 921 MA6_km_Reichweite 1;
BA_ "GenSigAutoGenDsp" SG_ 921 MA6_km_Reichweite 1;
BA_ "GenSigSwitchedByIgnition" SG_ 921 MA6_mls_Reichweite 0;
BA_ "GenSigSendType" SG_ 921 MA6_mls_Reichweite 0;
BA_ "GenSigAutoGenSnd" SG_ 921 MA6_mls_Reichweite 1;
BA_ "GenSigAutoGenDsp" SG_ 921 MA6_mls_Reichweite 1;
BA_ "GenSigFuncType" SG_ 684 GS1_Zaehler 1;
BA_ "GenSigSendType" SG_ 684 GS1_Zaehler 0;
BA_ "GenSigAutoGenSnd" SG_ 684 GS1_Zaehler 1;
BA_ "GenSigAutoGenDsp" SG_ 684 GS1_Zaehler 1;
BA_ "GenSigSendType" SG_ 684 GS1_Fahrtrichtung 0;
BA_ "GenSigAutoGenSnd" SG_ 684 GS1_Fahrtrichtung 1;
BA_ "GenSigAutoGenDsp" SG_ 684 GS1_Fahrtrichtung 1;
BA_ "GenSigStartValue" SG_ 684 GS1_QBit_Rad_kmh 1;
BA_ "GenSigSendType" SG_ 684 GS1_QBit_Rad_kmh 0;
BA_ "GenSigAutoGenSnd" SG_ 684 GS1_QBit_Rad_kmh 1;
BA_ "GenSigAutoGenDsp" SG_ 684 GS1_QBit_Rad_kmh 1;
BA_ "GenSigStartValue" SG_ 684 GS1_Rad_kmh 65416;
BA_ "GenSigSendType" SG_ 684 GS1_Rad_kmh 0;
BA_ "GenSigAutoGenSnd" SG_ 684 GS1_Rad_kmh 1;
BA_ "GenSigAutoGenDsp" SG_ 684 GS1_Rad_kmh 1;
BA_ "GenSigFuncType" SG_ 684 GS1_Checksumme 4;
BA_ "GenSigSendType" SG_ 684 GS1_Checksumme 0;
BA_ "GenSigAutoGenSnd" SG_ 684 GS1_Checksumme 1;
BA_ "GenSigAutoGenDsp" SG_ 684 GS1_Checksumme 1;
BA_ "GenSigSendType" SG_ 1088 GE1_Schaltung 0;
BA_ "GenSigAutoGenSnd" SG_ 1088 GE1_Schaltung 1;
BA_ "GenSigAutoGenDsp" SG_ 1088 GE1_Schaltung 1;
BA_ "GenSigSendType" SG_ 1088 GE1_Sta_Schutz 0;
BA_ "GenSigAutoGenSnd" SG_ 1088 GE1_Sta_Schutz 1;
BA_ "GenSigAutoGenDsp" SG_ 1088 GE1_Sta_Schutz 1;
BA_ "GenSigSendType" SG_ 1088 GE1_Klimakompr 0;
BA_ "GenSigAutoGenSnd" SG_ 1088 GE1_Klimakompr 1;
BA_ "GenSigAutoGenDsp" SG_ 1088 GE1_Klimakompr 1;
BA_ "Fehlerwert" SG_ 1088 GE1_WK 3;
BA_ "GenSigSendType" SG_ 1088 GE1_WK 0;
BA_ "GenSigAutoGenSnd" SG_ 1088 GE1_WK 1;
BA_ "GenSigAutoGenDsp" SG_ 1088 GE1_WK 1;
BA_ "GenSigSendType" SG_ 1088 GE1_StSt_Info 0;
BA_ "GenSigAutoGenSnd" SG_ 1088 GE1_StSt_Info 1;
BA_ "GenSigAutoGenDsp" SG_ 1088 GE1_StSt_Info 1;
BA_ "GenSigSendType" SG_ 1088 GE1_EGS_Anf 0;
BA_ "GenSigAutoGenSnd" SG_ 1088 GE1_EGS_Anf 1;
BA_ "GenSigAutoGenDsp" SG_ 1088 GE1_EGS_Anf 1;
BA_ "Fehlerwert" SG_ 1088 GE1_Zielgang 15;
BA_ "GenSigSendType" SG_ 1088 GE1_Zielgang 0;
BA_ "GenSigAutoGenSnd" SG_ 1088 GE1_Zielgang 1;
BA_ "GenSigAutoGenDsp" SG_ 1088 GE1_Zielgang 1;
BA_ "Fehlerwert" SG_ 1088 GE1_Wahl_Pos 15;
BA_ "GenSigSendType" SG_ 1088 GE1_Wahl_Pos 0;
BA_ "GenSigAutoGenSnd" SG_ 1088 GE1_Wahl_Pos 1;
BA_ "GenSigAutoGenDsp" SG_ 1088 GE1_Wahl_Pos 1;
BA_ "Fehlerwert" SG_ 1088 GE1_Mrad_Mkurb 255;
BA_ "GenSigSendType" SG_ 1088 GE1_Mrad_Mkurb 0;
BA_ "GenSigAutoGenSnd" SG_ 1088 GE1_Mrad_Mkurb 1;
BA_ "GenSigAutoGenDsp" SG_ 1088 GE1_Mrad_Mkurb 1;
BA_ "Fehlerwert" SG_ 1088 GE1_Soll_Mo 255;
BA_ "GenSigStartValue" SG_ 1088 GE1_Soll_Mo 254;
BA_ "GenSigSendType" SG_ 1088 GE1_Soll_Mo 0;
BA_ "GenSigAutoGenSnd" SG_ 1088 GE1_Soll_Mo 1;
BA_ "GenSigAutoGenDsp" SG_ 1088 GE1_Soll_Mo 1;
BA_ "Fehlerwert" SG_ 1088 GE1_Fahrwistd 255;
BA_ "GenSigStartValue" SG_ 1088 GE1_Fahrwistd 127;
BA_ "GenSigSendType" SG_ 1088 GE1_Fahrwistd 0;
BA_ "GenSigAutoGenSnd" SG_ 1088 GE1_Fahrwistd 1;
BA_ "GenSigAutoGenDsp" SG_ 1088 GE1_Fahrwistd 1;
BA_ "GenSigSendType" SG_ 1088 GE1_Notlauf 0;
BA_ "GenSigAutoGenSnd" SG_ 1088 GE1_Notlauf 1;
BA_ "GenSigAutoGenDsp" SG_ 1088 GE1_Notlauf 1;
BA_ "GenSigSendType" SG_ 1088 GE1_Kuehlung 0;
BA_ "GenSigAutoGenSnd" SG_ 1088 GE1_Kuehlung 1;
BA_ "GenSigAutoGenDsp" SG_ 1088 GE1_Kuehlung 1;
BA_ "GenSigSendType" SG_ 1088 GE1_Sta_OBD 0;
BA_ "GenSigAutoGenSnd" SG_ 1088 GE1_Sta_OBD 1;
BA_ "GenSigAutoGenDsp" SG_ 1088 GE1_Sta_OBD 1;
BA_ "GenSigSendType" SG_ 1088 GE1_LaunchControl 0;
BA_ "GenSigAutoGenSnd" SG_ 1088 GE1_LaunchControl 1;
BA_ "GenSigAutoGenDsp" SG_ 1088 GE1_LaunchControl 1;
BA_ "GenSigSendType" SG_ 1088 GE1_Infobit 0;
BA_ "GenSigAutoGenSnd" SG_ 1088 GE1_Infobit 1;
BA_ "GenSigAutoGenDsp" SG_ 1088 GE1_Infobit 1;
BA_ "GenSigSwitchedByIgnition" SG_ 1088 GE1_SleepInd 0;
BA_ "GenSigSendType" SG_ 1088 GE1_SleepInd 0;
BA_ "GenSigAutoGenSnd" SG_ 1088 GE1_SleepInd 1;
BA_ "GenSigAutoGenDsp" SG_ 1088 GE1_SleepInd 1;
BA_ "GenSigSwitchedByIgnition" SG_ 1088 GE1_Zaehler 0;
BA_ "GenSigFuncType" SG_ 1088 GE1_Zaehler 1;
BA_ "GenSigSendType" SG_ 1088 GE1_Zaehler 0;
BA_ "GenSigAutoGenSnd" SG_ 1088 GE1_Zaehler 1;
BA_ "GenSigAutoGenDsp" SG_ 1088 GE1_Zaehler 1;
BA_ "GenSigSwitchedByIgnition" SG_ 1088 GE1_Fehlereintr 0;
BA_ "GenSigSendType" SG_ 1088 GE1_Fehlereintr 0;
BA_ "GenSigAutoGenSnd" SG_ 1088 GE1_Fehlereintr 1;
BA_ "GenSigAutoGenDsp" SG_ 1088 GE1_Fehlereintr 1;
BA_ "Fehlerwert" SG_ 1088 GE1_WaVerl_Mo 255;
BA_ "GenSigSendType" SG_ 1088 GE1_WaVerl_Mo 0;
BA_ "GenSigAutoGenSnd" SG_ 1088 GE1_WaVerl_Mo 1;
BA_ "GenSigAutoGenDsp" SG_ 1088 GE1_WaVerl_Mo 1;
BA_ "GenSigSendType" SG_ 1344 GE2_LFR_Adap 0;
BA_ "GenSigAutoGenSnd" SG_ 1344 GE2_LFR_Adap 1;
BA_ "GenSigAutoGenDsp" SG_ 1344 GE2_LFR_Adap 1;
BA_ "GenSigSendType" SG_ 1344 GE2_Sta_SAS 0;
BA_ "GenSigAutoGenSnd" SG_ 1344 GE2_Sta_SAS 1;
BA_ "GenSigAutoGenDsp" SG_ 1344 GE2_Sta_SAS 1;
BA_ "GenSigSendType" SG_ 1344 GE2_SlipStDZEingr 0;
BA_ "GenSigAutoGenSnd" SG_ 1344 GE2_SlipStDZEingr 1;
BA_ "GenSigAutoGenDsp" SG_ 1344 GE2_SlipStDZEingr 1;
BA_ "GenSigSendType" SG_ 1344 GE2_Sta_ZwGas 0;
BA_ "GenSigAutoGenSnd" SG_ 1344 GE2_Sta_ZwGas 1;
BA_ "GenSigAutoGenDsp" SG_ 1344 GE2_Sta_ZwGas 1;
BA_ "GenSigSwitchedByIgnition" SG_ 1344 GE2_Zaehler 0;
BA_ "GenSigFuncType" SG_ 1344 GE2_Zaehler 1;
BA_ "GenSigSendType" SG_ 1344 GE2_Zaehler 0;
BA_ "GenSigAutoGenSnd" SG_ 1344 GE2_Zaehler 1;
BA_ "GenSigAutoGenDsp" SG_ 1344 GE2_Zaehler 1;
BA_ "Fehlerwert" SG_ 1344 GE2_LL_Solldz 255;
BA_ "GenSigSendType" SG_ 1344 GE2_LL_Solldz 0;
BA_ "GenSigAutoGenSnd" SG_ 1344 GE2_LL_Solldz 1;
BA_ "GenSigAutoGenDsp" SG_ 1344 GE2_LL_Solldz 1;
BA_ "GenSigStartValue" SG_ 1344 GE2_Grad_begr 255;
BA_ "GenSigSendType" SG_ 1344 GE2_Grad_begr 0;
BA_ "GenSigAutoGenSnd" SG_ 1344 GE2_Grad_begr 1;
BA_ "GenSigAutoGenDsp" SG_ 1344 GE2_Grad_begr 1;
BA_ "GenSigSendType" SG_ 1344 GE2_Sync_Dz 0;
BA_ "GenSigAutoGenSnd" SG_ 1344 GE2_Sync_Dz 1;
BA_ "GenSigAutoGenDsp" SG_ 1344 GE2_Sync_Dz 1;
BA_ "GenSigStartValue" SG_ 1344 GE2_invSync_Dz 255;
BA_ "GenSigSendType" SG_ 1344 GE2_invSync_Dz 0;
BA_ "GenSigAutoGenSnd" SG_ 1344 GE2_invSync_Dz 1;
BA_ "GenSigAutoGenDsp" SG_ 1344 GE2_invSync_Dz 1;
BA_ "Fehlerwert" SG_ 1344 GE2_Sync_Zeit 255;
BA_ "GenSigSendType" SG_ 1344 GE2_Sync_Zeit 0;
BA_ "GenSigAutoGenSnd" SG_ 1344 GE2_Sync_Zeit 1;
BA_ "GenSigAutoGenDsp" SG_ 1344 GE2_Sync_Zeit 1;
BA_ "GenSigSendType" SG_ 1344 GE2_DZM_Daempf 0;
BA_ "GenSigAutoGenSnd" SG_ 1344 GE2_DZM_Daempf 1;
BA_ "GenSigAutoGenDsp" SG_ 1344 GE2_DZM_Daempf 1;
BA_ "GenSigStartValue" SG_ 1344 GE2_invMSB_Sync 1;
BA_ "GenSigSendType" SG_ 1344 GE2_invMSB_Sync 0;
BA_ "GenSigAutoGenSnd" SG_ 1344 GE2_invMSB_Sync 1;
BA_ "GenSigAutoGenDsp" SG_ 1344 GE2_invMSB_Sync 1;
BA_ "GenSigSendType" SG_ 1344 GE2_Gong 0;
BA_ "GenSigAutoGenSnd" SG_ 1344 GE2_Gong 1;
BA_ "GenSigAutoGenDsp" SG_ 1344 GE2_Gong 1;
BA_ "GenSigSendType" SG_ 1344 GE2_Segeln_aktiv 0;
BA_ "GenSigAutoGenSnd" SG_ 1344 GE2_Segeln_aktiv 1;
BA_ "GenSigAutoGenDsp" SG_ 1344 GE2_Segeln_aktiv 1;
BA_ "GenSigSendType" SG_ 1344 GE2_Shift_Lock 0;
BA_ "GenSigAutoGenSnd" SG_ 1344 GE2_Shift_Lock 1;
BA_ "GenSigAutoGenDsp" SG_ 1344 GE2_Shift_Lock 1;
BA_ "GenSigSendType" SG_ 1344 GE2_Senderkennung 0;
BA_ "GenSigAutoGenSnd" SG_ 1344 GE2_Senderkennung 1;
BA_ "GenSigAutoGenDsp" SG_ 1344 GE2_Senderkennung 1;
BA_ "GenSigSendType" SG_ 1344 GE2_MSB_Sync 0;
BA_ "GenSigAutoGenSnd" SG_ 1344 GE2_MSB_Sync 1;
BA_ "GenSigAutoGenDsp" SG_ 1344 GE2_MSB_Sync 1;
BA_ "GenSigSendType" SG_ 1344 GE2_WBA_Blinken 0;
BA_ "GenSigAutoGenSnd" SG_ 1344 GE2_WBA_Blinken 1;
BA_ "GenSigAutoGenDsp" SG_ 1344 GE2_WBA_Blinken 1;
BA_ "GenSigSendType" SG_ 1344 GE2_Variante 0;
BA_ "GenSigAutoGenSnd" SG_ 1344 GE2_Variante 1;
BA_ "GenSigAutoGenDsp" SG_ 1344 GE2_Variante 1;
BA_ "GenSigAutoGenSnd" SG_ 1344 GE2_5Gang 1;
BA_ "GenSigAutoGenDsp" SG_ 1344 GE2_5Gang 1;
BA_ "GenSigAutoGenSnd" SG_ 1344 GE2_PRND 1;
BA_ "GenSigAutoGenDsp" SG_ 1344 GE2_PRND 1;
BA_ "GenSigAutoGenSnd" SG_ 1344 GE2_4Gang 1;
BA_ "GenSigAutoGenDsp" SG_ 1344 GE2_4Gang 1;
BA_ "GenSigAutoGenSnd" SG_ 1344 GE2_ASG 1;
BA_ "GenSigAutoGenDsp" SG_ 1344 GE2_ASG 1;
BA_ "GenSigAutoGenSnd" SG_ 1344 GE2_Selespeed 1;
BA_ "GenSigAutoGenDsp" SG_ 1344 GE2_Selespeed 1;
BA_ "GenSigAutoGenSnd" SG_ 1344 GE2_res_MUX5 1;
BA_ "GenSigAutoGenDsp" SG_ 1344 GE2_res_MUX5 1;
BA_ "GenSigAutoGenSnd" SG_ 1344 GE2_PRNDS 1;
BA_ "GenSigAutoGenDsp" SG_ 1344 GE2_PRNDS 1;
BA_ "GenSigAutoGenSnd" SG_ 1344 GE2_PRNED 1;
BA_ "GenSigAutoGenDsp" SG_ 1344 GE2_PRNED 1;
BA_ "GenSigAutoGenSnd" SG_ 1344 GE2_Tip4Gang 1;
BA_ "GenSigAutoGenDsp" SG_ 1344 GE2_Tip4Gang 1;
BA_ "GenSigAutoGenSnd" SG_ 1344 GE2_Tip5Gang 1;
BA_ "GenSigAutoGenDsp" SG_ 1344 GE2_Tip5Gang 1;
BA_ "GenSigAutoGenSnd" SG_ 1344 GE2_res_MUX10 1;
BA_ "GenSigAutoGenDsp" SG_ 1344 GE2_res_MUX10 1;
BA_ "GenSigAutoGenSnd" SG_ 1344 GE2_PRNDB 1;
BA_ "GenSigAutoGenDsp" SG_ 1344 GE2_PRNDB 1;
BA_ "GenSigAutoGenSnd" SG_ 1344 GE2_Tip6Gang 1;
BA_ "GenSigAutoGenDsp" SG_ 1344 GE2_Tip6Gang 1;
BA_ "GenSigAutoGenSnd" SG_ 1344 GE2_Tip7Gang 1;
BA_ "GenSigAutoGenDsp" SG_ 1344 GE2_Tip7Gang 1;
BA_ "GenSigAutoGenSnd" SG_ 1344 GE2_Tip8Gang 1;
BA_ "GenSigAutoGenDsp" SG_ 1344 GE2_Tip8Gang 1;
BA_ "GenSigAutoGenSnd" SG_ 1344 GE2_akt_Gang 1;
BA_ "GenSigAutoGenDsp" SG_ 1344 GE2_akt_Gang 1;
BA_ "GenSigSwitchedByIgnition" SG_ 1090 GM3_Checksum 0;
BA_ "GenSigFuncType" SG_ 1090 GM3_Checksum 4;
BA_ "GenSigSendType" SG_ 1090 GM3_Checksum 0;
BA_ "GenSigAutoGenSnd" SG_ 1090 GM3_Checksum 1;
BA_ "GenSigAutoGenDsp" SG_ 1090 GM3_Checksum 1;
BA_ "GenSigSwitchedByIgnition" SG_ 1090 GM3_Zaehler 0;
BA_ "GenSigFuncType" SG_ 1090 GM3_Zaehler 1;
BA_ "GenSigSendType" SG_ 1090 GM3_Zaehler 0;
BA_ "GenSigAutoGenSnd" SG_ 1090 GM3_Zaehler 1;
BA_ "GenSigAutoGenDsp" SG_ 1090 GM3_Zaehler 1;
BA_ "GenSigSendType" SG_ 1090 GM3_MomEingr 0;
BA_ "GenSigAutoGenSnd" SG_ 1090 GM3_MomEingr 1;
BA_ "GenSigAutoGenDsp" SG_ 1090 GM3_MomEingr 1;
BA_ "Fehlerwert" SG_ 1090 GM3_MoSoMom 1023;
BA_ "GenSigStartValue" SG_ 1090 GM3_MoSoMom 1022;
BA_ "GenSigSendType" SG_ 1090 GM3_MoSoMom 0;
BA_ "GenSigAutoGenSnd" SG_ 1090 GM3_MoSoMom 1;
BA_ "GenSigAutoGenDsp" SG_ 1090 GM3_MoSoMom 1;
BA_ "Fehlerwert" SG_ 1090 GM3_StaSoMom 3;
BA_ "GenSigSendType" SG_ 1090 GM3_StaSoMom 0;
BA_ "GenSigAutoGenSnd" SG_ 1090 GM3_StaSoMom 1;
BA_ "GenSigAutoGenDsp" SG_ 1090 GM3_StaSoMom 1;
BA_ "Fehlerwert" SG_ 1090 GM3_MomID 15;
BA_ "GenSigSendType" SG_ 1090 GM3_MomID 0;
BA_ "GenSigAutoGenSnd" SG_ 1090 GM3_MomID 1;
BA_ "GenSigAutoGenDsp" SG_ 1090 GM3_MomID 1;
BA_ "GenSigSendType" SG_ 1090 GM3_Zeit 0;
BA_ "GenSigAutoGenSnd" SG_ 1090 GM3_Zeit 1;
BA_ "GenSigAutoGenDsp" SG_ 1090 GM3_Zeit 1;
BA_ "GenSigStartValue" SG_ 1090 GM3_Moment 1023;
BA_ "GenSigSendType" SG_ 1090 GM3_Moment 0;
BA_ "GenSigAutoGenSnd" SG_ 1090 GM3_Moment 1;
BA_ "GenSigAutoGenDsp" SG_ 1090 GM3_Moment 1;
BA_ "GenSigStartValue" SG_ 1090 GM3_QB_LangEingr 1;
BA_ "GenSigSendType" SG_ 1090 GM3_QB_LangEingr 0;
BA_ "GenSigAutoGenSnd" SG_ 1090 GM3_QB_LangEingr 1;
BA_ "GenSigAutoGenDsp" SG_ 1090 GM3_QB_LangEingr 1;
BA_ "Fehlerwert" SG_ 1090 GM3_LangEingr 1023;
BA_ "GenSigStartValue" SG_ 1090 GM3_LangEingr 1022;
BA_ "GenSigSendType" SG_ 1090 GM3_LangEingr 0;
BA_ "GenSigAutoGenSnd" SG_ 1090 GM3_LangEingr 1;
BA_ "GenSigAutoGenDsp" SG_ 1090 GM3_LangEingr 1;
BA_ "GenSigSwitchedByIgnition" SG_ 1352 GE4_Shiftlock 0;
BA_ "GenSigStartValue" SG_ 1352 GE4_Shiftlock 1;
BA_ "GenSigSendType" SG_ 1352 GE4_Shiftlock 0;
BA_ "GenSigAutoGenSnd" SG_ 1352 GE4_Shiftlock 1;
BA_ "GenSigAutoGenDsp" SG_ 1352 GE4_Shiftlock 1;
BA_ "GenSigSwitchedByIgnition" SG_ 1352 GE4_AuslModus 0;
BA_ "GenSigSendType" SG_ 1352 GE4_AuslModus 0;
BA_ "GenSigAutoGenSnd" SG_ 1352 GE4_AuslModus 1;
BA_ "GenSigAutoGenDsp" SG_ 1352 GE4_AuslModus 1;
BA_ "GenSigSwitchedByIgnition" SG_ 1352 GE4_Test 0;
BA_ "GenSigSendType" SG_ 1352 GE4_Test 0;
BA_ "GenSigAutoGenSnd" SG_ 1352 GE4_Test 1;
BA_ "GenSigAutoGenDsp" SG_ 1352 GE4_Test 1;
BA_ "GenSigSwitchedByIgnition" SG_ 1352 GE4_Tasterausleuchtung 0;
BA_ "GenSigSendType" SG_ 1352 GE4_Tasterausleuchtung 0;
BA_ "Fehlerwert" SG_ 1352 GE4_Ausleuchtung 15;
BA_ "GenSigSwitchedByIgnition" SG_ 1352 GE4_Ausleuchtung 0;
BA_ "GenSigSendType" SG_ 1352 GE4_Ausleuchtung 0;
BA_ "GenSigAutoGenSnd" SG_ 1352 GE4_Ausleuchtung 1;
BA_ "GenSigAutoGenDsp" SG_ 1352 GE4_Ausleuchtung 1;
BA_ "GenSigSwitchedByIgnition" SG_ 1352 GE4_Testparam_1 0;
BA_ "GenSigSendType" SG_ 1352 GE4_Testparam_1 0;
BA_ "GenSigAutoGenSnd" SG_ 1352 GE4_Testparam_1 1;
BA_ "GenSigAutoGenDsp" SG_ 1352 GE4_Testparam_1 1;
BA_ "GenSigSwitchedByIgnition" SG_ 1352 GE4_Testparam_2 0;
BA_ "GenSigSendType" SG_ 1352 GE4_Testparam_2 0;
BA_ "GenSigAutoGenSnd" SG_ 1352 GE4_Testparam_2 1;
BA_ "GenSigAutoGenDsp" SG_ 1352 GE4_Testparam_2 1;
BA_ "GenSigSendType" SG_ 1346 GE5_Test 0;
BA_ "GenSigAutoGenSnd" SG_ 1346 GE5_Test 1;
BA_ "GenSigAutoGenDsp" SG_ 1346 GE5_Test 1;
BA_ "GenSigSendType" SG_ 1346 GE5_Abschalten 0;
BA_ "GenSigAutoGenSnd" SG_ 1346 GE5_Abschalten 1;
BA_ "GenSigAutoGenDsp" SG_ 1346 GE5_Abschalten 1;
BA_ "GenSigSendType" SG_ 1346 GE5_Sta_Fahrstufe 0;
BA_ "GenSigAutoGenSnd" SG_ 1346 GE5_Sta_Fahrstufe 1;
BA_ "GenSigAutoGenDsp" SG_ 1346 GE5_Sta_Fahrstufe 1;
BA_ "GenSigSendType" SG_ 1346 GE5_Ausl_Sport 0;
BA_ "GenSigAutoGenSnd" SG_ 1346 GE5_Ausl_Sport 1;
BA_ "GenSigAutoGenDsp" SG_ 1346 GE5_Ausl_Sport 1;
BA_ "GenSigSendType" SG_ 1346 GE5_Ausl_Winter 0;
BA_ "GenSigAutoGenSnd" SG_ 1346 GE5_Ausl_Winter 1;
BA_ "GenSigAutoGenDsp" SG_ 1346 GE5_Ausl_Winter 1;
BA_ "GenSigSendType" SG_ 1346 GE5_Ausleuchtung 0;
BA_ "GenSigAutoGenSnd" SG_ 1346 GE5_Ausleuchtung 1;
BA_ "GenSigAutoGenDsp" SG_ 1346 GE5_Ausleuchtung 1;
BA_ "GenSigSendType" SG_ 1346 GE5_Testparam_1 0;
BA_ "GenSigAutoGenSnd" SG_ 1346 GE5_Testparam_1 1;
BA_ "GenSigAutoGenDsp" SG_ 1346 GE5_Testparam_1 1;
BA_ "GenSigSendType" SG_ 1346 GE5_Testparam_2 0;
BA_ "GenSigAutoGenSnd" SG_ 1346 GE5_Testparam_2 1;
BA_ "GenSigAutoGenDsp" SG_ 1346 GE5_Testparam_2 1;
BA_REL_ "GenSigTimeoutTime" BU_SG_REL_ BMS_Hybrid SG_ 1578 Temp_nach_Chiller 5000;
BA_REL_ "GenSigTimeoutTime" BU_SG_REL_ Motor_Hybrid SG_ 1526 EK1_Comp_current 5000;
BA_REL_ "GenSigTimeoutTime" BU_SG_REL_ Gateway_PQ35 SG_ 1406 EY1_KD_Fehler 5000;
BA_REL_ "GenSigTimeoutTime" BU_SG_REL_ Bremse_MK60EC SG_ 1472 EP1_Zaehler 500;
BA_REL_ "GenSigTimeoutTime" BU_SG_REL_ Daempfer SG_ 1472 EP1_Zaehler 500;
BA_REL_ "GenSigTimeoutTime" BU_SG_REL_ Motor_Diesel SG_ 1472 EP1_Zaehler 500;
BA_REL_ "GenSigTimeoutTime" BU_SG_REL_ Motor_Otto SG_ 1472 EP1_Zaehler 500;
BA_REL_ "GenSigTimeoutTime" BU_SG_REL_ Bremse_MK60EC SG_ 1472 EP1_Fehler_Sta 500;
BA_REL_ "GenSigTimeoutTime" BU_SG_REL_ PDC_PLA SG_ 1472 EP1_Fehler_Sta 500;
BA_REL_ "GenSigTimeoutTime" BU_SG_REL_ Bremse_MK60EC SG_ 1472 EP1_Sta_EPB 500;
BA_REL_ "GenSigTimeoutTime" BU_SG_REL_ Getriebe_DQ SG_ 1472 EP1_Sta_EPB 500;
BA_REL_ "GenSigTimeoutTime" BU_SG_REL_ Getriebe_DQ_Hyb SG_ 1472 EP1_Sta_EPB 500;
BA_REL_ "GenSigTimeoutTime" BU_SG_REL_ PDC_PLA SG_ 1472 EP1_Sta_EPB 500;
BA_REL_ "GenSigTimeoutTime" BU_SG_REL_ Bremse_MK60EC SG_ 1472 EP1_Spannkraft 500;
BA_REL_ "GenSigTimeoutTime" BU_SG_REL_ Getriebe_DQ SG_ 1472 EP1_Spannkraft 500;
BA_REL_ "GenSigTimeoutTime" BU_SG_REL_ Getriebe_DQ_Hyb SG_ 1472 EP1_Spannkraft 500;
BA_REL_ "GenSigTimeoutTime" BU_SG_REL_ Motor_Diesel SG_ 1472 EP1_Schalterinfo 500;
BA_REL_ "GenSigTimeoutTime" BU_SG_REL_ Motor_Otto SG_ 1472 EP1_Schalterinfo 500;
BA_REL_ "GenSigTimeoutTime" BU_SG_REL_ Motor_Diesel SG_ 1472 EP1_Sta_NWS 500;
BA_REL_ "GenSigTimeoutTime" BU_SG_REL_ Motor_Otto SG_ 1472 EP1_Sta_NWS 500;
BA_REL_ "GenSigTimeoutTime" BU_SG_REL_ Motor_Diesel SG_ 1472 EP1_Neig_winkel 500;
BA_REL_ "GenSigTimeoutTime" BU_SG_REL_ Motor_Otto SG_ 1472 EP1_Neig_winkel 500;
BA_REL_ "GenSigTimeoutTime" BU_SG_REL_ Bremse_MK60EC SG_ 1472 EP1_Verzoegerung 500;
BA_REL_ "GenSigTimeoutTime" BU_SG_REL_ Daempfer SG_ 1472 EP1_Verzoegerung 500;
BA_REL_ "GenSigTimeoutTime" BU_SG_REL_ Gateway_PQ35 SG_ 1472 EP1_Fehlereintr 500;
BA_REL_ "GenSigTimeoutTime" BU_SG_REL_ Bremse_MK60EC SG_ 1472 EP1_Freigabe_Ver 500;
BA_REL_ "GenSigTimeoutTime" BU_SG_REL_ Daempfer SG_ 1472 EP1_Freigabe_Ver 500;
BA_REL_ "GenSigTimeoutTime" BU_SG_REL_ Motor_Diesel SG_ 1472 EP1_AutoHold_aktiv 500;
BA_REL_ "GenSigTimeoutTime" BU_SG_REL_ Motor_Otto SG_ 1472 EP1_AutoHold_aktiv 500;
BA_REL_ "GenSigTimeoutTime" BU_SG_REL_ Motor_Diesel SG_ 1472 EP1_KuppModBer 500;
BA_REL_ "GenSigTimeoutTime" BU_SG_REL_ Motor_Otto SG_ 1472 EP1_KuppModBer 500;
BA_REL_ "GenSigTimeoutTime" BU_SG_REL_ Getriebe_DQ SG_ 1472 EP1_HydrHalten 500;
BA_REL_ "GenSigTimeoutTime" BU_SG_REL_ Getriebe_DQ_Hyb SG_ 1472 EP1_HydrHalten 500;
BA_REL_ "GenSigTimeoutTime" BU_SG_REL_ Motor_Diesel SG_ 1472 EP1_HydrHalten 500;
BA_REL_ "GenSigTimeoutTime" BU_SG_REL_ Motor_Otto SG_ 1472 EP1_HydrHalten 500;
BA_REL_ "GenSigTimeoutTime" BU_SG_REL_ Bremse_MK60EC SG_ 1472 EP1_Fkt_Lampe 500;
BA_REL_ "GenSigTimeoutTime" BU_SG_REL_ Getriebe_DQ SG_ 1472 EP1__Text 500;
BA_REL_ "GenSigTimeoutTime" BU_SG_REL_ Getriebe_DQ_Hyb SG_ 1472 EP1__Text 500;
BA_REL_ "GenSigTimeoutTime" BU_SG_REL_ Bremse_MK60EC SG_ 1472 EP1_Checksum 500;
BA_REL_ "GenSigTimeoutTime" BU_SG_REL_ Daempfer SG_ 1472 EP1_Checksum 500;
BA_REL_ "GenSigTimeoutTime" BU_SG_REL_ Motor_Diesel SG_ 1472 EP1_Checksum 500;
BA_REL_ "GenSigTimeoutTime" BU_SG_REL_ Motor_Otto SG_ 1472 EP1_Checksum 500;
BA_REL_ "GenSigTimeoutTime" BU_SG_REL_ Gateway_PQ35 SG_ 1626 FL1_KD_Fehler 5000;
BA_REL_ "GenSigTimeoutTime" BU_SG_REL_ Bremse_MK60EC SG_ 912 GK1_Sta_Anhaen 1000;
BA_REL_ "GenSigTimeoutTime" BU_SG_REL_ Bremse_MK60EC SG_ 912 GK1_Sta_Anhaen 1000;
BA_REL_ "GenSigTimeoutTime" BU_SG_REL_ Bremse_TRW_EBC450M SG_ 912 GK1_Sta_Anhaen 1000;
BA_REL_ "GenSigTimeoutTime" BU_SG_REL_ Bremse_TRW_EBC450M SG_ 912 GK1_Sta_Anhaen 1000;
BA_REL_ "GenSigTimeoutTime" BU_SG_REL_ Bremse_TRW_ESP SG_ 912 GK1_Sta_Anhaen 1000;
BA_REL_ "GenSigTimeoutTime" BU_SG_REL_ Bremse_TRW_ESP SG_ 912 GK1_Sta_Anhaen 1000;
BA_REL_ "GenSigTimeoutTime" BU_SG_REL_ Getriebe_DQ SG_ 912 GK1_Sta_Anhaen 1000;
BA_REL_ "GenSigTimeoutTime" BU_SG_REL_ Getriebe_DQ_Hyb SG_ 912 GK1_Sta_Anhaen 1000;
BA_REL_ "GenSigTimeoutTime" BU_SG_REL_ HCA SG_ 912 GK1_Sta_Anhaen 1000;
BA_REL_ "GenSigTimeoutTime" BU_SG_REL_ Motor_Diesel SG_ 912 GK1_Sta_Anhaen 1000;
BA_REL_ "GenSigTimeoutTime" BU_SG_REL_ Motor_Otto SG_ 912 GK1_Sta_Anhaen 1000;
BA_REL_ "GenSigTimeoutTime" BU_SG_REL_ PDC_PLA SG_ 912 GK1_Sta_Anhaen 1000;
BA_REL_ "GenSigTimeoutTime" BU_SG_REL_ RKA_Plus SG_ 912 GK1_Sta_Anhaen 1000;
BA_REL_ "GenSigTimeoutTime" BU_SG_REL_ AFS SG_ 912 GK1_Sta_Licht1 1000;
BA_REL_ "GenSigTimeoutTime" BU_SG_REL_ Bremse_MK60EC SG_ 912 GK1_Sta_Licht1 1000;
BA_REL_ "GenSigTimeoutTime" BU_SG_REL_ Bremse_MK60EC SG_ 912 GK1_Sta_Licht1 1000;
BA_REL_ "GenSigTimeoutTime" BU_SG_REL_ Bremse_MK60EC SG_ 912 GK1_Sta_Licht1 1000;
BA_REL_ "GenSigTimeoutTime" BU_SG_REL_ Bremse_MK70MABS SG_ 912 GK1_Sta_Licht1 1000;
BA_REL_ "GenSigTimeoutTime" BU_SG_REL_ Bremse_TRW_EBC450M SG_ 912 GK1_Sta_Licht1 1000;
BA_REL_ "GenSigTimeoutTime" BU_SG_REL_ Bremse_TRW_EBC450M SG_ 912 GK1_Sta_Licht1 1000;
BA_REL_ "GenSigTimeoutTime" BU_SG_REL_ Bremse_TRW_ESP SG_ 912 GK1_Sta_Licht1 1000;
BA_REL_ "GenSigTimeoutTime" BU_SG_REL_ Bremse_TRW_ESP SG_ 912 GK1_Sta_Licht1 1000;
BA_REL_ "GenSigTimeoutTime" BU_SG_REL_ Bremse_TRW_ESP SG_ 912 GK1_Sta_Licht1 1000;
BA_REL_ "GenSigTimeoutTime" BU_SG_REL_ EPB_TRW SG_ 912 GK1_Sta_Licht1 1000;
BA_REL_ "GenSigTimeoutTime" BU_SG_REL_ EPB_TRW_VW411CS SG_ 912 GK1_Sta_Licht1 1000;
BA_REL_ "GenSigTimeoutTime" BU_SG_REL_ FLA SG_ 912 GK1_Sta_Licht1 1000;
BA_REL_ "GenSigTimeoutTime" BU_SG_REL_ LH_EPS_APA SG_ 912 GK1_Sta_Licht1 1000;
BA_REL_ "GenSigTimeoutTime" BU_SG_REL_ LH_EPS_ZF_2G SG_ 912 GK1_Sta_Licht1 1000;
BA_REL_ "GenSigTimeoutTime" BU_SG_REL_ LH_EPS_ZF_3G SG_ 912 GK1_Sta_Licht1 1000;
BA_REL_ "GenSigTimeoutTime" BU_SG_REL_ Motor_Diesel SG_ 912 GK1_Sta_Licht1 1000;
BA_REL_ "GenSigTimeoutTime" BU_SG_REL_ Motor_Otto SG_ 912 GK1_Sta_Licht1 1000;
BA_REL_ "GenSigTimeoutTime" BU_SG_REL_ PDC_PLA SG_ 912 GK1_Sta_Licht1 1000;
BA_REL_ "GenSigTimeoutTime" BU_SG_REL_ PDC_PLA SG_ 912 GK1_Sta_Licht1 1000;
BA_REL_ "GenSigTimeoutTime" BU_SG_REL_ AFS SG_ 912 GK1_Sta_Licht3 1000;
BA_REL_ "GenSigTimeoutTime" BU_SG_REL_ Bremse_MK60EC SG_ 912 GK1_Sta_Tuerkont 1000;
BA_REL_ "GenSigTimeoutTime" BU_SG_REL_ Bremse_MK70MABS SG_ 912 GK1_Sta_Tuerkont 1000;
BA_REL_ "GenSigTimeoutTime" BU_SG_REL_ Bremse_TRW_EBC450M SG_ 912 GK1_Sta_Tuerkont 1000;
BA_REL_ "GenSigTimeoutTime" BU_SG_REL_ Bremse_TRW_ESP SG_ 912 GK1_Sta_Tuerkont 1000;
BA_REL_ "GenSigTimeoutTime" BU_SG_REL_ EPB_TRW SG_ 912 GK1_Sta_Tuerkont 1000;
BA_REL_ "GenSigTimeoutTime" BU_SG_REL_ EPB_TRW_VW411CS SG_ 912 GK1_Sta_Tuerkont 1000;
BA_REL_ "GenSigTimeoutTime" BU_SG_REL_ Getriebe_DQ SG_ 912 GK1_Sta_Tuerkont 1000;
BA_REL_ "GenSigTimeoutTime" BU_SG_REL_ Getriebe_DQ_Hyb SG_ 912 GK1_Sta_Tuerkont 1000;
BA_REL_ "GenSigTimeoutTime" BU_SG_REL_ Motor_Diesel SG_ 912 GK1_Sta_Tuerkont 1000;
BA_REL_ "GenSigTimeoutTime" BU_SG_REL_ Motor_Diesel SG_ 912 GK1_Sta_Tuerkont 1000;
BA_REL_ "GenSigTimeoutTime" BU_SG_REL_ Motor_Diesel SG_ 912 GK1_Sta_Tuerkont 1000;
BA_REL_ "GenSigTimeoutTime" BU_SG_REL_ Motor_Diesel SG_ 912 GK1_Sta_Tuerkont 1000;
BA_REL_ "GenSigTimeoutTime" BU_SG_REL_ Motor_Hybrid SG_ 912 GK1_Sta_Tuerkont 1000;
BA_REL_ "GenSigTimeoutTime" BU_SG_REL_ Motor_Otto SG_ 912 GK1_Sta_Tuerkont 1000;
BA_REL_ "GenSigTimeoutTime" BU_SG_REL_ Motor_Otto SG_ 912 GK1_Sta_Tuerkont 1000;
BA_REL_ "GenSigTimeoutTime" BU_SG_REL_ Motor_Otto SG_ 912 GK1_Sta_Tuerkont 1000;
BA_REL_ "GenSigTimeoutTime" BU_SG_REL_ Motor_Otto SG_ 912 GK1_Sta_Tuerkont 1000;
BA_REL_ "GenSigTimeoutTime" BU_SG_REL_ PDC_PLA SG_ 912 GK1_Sta_Tuerkont 1000;
BA_REL_ "GenSigTimeoutTime" BU_SG_REL_ AFS SG_ 912 GK1_Sta_Li_vorn 1000;
BA_REL_ "GenSigTimeoutTime" BU_SG_REL_ Bremse_MK60EC SG_ 912 GK1_SleepAckn 1000;
BA_REL_ "GenSigTimeoutTime" BU_SG_REL_ Bremse_MK70MABS SG_ 912 GK1_SleepAckn 1000;
BA_REL_ "GenSigTimeoutTime" BU_SG_REL_ Bremse_TRW_ESP SG_ 912 GK1_SleepAckn 1000;
BA_REL_ "GenSigTimeoutTime" BU_SG_REL_ EPB_TRW SG_ 912 GK1_SleepAckn 1000;
BA_REL_ "GenSigTimeoutTime" BU_SG_REL_ Getriebe_AG6 SG_ 912 GK1_SleepAckn 1000;
BA_REL_ "GenSigTimeoutTime" BU_SG_REL_ Getriebe_DQ SG_ 912 GK1_SleepAckn 1000;
BA_REL_ "GenSigTimeoutTime" BU_SG_REL_ Getriebe_DQ_Hyb SG_ 912 GK1_SleepAckn 1000;
BA_REL_ "GenSigTimeoutTime" BU_SG_REL_ Getriebe_Sele SG_ 912 GK1_SleepAckn 1000;
BA_REL_ "GenSigTimeoutTime" BU_SG_REL_ LH_EPS_APA SG_ 912 GK1_SleepAckn 1000;
BA_REL_ "GenSigTimeoutTime" BU_SG_REL_ LH_EPS_ZF_2G SG_ 912 GK1_SleepAckn 1000;
BA_REL_ "GenSigTimeoutTime" BU_SG_REL_ LH_EPS_ZF_3G SG_ 912 GK1_SleepAckn 1000;
BA_REL_ "GenSigTimeoutTime" BU_SG_REL_ LWS SG_ 912 GK1_SleepAckn 1000;
BA_REL_ "GenSigTimeoutTime" BU_SG_REL_ Motor_Diesel SG_ 912 GK1_SleepAckn 1000;
BA_REL_ "GenSigTimeoutTime" BU_SG_REL_ Motor_Hybrid SG_ 912 GK1_SleepAckn 1000;
BA_REL_ "GenSigTimeoutTime" BU_SG_REL_ Motor_Otto SG_ 912 GK1_SleepAckn 1000;
BA_REL_ "GenSigTimeoutTime" BU_SG_REL_ Waehlhebel SG_ 912 GK1_SleepAckn 1000;
BA_REL_ "GenSigTimeoutTime" BU_SG_REL_ Daempfer SG_ 912 GK1_CharismaModus 1000;
BA_REL_ "GenSigTimeoutTime" BU_SG_REL_ Getriebe_AG6 SG_ 912 GK1_CharismaModus 1000;
BA_REL_ "GenSigTimeoutTime" BU_SG_REL_ Getriebe_DQ SG_ 912 GK1_CharismaModus 1000;
BA_REL_ "GenSigTimeoutTime" BU_SG_REL_ Getriebe_DQ_Hyb SG_ 912 GK1_CharismaModus 1000;
BA_REL_ "GenSigTimeoutTime" BU_SG_REL_ LH_EPS_APA SG_ 912 GK1_CharismaModus 1000;
BA_REL_ "GenSigTimeoutTime" BU_SG_REL_ LH_EPS_ZF_2G SG_ 912 GK1_CharismaModus 1000;
BA_REL_ "GenSigTimeoutTime" BU_SG_REL_ LH_EPS_ZF_3G SG_ 912 GK1_CharismaModus 1000;
BA_REL_ "GenSigTimeoutTime" BU_SG_REL_ Magne_Ride SG_ 912 GK1_CharismaModus 1000;
BA_REL_ "GenSigTimeoutTime" BU_SG_REL_ Motor_Diesel SG_ 912 GK1_CharismaModus 1000;
BA_REL_ "GenSigTimeoutTime" BU_SG_REL_ Motor_Otto SG_ 912 GK1_CharismaModus 1000;
BA_REL_ "GenSigTimeoutTime" BU_SG_REL_ Daempfer SG_ 912 GK1_SamFktNr 1000;
BA_REL_ "GenSigTimeoutTime" BU_SG_REL_ Getriebe_AG6 SG_ 912 GK1_SamFktNr 1000;
BA_REL_ "GenSigTimeoutTime" BU_SG_REL_ Getriebe_DQ SG_ 912 GK1_SamFktNr 1000;
BA_REL_ "GenSigTimeoutTime" BU_SG_REL_ Getriebe_DQ_Hyb SG_ 912 GK1_SamFktNr 1000;
BA_REL_ "GenSigTimeoutTime" BU_SG_REL_ LH_EPS_APA SG_ 912 GK1_SamFktNr 1000;
BA_REL_ "GenSigTimeoutTime" BU_SG_REL_ LH_EPS_ZF_2G SG_ 912 GK1_SamFktNr 1000;
BA_REL_ "GenSigTimeoutTime" BU_SG_REL_ LH_EPS_ZF_3G SG_ 912 GK1_SamFktNr 1000;
BA_REL_ "GenSigTimeoutTime" BU_SG_REL_ Magne_Ride SG_ 912 GK1_SamFktNr 1000;
BA_REL_ "GenSigTimeoutTime" BU_SG_REL_ Motor_Diesel SG_ 912 GK1_SamFktNr 1000;
BA_REL_ "GenSigTimeoutTime" BU_SG_REL_ Motor_Otto SG_ 912 GK1_SamFktNr 1000;
BA_REL_ "GenSigTimeoutTime" BU_SG_REL_ Bremse_MK60EC SG_ 912 GK1_Fa_Tuerkont 1000;
BA_REL_ "GenSigTimeoutTime" BU_SG_REL_ Bremse_MK70MABS SG_ 912 GK1_Fa_Tuerkont 1000;
BA_REL_ "GenSigTimeoutTime" BU_SG_REL_ Bremse_TRW_EBC450M SG_ 912 GK1_Fa_Tuerkont 1000;
BA_REL_ "GenSigTimeoutTime" BU_SG_REL_ Bremse_TRW_ESP SG_ 912 GK1_Fa_Tuerkont 1000;
BA_REL_ "GenSigTimeoutTime" BU_SG_REL_ EPB_TRW SG_ 912 GK1_Fa_Tuerkont 1000;
BA_REL_ "GenSigTimeoutTime" BU_SG_REL_ EPB_TRW_VW411CS SG_ 912 GK1_Fa_Tuerkont 1000;
BA_REL_ "GenSigTimeoutTime" BU_SG_REL_ Getriebe_DQ SG_ 912 GK1_Fa_Tuerkont 1000;
BA_REL_ "GenSigTimeoutTime" BU_SG_REL_ Getriebe_DQ_Hyb SG_ 912 GK1_Fa_Tuerkont 1000;
BA_REL_ "GenSigTimeoutTime" BU_SG_REL_ Motor_Diesel SG_ 912 GK1_Fa_Tuerkont 1000;
BA_REL_ "GenSigTimeoutTime" BU_SG_REL_ Motor_Diesel SG_ 912 GK1_Fa_Tuerkont 1000;
BA_REL_ "GenSigTimeoutTime" BU_SG_REL_ Motor_Hybrid SG_ 912 GK1_Fa_Tuerkont 1000;
BA_REL_ "GenSigTimeoutTime" BU_SG_REL_ Motor_Otto SG_ 912 GK1_Fa_Tuerkont 1000;
BA_REL_ "GenSigTimeoutTime" BU_SG_REL_ Motor_Otto SG_ 912 GK1_Fa_Tuerkont 1000;
BA_REL_ "GenSigTimeoutTime" BU_SG_REL_ Motor_Diesel SG_ 912 GK1_Sta_Stdhzg 1000;
BA_REL_ "GenSigTimeoutTime" BU_SG_REL_ Motor_Hybrid SG_ 912 GK1_Sta_Stdhzg 1000;
BA_REL_ "GenSigTimeoutTime" BU_SG_REL_ Motor_Otto SG_ 912 GK1_Sta_Stdhzg 1000;
BA_REL_ "GenSigTimeoutTime" BU_SG_REL_ Motor_Diesel SG_ 912 GK1_SH_Verbau 1000;
BA_REL_ "GenSigTimeoutTime" BU_SG_REL_ Motor_Hybrid SG_ 912 GK1_SH_Verbau 1000;
BA_REL_ "GenSigTimeoutTime" BU_SG_REL_ Motor_Otto SG_ 912 GK1_SH_Verbau 1000;
BA_REL_ "GenSigTimeoutTime" BU_SG_REL_ Motor_Diesel SG_ 912 GK1_KW_Warm 1000;
BA_REL_ "GenSigTimeoutTime" BU_SG_REL_ Motor_Hybrid SG_ 912 GK1_KW_Warm 1000;
BA_REL_ "GenSigTimeoutTime" BU_SG_REL_ Motor_Otto SG_ 912 GK1_KW_Warm 1000;
BA_REL_ "GenSigTimeoutTime" BU_SG_REL_ Motor_Diesel SG_ 912 BCM_Remotestart_Betrieb 1000;
BA_REL_ "GenSigTimeoutTime" BU_SG_REL_ Motor_Otto SG_ 912 BCM_Remotestart_Betrieb 1000;
BA_REL_ "GenSigTimeoutTime" BU_SG_REL_ Motor_Diesel SG_ 912 BCM_Offroad_Taster 1000;
BA_REL_ "GenSigTimeoutTime" BU_SG_REL_ Motor_Otto SG_ 912 BCM_Offroad_Taster 1000;
BA_REL_ "GenSigTimeoutTime" BU_SG_REL_ Motor_Diesel SG_ 912 BSK_HL_geoeffnet 1000;
BA_REL_ "GenSigTimeoutTime" BU_SG_REL_ Motor_Otto SG_ 912 BSK_HL_geoeffnet 1000;
BA_REL_ "GenSigTimeoutTime" BU_SG_REL_ PDC_PLA SG_ 912 BSK_HL_geoeffnet 1000;
BA_REL_ "GenSigTimeoutTime" BU_SG_REL_ Motor_Diesel SG_ 912 BSK_HR_geoeffnet 1000;
BA_REL_ "GenSigTimeoutTime" BU_SG_REL_ Motor_Otto SG_ 912 BSK_HR_geoeffnet 1000;
BA_REL_ "GenSigTimeoutTime" BU_SG_REL_ PDC_PLA SG_ 912 BSK_HR_geoeffnet 1000;
BA_REL_ "GenSigTimeoutTime" BU_SG_REL_ AFS SG_ 912 GK1_Rueckfahr 1000;
BA_REL_ "GenSigTimeoutTime" BU_SG_REL_ Bremse_MK60EC SG_ 912 GK1_Rueckfahr 1000;
BA_REL_ "GenSigTimeoutTime" BU_SG_REL_ Bremse_MK60EC SG_ 912 GK1_Rueckfahr 1000;
BA_REL_ "GenSigTimeoutTime" BU_SG_REL_ Bremse_MK60EC SG_ 912 GK1_Rueckfahr 1000;
BA_REL_ "GenSigTimeoutTime" BU_SG_REL_ Bremse_MK70MABS SG_ 912 GK1_Rueckfahr 1000;
BA_REL_ "GenSigTimeoutTime" BU_SG_REL_ Bremse_TRW_EBC450M SG_ 912 GK1_Rueckfahr 1000;
BA_REL_ "GenSigTimeoutTime" BU_SG_REL_ Bremse_TRW_EBC450M SG_ 912 GK1_Rueckfahr 1000;
BA_REL_ "GenSigTimeoutTime" BU_SG_REL_ Bremse_TRW_ESP SG_ 912 GK1_Rueckfahr 1000;
BA_REL_ "GenSigTimeoutTime" BU_SG_REL_ Bremse_TRW_ESP SG_ 912 GK1_Rueckfahr 1000;
BA_REL_ "GenSigTimeoutTime" BU_SG_REL_ Bremse_TRW_ESP SG_ 912 GK1_Rueckfahr 1000;
BA_REL_ "GenSigTimeoutTime" BU_SG_REL_ EPB_TRW SG_ 912 GK1_Rueckfahr 1000;
BA_REL_ "GenSigTimeoutTime" BU_SG_REL_ EPB_TRW_VW411CS SG_ 912 GK1_Rueckfahr 1000;
BA_REL_ "GenSigTimeoutTime" BU_SG_REL_ FLA SG_ 912 GK1_Rueckfahr 1000;
BA_REL_ "GenSigTimeoutTime" BU_SG_REL_ LH_EPS_APA SG_ 912 GK1_Rueckfahr 1000;
BA_REL_ "GenSigTimeoutTime" BU_SG_REL_ LH_EPS_ZF_2G SG_ 912 GK1_Rueckfahr 1000;
BA_REL_ "GenSigTimeoutTime" BU_SG_REL_ LH_EPS_ZF_3G SG_ 912 GK1_Rueckfahr 1000;
BA_REL_ "GenSigTimeoutTime" BU_SG_REL_ Motor_Diesel SG_ 912 GK1_Rueckfahr 1000;
BA_REL_ "GenSigTimeoutTime" BU_SG_REL_ Motor_Otto SG_ 912 GK1_Rueckfahr 1000;
BA_REL_ "GenSigTimeoutTime" BU_SG_REL_ PDC_PLA SG_ 912 GK1_Rueckfahr 1000;
BA_REL_ "GenSigTimeoutTime" BU_SG_REL_ PDC_PLA SG_ 912 GK1_Rueckfahr 1000;
BA_REL_ "GenSigTimeoutTime" BU_SG_REL_ AFS SG_ 912 GK1_Blinker_li 1000;
BA_REL_ "GenSigTimeoutTime" BU_SG_REL_ LWR SG_ 912 GK1_Blinker_li 1000;
BA_REL_ "GenSigTimeoutTime" BU_SG_REL_ Motor_Diesel SG_ 912 GK1_Blinker_li 1000;
BA_REL_ "GenSigTimeoutTime" BU_SG_REL_ Motor_Otto SG_ 912 GK1_Blinker_li 1000;
BA_REL_ "GenSigTimeoutTime" BU_SG_REL_ PDC_PLA SG_ 912 GK1_Blinker_li 1000;
BA_REL_ "GenSigTimeoutTime" BU_SG_REL_ AFS SG_ 912 GK1_Blinker_re 1000;
BA_REL_ "GenSigTimeoutTime" BU_SG_REL_ LWR SG_ 912 GK1_Blinker_re 1000;
BA_REL_ "GenSigTimeoutTime" BU_SG_REL_ Motor_Diesel SG_ 912 GK1_Blinker_re 1000;
BA_REL_ "GenSigTimeoutTime" BU_SG_REL_ Motor_Otto SG_ 912 GK1_Blinker_re 1000;
BA_REL_ "GenSigTimeoutTime" BU_SG_REL_ PDC_PLA SG_ 912 GK1_Blinker_re 1000;
BA_REL_ "GenSigTimeoutTime" BU_SG_REL_ Getriebe_AG6 SG_ 912 GK1_def_P_verr 1000;
BA_REL_ "GenSigTimeoutTime" BU_SG_REL_ FLA SG_ 912 GK1_LS1_Fernlicht 1000;
BA_REL_ "GenSigTimeoutTime" BU_SG_REL_ AFS SG_ 912 GK1_Sta_Licht2 1000;
BA_REL_ "GenSigTimeoutTime" BU_SG_REL_ AFS SG_ 912 GK1_Sta_LSM 1000;
BA_REL_ "GenSigTimeoutTime" BU_SG_REL_ FLA SG_ 912 GK1_Sta_LSM 1000;
BA_REL_ "GenSigTimeoutTime" BU_SG_REL_ Getriebe_AG6 SG_ 912 GK1_Sta_LSM 1000;
BA_REL_ "GenSigTimeoutTime" BU_SG_REL_ Motor_Diesel SG_ 912 GK1_Sta_LSM 1000;
BA_REL_ "GenSigTimeoutTime" BU_SG_REL_ Motor_Otto SG_ 912 GK1_Sta_LSM 1000;
BA_REL_ "GenSigTimeoutTime" BU_SG_REL_ PDC_PLA SG_ 912 GK1_Sta_LSM 1000;
BA_REL_ "GenSigTimeoutTime" BU_SG_REL_ Motor_Diesel SG_ 912 BSK_BT_geoeffnet 1000;
BA_REL_ "GenSigTimeoutTime" BU_SG_REL_ Motor_Otto SG_ 912 BSK_BT_geoeffnet 1000;
BA_REL_ "GenSigTimeoutTime" BU_SG_REL_ Motor_Diesel SG_ 912 BSK_HD_Hauptraste 1000;
BA_REL_ "GenSigTimeoutTime" BU_SG_REL_ Motor_Otto SG_ 912 BSK_HD_Hauptraste 1000;
BA_REL_ "GenSigTimeoutTime" BU_SG_REL_ Bremse_MK60EC SG_ 912 GK1_Anhaenger 1000;
BA_REL_ "GenSigTimeoutTime" BU_SG_REL_ Bremse_MK60EC SG_ 912 GK1_Anhaenger 1000;
BA_REL_ "GenSigTimeoutTime" BU_SG_REL_ Bremse_TRW_EBC450M SG_ 912 GK1_Anhaenger 1000;
BA_REL_ "GenSigTimeoutTime" BU_SG_REL_ Bremse_TRW_EBC450M SG_ 912 GK1_Anhaenger 1000;
BA_REL_ "GenSigTimeoutTime" BU_SG_REL_ Bremse_TRW_ESP SG_ 912 GK1_Anhaenger 1000;
BA_REL_ "GenSigTimeoutTime" BU_SG_REL_ Bremse_TRW_ESP SG_ 912 GK1_Anhaenger 1000;
BA_REL_ "GenSigTimeoutTime" BU_SG_REL_ Getriebe_DQ SG_ 912 GK1_Anhaenger 1000;
BA_REL_ "GenSigTimeoutTime" BU_SG_REL_ Getriebe_DQ_Hyb SG_ 912 GK1_Anhaenger 1000;
BA_REL_ "GenSigTimeoutTime" BU_SG_REL_ HCA SG_ 912 GK1_Anhaenger 1000;
BA_REL_ "GenSigTimeoutTime" BU_SG_REL_ Motor_Diesel SG_ 912 GK1_Anhaenger 1000;
BA_REL_ "GenSigTimeoutTime" BU_SG_REL_ Motor_Otto SG_ 912 GK1_Anhaenger 1000;
BA_REL_ "GenSigTimeoutTime" BU_SG_REL_ PDC_PLA SG_ 912 GK1_Anhaenger 1000;
BA_REL_ "GenSigTimeoutTime" BU_SG_REL_ RKA_Plus SG_ 912 GK1_Anhaenger 1000;
BA_REL_ "GenSigTimeoutTime" BU_SG_REL_ AFS SG_ 912 GK1_Abblendlicht 1000;
BA_REL_ "GenSigTimeoutTime" BU_SG_REL_ FLA SG_ 912 GK1_Abblendlicht 1000;
BA_REL_ "GenSigTimeoutTime" BU_SG_REL_ LWR SG_ 912 GK1_Abblendlicht 1000;
BA_REL_ "GenSigTimeoutTime" BU_SG_REL_ AFS SG_ 912 GK1_Fernlicht 1000;
BA_REL_ "GenSigTimeoutTime" BU_SG_REL_ FLA SG_ 912 GK1_Fernlicht 1000;
BA_REL_ "GenSigTimeoutTime" BU_SG_REL_ LWR SG_ 912 GK1_Fernlicht 1000;
BA_REL_ "GenSigTimeoutTime" BU_SG_REL_ AFS SG_ 912 GK1_Wischer_vorn 1000;
BA_REL_ "GenSigTimeoutTime" BU_SG_REL_ Bremse_MK60EC SG_ 912 GK1_Wischer_vorn 1000;
BA_REL_ "GenSigTimeoutTime" BU_SG_REL_ Bremse_MK70MABS SG_ 912 GK1_Wischer_vorn 1000;
BA_REL_ "GenSigTimeoutTime" BU_SG_REL_ Bremse_TRW_EBC450M SG_ 912 GK1_Wischer_vorn 1000;
BA_REL_ "GenSigTimeoutTime" BU_SG_REL_ Bremse_TRW_ESP SG_ 912 GK1_Wischer_vorn 1000;
BA_REL_ "GenSigTimeoutTime" BU_SG_REL_ HCA SG_ 912 GK1_Wischer_vorn 1000;
BA_REL_ "GenSigTimeoutTime" BU_SG_REL_ Motor_Diesel SG_ 912 GK1_Wischer_vorn 1000;
BA_REL_ "GenSigTimeoutTime" BU_SG_REL_ AFS SG_ 912 GK1_Sta_ILM_F_1 1000;
BA_REL_ "GenSigTimeoutTime" BU_SG_REL_ Bremse_MK60EC SG_ 912 GK1_Sta_ILM_F_1 1000;
BA_REL_ "GenSigTimeoutTime" BU_SG_REL_ Bremse_MK70MABS SG_ 912 GK1_Sta_ILM_F_1 1000;
BA_REL_ "GenSigTimeoutTime" BU_SG_REL_ Bremse_TRW_EBC450M SG_ 912 GK1_Sta_ILM_F_1 1000;
BA_REL_ "GenSigTimeoutTime" BU_SG_REL_ Bremse_TRW_ESP SG_ 912 GK1_Sta_ILM_F_1 1000;
BA_REL_ "GenSigTimeoutTime" BU_SG_REL_ HCA SG_ 912 GK1_Sta_ILM_F_1 1000;
BA_REL_ "GenSigTimeoutTime" BU_SG_REL_ AFS SG_ 912 GK1_Abbl_VL_def 1000;
BA_REL_ "GenSigTimeoutTime" BU_SG_REL_ AFS SG_ 912 GK1_Abbl_VR_def 1000;
BA_REL_ "GenSigTimeoutTime" BU_SG_REL_ Bremse_TRW_EBC450M SG_ 912 GK1_Warnblk_Status 1000;
BA_REL_ "GenSigTimeoutTime" BU_SG_REL_ Bremse_TRW_ESP SG_ 912 GK1_Warnblk_Status 1000;
BA_REL_ "GenSigTimeoutTime" BU_SG_REL_ AFS SG_ 912 GK1_Nebel_ein 1000;
BA_REL_ "GenSigTimeoutTime" BU_SG_REL_ FLA SG_ 912 GK1_Nebel_ein 1000;
BA_REL_ "GenSigTimeoutTime" BU_SG_REL_ AFS SG_ 914 GK2_Sta_Lichtsensor 1000;
BA_REL_ "GenSigTimeoutTime" BU_SG_REL_ AFS SG_ 914 GK2_Sta_Licht1 1000;
BA_REL_ "GenSigTimeoutTime" BU_SG_REL_ HCA SG_ 914 GK2_Sta_Licht1 1000;
BA_REL_ "GenSigTimeoutTime" BU_SG_REL_ Airbag SG_ 914 GK2_Sta_VSG 1000;
BA_REL_ "GenSigTimeoutTime" BU_SG_REL_ Motor_Otto SG_ 914 GK2_Sta_VSG 1000;
BA_REL_ "GenSigTimeoutTime" BU_SG_REL_ PDC_PLA SG_ 914 GK2_Sta_VSG 1000;
BA_REL_ "GenSigTimeoutTime" BU_SG_REL_ Daempfer SG_ 914 GK2_Sta_Schluessel 1000;
BA_REL_ "GenSigTimeoutTime" BU_SG_REL_ PDC_PLA SG_ 914 GK2_Sta_Profil 1000;
BA_REL_ "GenSigTimeoutTime" BU_SG_REL_ Motor_Diesel SG_ 914 GK2_Sta_Clima2 1000;
BA_REL_ "GenSigTimeoutTime" BU_SG_REL_ Motor_Diesel SG_ 914 GK2_Sta_Clima2 1000;
BA_REL_ "GenSigTimeoutTime" BU_SG_REL_ Motor_Otto SG_ 914 GK2_Sta_Clima2 1000;
BA_REL_ "GenSigTimeoutTime" BU_SG_REL_ Motor_Diesel SG_ 914 GK2_Sta_BSG4 1000;
BA_REL_ "GenSigTimeoutTime" BU_SG_REL_ Motor_Diesel SG_ 914 GK2_Sta_BSG4 1000;
BA_REL_ "GenSigTimeoutTime" BU_SG_REL_ Motor_Otto SG_ 914 GK2_Sta_BSG4 1000;
BA_REL_ "GenSigTimeoutTime" BU_SG_REL_ Motor_Diesel SG_ 914 GK2_Sta_Kessy_4 1000;
BA_REL_ "GenSigTimeoutTime" BU_SG_REL_ Motor_Diesel SG_ 914 GK2_Sta_Kessy_4 1000;
BA_REL_ "GenSigTimeoutTime" BU_SG_REL_ Motor_Otto SG_ 914 GK2_Sta_Kessy_4 1000;
BA_REL_ "GenSigTimeoutTime" BU_SG_REL_ HCA SG_ 914 GK2_Blk_L_Kontrolle 1000;
BA_REL_ "GenSigTimeoutTime" BU_SG_REL_ HCA SG_ 914 GK2_Blk_R_Kontrolle 1000;
BA_REL_ "GenSigTimeoutTime" BU_SG_REL_ AFS SG_ 914 GK2_LS_KomFehler 1000;
BA_REL_ "GenSigTimeoutTime" BU_SG_REL_ AFS SG_ 914 GK2_LS_def 1000;
BA_REL_ "GenSigTimeoutTime" BU_SG_REL_ AFS SG_ 914 GK2_Helligkeit 1000;
BA_REL_ "GenSigTimeoutTime" BU_SG_REL_ PDC_PLA SG_ 914 GK2_VD_zu_ver 1000;
BA_REL_ "GenSigTimeoutTime" BU_SG_REL_ PDC_PLA SG_ 914 GK2_VD_entriegelt 1000;
BA_REL_ "GenSigTimeoutTime" BU_SG_REL_ Airbag SG_ 914 GK2_VD_offen_ver 1000;
BA_REL_ "GenSigTimeoutTime" BU_SG_REL_ Motor_Otto SG_ 914 GK2_VD_offen_ver 1000;
BA_REL_ "GenSigTimeoutTime" BU_SG_REL_ PDC_PLA SG_ 914 GK2_VD_offen_ver 1000;
BA_REL_ "GenSigTimeoutTime" BU_SG_REL_ PDC_PLA SG_ 914 GK2_Verdeck_Anf 1000;
BA_REL_ "GenSigTimeoutTime" BU_SG_REL_ PDC_PLA SG_ 914 GK2_VDKD_auf 1000;
BA_REL_ "GenSigTimeoutTime" BU_SG_REL_ PDC_PLA SG_ 914 GK2_Hardtop 1000;
BA_REL_ "GenSigTimeoutTime" BU_SG_REL_ AFS SG_ 914 GK2_AFL_Schalter 1000;
BA_REL_ "GenSigTimeoutTime" BU_SG_REL_ AFS SG_ 914 GK2_Nebelschluss 1000;
BA_REL_ "GenSigTimeoutTime" BU_SG_REL_ Motor_Diesel SG_ 914 GK2_EM_LIN_ungueltig 1000;
BA_REL_ "GenSigTimeoutTime" BU_SG_REL_ Motor_Otto SG_ 914 GK2_EM_LIN_ungueltig 1000;
BA_REL_ "GenSigTimeoutTime" BU_SG_REL_ PDC_PLA SG_ 914 GK2_Profil 1000;
BA_REL_ "GenSigTimeoutTime" BU_SG_REL_ Motor_Diesel SG_ 914 GK2_Kl_StSt_Info 1000;
BA_REL_ "GenSigTimeoutTime" BU_SG_REL_ Motor_Diesel SG_ 914 GK2_Kl_StSt_Info 1000;
BA_REL_ "GenSigTimeoutTime" BU_SG_REL_ Motor_Otto SG_ 914 GK2_Kl_StSt_Info 1000;
BA_REL_ "GenSigTimeoutTime" BU_SG_REL_ Motor_Diesel SG_ 914 GK2_BSG_StSt_Info 1000;
BA_REL_ "GenSigTimeoutTime" BU_SG_REL_ Motor_Diesel SG_ 914 GK2_BSG_StSt_Info 1000;
BA_REL_ "GenSigTimeoutTime" BU_SG_REL_ Motor_Otto SG_ 914 GK2_BSG_StSt_Info 1000;
BA_REL_ "GenSigTimeoutTime" BU_SG_REL_ Motor_Diesel SG_ 914 GK2_BEM_P_Generator 1000;
BA_REL_ "GenSigTimeoutTime" BU_SG_REL_ Motor_Otto SG_ 914 GK2_BEM_P_Generator 1000;
BA_REL_ "GenSigTimeoutTime" BU_SG_REL_ Motor_Diesel SG_ 914 GK2_BEM_DFM 1000;
BA_REL_ "GenSigTimeoutTime" BU_SG_REL_ Motor_Otto SG_ 914 GK2_BEM_DFM 1000;
BA_REL_ "GenSigTimeoutTime" BU_SG_REL_ Motor_Diesel SG_ 914 GK2_Kessy_StSt_Info 1000;
BA_REL_ "GenSigTimeoutTime" BU_SG_REL_ Motor_Diesel SG_ 914 GK2_Kessy_StSt_Info 1000;
BA_REL_ "GenSigTimeoutTime" BU_SG_REL_ Motor_Otto SG_ 914 GK2_Kessy_StSt_Info 1000;
BA_REL_ "GenSigTimeoutTime" BU_SG_REL_ Motor_Diesel SG_ 914 GK2_BEM_StSt_Info 1000;
BA_REL_ "GenSigTimeoutTime" BU_SG_REL_ Motor_Diesel SG_ 914 GK2_BEM_StSt_Info 1000;
BA_REL_ "GenSigTimeoutTime" BU_SG_REL_ Motor_Otto SG_ 914 GK2_BEM_StSt_Info 1000;
BA_REL_ "GenSigTimeoutTime" BU_SG_REL_ Getriebe_DQ SG_ 914 BEM_Segel_Info 1000;
BA_REL_ "GenSigTimeoutTime" BU_SG_REL_ Getriebe_DQ_Hyb SG_ 914 BEM_Segel_Info 1000;
BA_REL_ "GenSigTimeoutTime" BU_SG_REL_ Motor_Diesel SG_ 914 BEM_Segel_Info 1000;
BA_REL_ "GenSigTimeoutTime" BU_SG_REL_ Motor_Otto SG_ 914 BEM_Segel_Info 1000;
BA_REL_ "GenSigTimeoutTime" BU_SG_REL_ PDC_PLA SG_ 915 GK3_Sta_HD_1 2000;
BA_REL_ "GenSigTimeoutTime" BU_SG_REL_ PDC_PLA SG_ 915 HD1_Position 2000;
BA_REL_ "GenSigTimeoutTime" BU_SG_REL_ Ladegeraet_EGolf SG_ 921 GK4_Ladesteckerentr_Anf 2000;
BA_REL_ "GenSigTimeoutTime" BU_SG_REL_ Magne_Ride SG_ 684 GS1_Zaehler 500;
BA_REL_ "GenSigTimeoutTime" BU_SG_REL_ Magne_Ride SG_ 684 GS1_QBit_Rad_kmh 500;
BA_REL_ "GenSigTimeoutTime" BU_SG_REL_ Magne_Ride SG_ 684 GS1_Rad_kmh 500;
BA_REL_ "GenSigTimeoutTime" BU_SG_REL_ Magne_Ride SG_ 684 GS1_Checksumme 500;
BA_REL_ "GenSigTimeoutTime" BU_SG_REL_ Bremse_MK60EC SG_ 1088 GE1_Schaltung 500;
BA_REL_ "GenSigTimeoutTime" BU_SG_REL_ Bremse_MK60EC SG_ 1088 GE1_Schaltung 500;
BA_REL_ "GenSigTimeoutTime" BU_SG_REL_ Bremse_MK70MABS SG_ 1088 GE1_Schaltung 500;
BA_REL_ "GenSigTimeoutTime" BU_SG_REL_ Bremse_TRW_EBC450M SG_ 1088 GE1_Schaltung 500;
BA_REL_ "GenSigTimeoutTime" BU_SG_REL_ Bremse_TRW_EBC450M SG_ 1088 GE1_Schaltung 500;
BA_REL_ "GenSigTimeoutTime" BU_SG_REL_ Bremse_TRW_ESP SG_ 1088 GE1_Schaltung 500;
BA_REL_ "GenSigTimeoutTime" BU_SG_REL_ Bremse_TRW_ESP SG_ 1088 GE1_Schaltung 500;
BA_REL_ "GenSigTimeoutTime" BU_SG_REL_ Motor_Diesel SG_ 1088 GE1_Schaltung 500;
BA_REL_ "GenSigTimeoutTime" BU_SG_REL_ Motor_Hybrid SG_ 1088 GE1_Schaltung 500;
BA_REL_ "GenSigTimeoutTime" BU_SG_REL_ Motor_Otto SG_ 1088 GE1_Schaltung 500;
BA_REL_ "GenSigTimeoutTime" BU_SG_REL_ RKA_Plus SG_ 1088 GE1_Schaltung 500;
BA_REL_ "GenSigTimeoutTime" BU_SG_REL_ Motor_Diesel SG_ 1088 GE1_Sta_Schutz 500;
BA_REL_ "GenSigTimeoutTime" BU_SG_REL_ Motor_Hybrid SG_ 1088 GE1_Sta_Schutz 500;
BA_REL_ "GenSigTimeoutTime" BU_SG_REL_ Motor_Otto SG_ 1088 GE1_Sta_Schutz 500;
BA_REL_ "GenSigTimeoutTime" BU_SG_REL_ Motor_Diesel SG_ 1088 GE1_Klimakompr 500;
BA_REL_ "GenSigTimeoutTime" BU_SG_REL_ Motor_Hybrid SG_ 1088 GE1_Klimakompr 500;
BA_REL_ "GenSigTimeoutTime" BU_SG_REL_ Motor_Otto SG_ 1088 GE1_Klimakompr 500;
BA_REL_ "GenSigTimeoutTime" BU_SG_REL_ Allrad SG_ 1088 GE1_WK 500;
BA_REL_ "GenSigTimeoutTime" BU_SG_REL_ Motor_Diesel SG_ 1088 GE1_WK 500;
BA_REL_ "GenSigTimeoutTime" BU_SG_REL_ Motor_Hybrid SG_ 1088 GE1_WK 500;
BA_REL_ "GenSigTimeoutTime" BU_SG_REL_ Motor_Otto SG_ 1088 GE1_WK 500;
BA_REL_ "GenSigTimeoutTime" BU_SG_REL_ RKA_Plus SG_ 1088 GE1_WK 500;
BA_REL_ "GenSigTimeoutTime" BU_SG_REL_ Motor_Diesel SG_ 1088 GE1_StSt_Info 500;
BA_REL_ "GenSigTimeoutTime" BU_SG_REL_ Motor_Diesel SG_ 1088 GE1_StSt_Info 500;
BA_REL_ "GenSigTimeoutTime" BU_SG_REL_ Motor_Otto SG_ 1088 GE1_StSt_Info 500;
BA_REL_ "GenSigTimeoutTime" BU_SG_REL_ Motor_Diesel SG_ 1088 GE1_EGS_Anf 500;
BA_REL_ "GenSigTimeoutTime" BU_SG_REL_ Motor_Hybrid SG_ 1088 GE1_EGS_Anf 500;
BA_REL_ "GenSigTimeoutTime" BU_SG_REL_ Motor_Otto SG_ 1088 GE1_EGS_Anf 500;
BA_REL_ "GenSigTimeoutTime" BU_SG_REL_ Allrad SG_ 1088 GE1_Zielgang 500;
BA_REL_ "GenSigTimeoutTime" BU_SG_REL_ Bremse_MK60EC SG_ 1088 GE1_Zielgang 500;
BA_REL_ "GenSigTimeoutTime" BU_SG_REL_ Bremse_MK70MABS SG_ 1088 GE1_Zielgang 500;
BA_REL_ "GenSigTimeoutTime" BU_SG_REL_ Bremse_TRW_EBC450M SG_ 1088 GE1_Zielgang 500;
BA_REL_ "GenSigTimeoutTime" BU_SG_REL_ Bremse_TRW_ESP SG_ 1088 GE1_Zielgang 500;
BA_REL_ "GenSigTimeoutTime" BU_SG_REL_ Motor_Diesel SG_ 1088 GE1_Zielgang 500;
BA_REL_ "GenSigTimeoutTime" BU_SG_REL_ Motor_Hybrid SG_ 1088 GE1_Zielgang 500;
BA_REL_ "GenSigTimeoutTime" BU_SG_REL_ Motor_Otto SG_ 1088 GE1_Zielgang 500;
BA_REL_ "GenSigTimeoutTime" BU_SG_REL_ RKA_Plus SG_ 1088 GE1_Zielgang 500;
BA_REL_ "GenSigTimeoutTime" BU_SG_REL_ BMS_Hybrid SG_ 1088 GE1_Wahl_Pos 500;
BA_REL_ "GenSigTimeoutTime" BU_SG_REL_ Bremse_MK60EC SG_ 1088 GE1_Wahl_Pos 500;
BA_REL_ "GenSigTimeoutTime" BU_SG_REL_ Bremse_MK70MABS SG_ 1088 GE1_Wahl_Pos 500;
BA_REL_ "GenSigTimeoutTime" BU_SG_REL_ Bremse_TRW_EBC450M SG_ 1088 GE1_Wahl_Pos 500;
BA_REL_ "GenSigTimeoutTime" BU_SG_REL_ Bremse_TRW_ESP SG_ 1088 GE1_Wahl_Pos 500;
BA_REL_ "GenSigTimeoutTime" BU_SG_REL_ EPB_TRW SG_ 1088 GE1_Wahl_Pos 500;
BA_REL_ "GenSigTimeoutTime" BU_SG_REL_ EPB_TRW_VW411CS SG_ 1088 GE1_Wahl_Pos 500;
BA_REL_ "GenSigTimeoutTime" BU_SG_REL_ Motor_Diesel SG_ 1088 GE1_Wahl_Pos 500;
BA_REL_ "GenSigTimeoutTime" BU_SG_REL_ Motor_Hybrid SG_ 1088 GE1_Wahl_Pos 500;
BA_REL_ "GenSigTimeoutTime" BU_SG_REL_ Motor_Otto SG_ 1088 GE1_Wahl_Pos 500;
BA_REL_ "GenSigTimeoutTime" BU_SG_REL_ PDC_PLA SG_ 1088 GE1_Wahl_Pos 500;
BA_REL_ "GenSigTimeoutTime" BU_SG_REL_ RKA_Plus SG_ 1088 GE1_Wahl_Pos 500;
BA_REL_ "GenSigTimeoutTime" BU_SG_REL_ Bremse_MK60EC SG_ 1088 GE1_Mrad_Mkurb 500;
BA_REL_ "GenSigTimeoutTime" BU_SG_REL_ Bremse_MK70MABS SG_ 1088 GE1_Mrad_Mkurb 500;
BA_REL_ "GenSigTimeoutTime" BU_SG_REL_ Bremse_TRW_EBC450M SG_ 1088 GE1_Mrad_Mkurb 500;
BA_REL_ "GenSigTimeoutTime" BU_SG_REL_ Bremse_TRW_ESP SG_ 1088 GE1_Mrad_Mkurb 500;
BA_REL_ "GenSigTimeoutTime" BU_SG_REL_ EPB_TRW SG_ 1088 GE1_Mrad_Mkurb 500;
BA_REL_ "GenSigTimeoutTime" BU_SG_REL_ EPB_TRW_VW411CS SG_ 1088 GE1_Mrad_Mkurb 500;
BA_REL_ "GenSigTimeoutTime" BU_SG_REL_ Motor_Diesel SG_ 1088 GE1_Mrad_Mkurb 500;
BA_REL_ "GenSigTimeoutTime" BU_SG_REL_ Motor_Hybrid SG_ 1088 GE1_Mrad_Mkurb 500;
BA_REL_ "GenSigTimeoutTime" BU_SG_REL_ Motor_Otto SG_ 1088 GE1_Mrad_Mkurb 500;
BA_REL_ "GenSigTimeoutTime" BU_SG_REL_ Motor_Diesel SG_ 1088 GE1_Soll_Mo 500;
BA_REL_ "GenSigTimeoutTime" BU_SG_REL_ Motor_Hybrid SG_ 1088 GE1_Soll_Mo 500;
BA_REL_ "GenSigTimeoutTime" BU_SG_REL_ Motor_Otto SG_ 1088 GE1_Soll_Mo 500;
BA_REL_ "GenSigTimeoutTime" BU_SG_REL_ Motor_Diesel SG_ 1088 GE1_Fahrwistd 500;
BA_REL_ "GenSigTimeoutTime" BU_SG_REL_ Motor_Hybrid SG_ 1088 GE1_Fahrwistd 500;
BA_REL_ "GenSigTimeoutTime" BU_SG_REL_ Motor_Otto SG_ 1088 GE1_Fahrwistd 500;
BA_REL_ "GenSigTimeoutTime" BU_SG_REL_ Bremse_TRW_EBC450M SG_ 1088 GE1_Notlauf 500;
BA_REL_ "GenSigTimeoutTime" BU_SG_REL_ Bremse_TRW_ESP SG_ 1088 GE1_Notlauf 500;
BA_REL_ "GenSigTimeoutTime" BU_SG_REL_ Motor_Diesel SG_ 1088 GE1_Notlauf 500;
BA_REL_ "GenSigTimeoutTime" BU_SG_REL_ Motor_Hybrid SG_ 1088 GE1_Notlauf 500;
BA_REL_ "GenSigTimeoutTime" BU_SG_REL_ Motor_Otto SG_ 1088 GE1_Notlauf 500;
BA_REL_ "GenSigTimeoutTime" BU_SG_REL_ Motor_Diesel SG_ 1088 GE1_Kuehlung 500;
BA_REL_ "GenSigTimeoutTime" BU_SG_REL_ Motor_Hybrid SG_ 1088 GE1_Kuehlung 500;
BA_REL_ "GenSigTimeoutTime" BU_SG_REL_ Motor_Otto SG_ 1088 GE1_Kuehlung 500;
BA_REL_ "GenSigTimeoutTime" BU_SG_REL_ Motor_Diesel SG_ 1088 GE1_Sta_OBD 500;
BA_REL_ "GenSigTimeoutTime" BU_SG_REL_ Motor_Hybrid SG_ 1088 GE1_Sta_OBD 500;
BA_REL_ "GenSigTimeoutTime" BU_SG_REL_ Motor_Otto SG_ 1088 GE1_Sta_OBD 500;
BA_REL_ "GenSigTimeoutTime" BU_SG_REL_ Bremse_MK60EC SG_ 1088 GE1_LaunchControl 500;
BA_REL_ "GenSigTimeoutTime" BU_SG_REL_ Bremse_MK70MABS SG_ 1088 GE1_LaunchControl 500;
BA_REL_ "GenSigTimeoutTime" BU_SG_REL_ Motor_Diesel SG_ 1088 GE1_LaunchControl 500;
BA_REL_ "GenSigTimeoutTime" BU_SG_REL_ Motor_Hybrid SG_ 1088 GE1_LaunchControl 500;
BA_REL_ "GenSigTimeoutTime" BU_SG_REL_ Motor_Otto SG_ 1088 GE1_LaunchControl 500;
BA_REL_ "GenSigTimeoutTime" BU_SG_REL_ Gateway_PQ35 SG_ 1088 GE1_SleepInd 500;
BA_REL_ "GenSigTimeoutTime" BU_SG_REL_ Bremse_MK60EC SG_ 1088 GE1_Zaehler 500;
BA_REL_ "GenSigTimeoutTime" BU_SG_REL_ Bremse_TRW_EBC450M SG_ 1088 GE1_Zaehler 500;
BA_REL_ "GenSigTimeoutTime" BU_SG_REL_ Bremse_TRW_ESP SG_ 1088 GE1_Zaehler 500;
BA_REL_ "GenSigTimeoutTime" BU_SG_REL_ EPB_TRW SG_ 1088 GE1_Zaehler 500;
BA_REL_ "GenSigTimeoutTime" BU_SG_REL_ EPB_TRW_VW411CS SG_ 1088 GE1_Zaehler 500;
BA_REL_ "GenSigTimeoutTime" BU_SG_REL_ Motor_Diesel SG_ 1088 GE1_Zaehler 500;
BA_REL_ "GenSigTimeoutTime" BU_SG_REL_ Motor_Hybrid SG_ 1088 GE1_Zaehler 500;
BA_REL_ "GenSigTimeoutTime" BU_SG_REL_ Motor_Otto SG_ 1088 GE1_Zaehler 500;
BA_REL_ "GenSigTimeoutTime" BU_SG_REL_ Gateway_PQ35 SG_ 1088 GE1_Fehlereintr 500;
BA_REL_ "GenSigTimeoutTime" BU_SG_REL_ Motor_Diesel SG_ 1088 GE1_WaVerl_Mo 500;
BA_REL_ "GenSigTimeoutTime" BU_SG_REL_ Motor_Hybrid SG_ 1088 GE1_WaVerl_Mo 500;
BA_REL_ "GenSigTimeoutTime" BU_SG_REL_ Motor_Otto SG_ 1088 GE1_WaVerl_Mo 500;
BA_REL_ "GenSigTimeoutTime" BU_SG_REL_ Motor_Diesel SG_ 1344 GE2_LFR_Adap 500;
BA_REL_ "GenSigTimeoutTime" BU_SG_REL_ Motor_Hybrid SG_ 1344 GE2_LFR_Adap 500;
BA_REL_ "GenSigTimeoutTime" BU_SG_REL_ Motor_Otto SG_ 1344 GE2_LFR_Adap 500;
BA_REL_ "GenSigTimeoutTime" BU_SG_REL_ Motor_Otto SG_ 1344 GE2_Sta_SAS 500;
BA_REL_ "GenSigTimeoutTime" BU_SG_REL_ Motor_Hybrid SG_ 1344 GE2_SlipStDZEingr 500;
BA_REL_ "GenSigTimeoutTime" BU_SG_REL_ Motor_Diesel SG_ 1344 GE2_Sta_ZwGas 500;
BA_REL_ "GenSigTimeoutTime" BU_SG_REL_ Motor_Hybrid SG_ 1344 GE2_Sta_ZwGas 500;
BA_REL_ "GenSigTimeoutTime" BU_SG_REL_ Motor_Otto SG_ 1344 GE2_Sta_ZwGas 500;
BA_REL_ "GenSigTimeoutTime" BU_SG_REL_ Motor_Diesel SG_ 1344 GE2_Zaehler 500;
BA_REL_ "GenSigTimeoutTime" BU_SG_REL_ Motor_Hybrid SG_ 1344 GE2_Zaehler 500;
BA_REL_ "GenSigTimeoutTime" BU_SG_REL_ Motor_Otto SG_ 1344 GE2_Zaehler 500;
BA_REL_ "GenSigTimeoutTime" BU_SG_REL_ Motor_Diesel SG_ 1344 GE2_LL_Solldz 500;
BA_REL_ "GenSigTimeoutTime" BU_SG_REL_ Motor_Hybrid SG_ 1344 GE2_LL_Solldz 500;
BA_REL_ "GenSigTimeoutTime" BU_SG_REL_ Motor_Otto SG_ 1344 GE2_LL_Solldz 500;
BA_REL_ "GenSigTimeoutTime" BU_SG_REL_ Motor_Diesel SG_ 1344 GE2_Grad_begr 500;
BA_REL_ "GenSigTimeoutTime" BU_SG_REL_ Motor_Hybrid SG_ 1344 GE2_Grad_begr 500;
BA_REL_ "GenSigTimeoutTime" BU_SG_REL_ Motor_Otto SG_ 1344 GE2_Grad_begr 500;
BA_REL_ "GenSigTimeoutTime" BU_SG_REL_ Motor_Diesel SG_ 1344 GE2_Sync_Dz 500;
BA_REL_ "GenSigTimeoutTime" BU_SG_REL_ Motor_Hybrid SG_ 1344 GE2_Sync_Dz 500;
BA_REL_ "GenSigTimeoutTime" BU_SG_REL_ Motor_Otto SG_ 1344 GE2_Sync_Dz 500;
BA_REL_ "GenSigTimeoutTime" BU_SG_REL_ Motor_Diesel SG_ 1344 GE2_invSync_Dz 500;
BA_REL_ "GenSigTimeoutTime" BU_SG_REL_ Motor_Hybrid SG_ 1344 GE2_invSync_Dz 500;
BA_REL_ "GenSigTimeoutTime" BU_SG_REL_ Motor_Otto SG_ 1344 GE2_invSync_Dz 500;
BA_REL_ "GenSigTimeoutTime" BU_SG_REL_ Motor_Diesel SG_ 1344 GE2_Sync_Zeit 500;
BA_REL_ "GenSigTimeoutTime" BU_SG_REL_ Motor_Hybrid SG_ 1344 GE2_Sync_Zeit 500;
BA_REL_ "GenSigTimeoutTime" BU_SG_REL_ Motor_Otto SG_ 1344 GE2_Sync_Zeit 500;
BA_REL_ "GenSigTimeoutTime" BU_SG_REL_ Motor_Diesel SG_ 1344 GE2_DZM_Daempf 500;
BA_REL_ "GenSigTimeoutTime" BU_SG_REL_ Motor_Otto SG_ 1344 GE2_DZM_Daempf 500;
BA_REL_ "GenSigTimeoutTime" BU_SG_REL_ Motor_Otto SG_ 1344 GE2_invMSB_Sync 500;
BA_REL_ "GenSigTimeoutTime" BU_SG_REL_ Allrad SG_ 1344 GE2_Senderkennung 500;
BA_REL_ "GenSigTimeoutTime" BU_SG_REL_ Gateway_PQ35 SG_ 1344 GE2_Senderkennung 500;
BA_REL_ "GenSigTimeoutTime" BU_SG_REL_ Motor_Otto SG_ 1344 GE2_MSB_Sync 500;
BA_REL_ "GenSigTimeoutTime" BU_SG_REL_ Motor_Diesel SG_ 1344 GE2_WBA_Blinken 500;
BA_REL_ "GenSigTimeoutTime" BU_SG_REL_ Motor_Hybrid SG_ 1344 GE2_WBA_Blinken 500;
BA_REL_ "GenSigTimeoutTime" BU_SG_REL_ Motor_Otto SG_ 1344 GE2_WBA_Blinken 500;
BA_REL_ "GenSigTimeoutTime" BU_SG_REL_ Allrad SG_ 1344 GE2_Variante 500;
BA_REL_ "GenSigTimeoutTime" BU_SG_REL_ Gateway_PQ35 SG_ 1344 GE2_Variante 500;
BA_REL_ "GenSigTimeoutTime" BU_SG_REL_ Gateway_PQ35 SG_ 1344 GE2_akt_Gang 500;
BA_REL_ "GenSigTimeoutTime" BU_SG_REL_ Motor_Otto SG_ 1090 GM3_Checksum 500;
BA_REL_ "GenSigTimeoutTime" BU_SG_REL_ Motor_Otto SG_ 1090 GM3_Zaehler 500;
BA_REL_ "GenSigTimeoutTime" BU_SG_REL_ Motor_Hybrid SG_ 1090 GM3_MomEingr 500;
BA_REL_ "GenSigTimeoutTime" BU_SG_REL_ Motor_Otto SG_ 1090 GM3_MomEingr 500;
BA_REL_ "GenSigTimeoutTime" BU_SG_REL_ Motor_Hybrid SG_ 1090 GM3_MoSoMom 500;
BA_REL_ "GenSigTimeoutTime" BU_SG_REL_ Motor_Otto SG_ 1090 GM3_MoSoMom 500;
BA_REL_ "GenSigTimeoutTime" BU_SG_REL_ Motor_Otto SG_ 1090 GM3_StaSoMom 500;
BA_REL_ "GenSigTimeoutTime" BU_SG_REL_ Motor_Otto SG_ 1090 GM3_MomID 500;
BA_REL_ "GenSigTimeoutTime" BU_SG_REL_ Motor_Otto SG_ 1090 GM3_Zeit 500;
BA_REL_ "GenSigTimeoutTime" BU_SG_REL_ Motor_Otto SG_ 1090 GM3_Moment 500;
BA_REL_ "GenSigTimeoutTime" BU_SG_REL_ Motor_Otto SG_ 1090 GM3_QB_LangEingr 500;
BA_REL_ "GenSigTimeoutTime" BU_SG_REL_ Motor_Otto SG_ 1090 GM3_LangEingr 500;
BA_REL_ "GenSigTimeoutTime" BU_SG_REL_ Waehlhebel SG_ 1352 GE4_Shiftlock 500;
BA_REL_ "GenSigTimeoutTime" BU_SG_REL_ Waehlhebel SG_ 1352 GE4_AuslModus 500;
BA_REL_ "GenSigTimeoutTime" BU_SG_REL_ Waehlhebel SG_ 1352 GE4_Test 500;
BA_REL_ "GenSigTimeoutTime" BU_SG_REL_ Waehlhebel SG_ 1352 GE4_Ausleuchtung 500;
BA_REL_ "GenSigTimeoutTime" BU_SG_REL_ Waehlhebel SG_ 1352 GE4_Testparam_1 500;
BA_REL_ "GenSigTimeoutTime" BU_SG_REL_ Waehlhebel SG_ 1352 GE4_Testparam_2 500;
VAL_ 1578 Pumpe_HT_Ist 11 "nicht_definiert" 12 "nicht_definiert" 13 "nicht_definiert" 14 "nicht_definiert" 15 "nicht_verbaut" ;
VAL_ 1578 Zustand_Pumpe_HT 0 "nicht_schaltbar" 1 "foerdert_nicht" 2 "foerdert" 3 "reserviert" ;
VAL_ 1578 Pumpe_NT_Ist 11 "nicht_definiert" 12 "nicht_definiert" 13 "nicht_definiert" 14 "nicht_definiert" 15 "nicht_verbaut" ;
VAL_ 1578 Zustand_Pumpe_NT 0 "nicht_schaltbar" 1 "foerdert_nicht" 2 "foerdert" 3 "reserviert" ;
VAL_ 1578 Ventil_HT_Kreis_Diagnose 0 "Funktion_im_MSG_nicht_verfuegbar" 1 "Ventil_arbeitet_fehlerfrei" 2 "Ventil_fehler" 3 "reserviert" ;
VAL_ 1578 Ventil_HT_Kreis_Pos 0 "Ventil_in_Position_1" 1 "Ventil_in_Position_2" ;
VAL_ 1578 Ventil_Bat_Diagnose 0 "Funktion_im_MSG_nicht_verfuegbar" 1 "Ventil_arbeitet_fehlerfrei" 2 "Ventil_fehler" 3 "reserviert" ;
VAL_ 1578 Ventil_Bat_Pos 0 "Ventil_in_Position_1" 1 "Ventil_in_Position_2" ;
VAL_ 1578 Ventil_vor_EM_Diagnose 0 "Funktion_im_MSG_nicht_verfuegbar" 1 "Ventil_arbeitet_fehlerfrei" 2 "Ventil_fehler" 3 "reserviert" ;
VAL_ 1578 Ventil_vor_EM_Pos 0 "Ventil_in_Position_1" 1 "Ventil_in_Position_2" ;
VAL_ 1578 Temp_vor_PTC 255 "Fehler" ;
VAL_ 1578 Temp_nach_WT 255 "Fehler" ;
VAL_ 1578 Temp_nach_Chiller 255 "Fehler" ;
VAL_ 1578 Temp_nach_LE 255 "Fehler" ;
VAL_ 1578 Temp_nach_EM 255 "Fehler" ;
VAL_ 1514 EFAS_Weckzeit_Set_Reset 0 "keine_Aktion" 1 "setzen" 2 "loeschen" 3 "reserviert" ;
VAL_ 1514 EFAS_Monat 0 "ungueltig" 13 "ungueltig" 14 "relatives_Datum" 15 "Spezialfall" ;
VAL_ 1514 EFAS_Stunde 24 "ungueltig" 25 "ungueltig" 26 "ungueltig" 27 "ungueltig" 28 "ungueltig" 29 "ungueltig" 30 "ungueltig" 31 "ungueltig" ;
VAL_ 1514 EFAS_Minute 60 "ungueltig" 61 "ungueltig" 62 "ungueltig" 63 "ungueltig" ;
VAL_ 1526 EK1_Comp_main_stat 0 "Comp_not_enabled" 1 "Comp_enabled" ;
VAL_ 1526 EK1_Comp_SCI_com_stat 0 "normal" 1 "CAN_error" 2 "Inverter_error" ;
VAL_ 1526 EK1_Comp_ovld_stat 0 "normal" 2 "current_restriction" 3 "sw_over_current" 4 "over_load" 6 "over_input_current" ;
VAL_ 1526 EK1_Comp_output_stat 0 "normal" 1 "output_line_short" 2 "output_line_cut_out" 3 "abnorm_curr_detection" ;
VAL_ 1526 EK1_Comp_photo_temp_stat 0 "normal" 1 "over_heat_L" 2 "over_heat_S" 3 "sermister_abnormal" ;
VAL_ 1526 EK1_Comp_Inv_stat 0 "normal" 1 "start_fail" 2 "temp_protection" 3 "system_abnormal_stop" ;
VAL_ 1526 EK1_KD_Fehler 0 "kein_Fehlerspeichereintrag" 1 "Fehlerspeichereintrag" ;
VAL_ 1526 EK1_Comp_current 255 "Init_not_avail" ;
VAL_ 1526 EK1_Comp_photo_temp 255 "Init_not_avail" ;
VAL_ 1406 EY1_KD_Fehler 0 "kein_Fehlerspeichereintrag" 1 "Fehlerspeichereintrag" ;
VAL_ 1472 EP1_Fehler_Sta 0 "volle_Funktion" 1 "linke_Seite_fehlerhaft" 2 "rechte_Seite_fehlerhaft" 3 "beide_Seiten_fehlerhaft" ;
VAL_ 1472 EP1_Sta_EPB 0 "Bremse_geoeffnet" 1 "Bremse_geschlossen" ;
VAL_ 1472 EP1_Sta_Schalter 0 "volle_Funktion" 1 "Schalter_ausser_Funktion" ;
VAL_ 1472 EP1_Spannkraft 31 "Fehler" ;
VAL_ 1472 EP1_Schalterinfo 0 "keine_Fahreranforderung" 1 "Fahreranforderung_oeffnen" 2 "Fahreranforderung_schliessen" 3 "Schalterfehler" ;
VAL_ 1472 EP1_Sta_NWS 0 "volle_Funktion" 1 "keine_Funktion" ;
VAL_ 1472 EP1_Fehlereintr 0 "kein_Fehlerspeichereintrag" 1 "Fehlerspeichereintrag" ;
VAL_ 1472 EP1_Freigabe_Ver 0 "Verzoegerungsanf_nicht_freigegeb" 1 "Verzoegerungsanf_freigegeben" ;
VAL_ 1472 EP1_AutoHold_zul 0 "Pers_nicht_zulaessig" 1 "Pers_zulaessig" ;
VAL_ 1472 EP1_AutoHold_aktiv 0 "nein" 1 "ja" ;
VAL_ 1472 EP1_SleepInd 0 "CAN_wird_benoetigt" 1 "Sleep_bereit" ;
VAL_ 1472 EP1_Status_Kl_15 0 "Kl_15_aus" 1 "Kl_15_ein" ;
VAL_ 1472 EP1_Lampe_AutoP 0 "Lampe_aus" 1 "Lampe_ein" ;
VAL_ 1472 EP1_Bremslicht 0 "Aus" 1 "Ein" ;
VAL_ 1472 EP1_Warnton1 0 "Aus" 1 "Ein" ;
VAL_ 1472 EP1_Warnton2 0 "Aus" 1 "Ein" ;
VAL_ 1472 EP1_AnfShLock 0 "Aus" 1 "Ein" ;
VAL_ 1472 EP1_Auto_Schl_Oe 0 "nicht_erlaubt" 1 "erlaubt" ;
VAL_ 1472 EP1_QualNeigWi 0 "gueltiger_Wert" 1 "Ersatz_Init_oder_Fehlerwert" ;
VAL_ 1472 EP1_KuppModBer 0 "Kuppsensor_aus_Modbereich" 1 "Kupplsensor_im_Modbereich" 2 "Sensorsignal_ungenau" 3 "Sensor_defekt" ;
VAL_ 1472 EP1_HydrHalten 0 "Fzg_nicht_hydr_geh" 1 "Fzg_hydr_geh" ;
VAL_ 1472 EP1_Fkt_Lampe 0 "Lampe_aus" 1 "Lampe_ein" ;
VAL_ 1472 EP1_Warnton 0 "Warnton_aus" 1 "Warnton_an" ;
VAL_ 1472 EP1_Fehler_BKL 0 "BKL_aus" 1 "BKL_an" ;
VAL_ 1472 EP1_Fehler_gelb 0 "Lampe_aus" 1 "Lampe_ein" ;
VAL_ 1472 EP1__Text 0 "kein_Text" 1 "Text_1" 2 "Text_2" 3 "Text_3" 4 "Text_4" 5 "Text_5" 6 "reserviert" 7 "reserviert" 8 "Text_8" ;
VAL_ 1626 FL1_KD_Fehler 0 "kein_Fehlerspeichereintrag" 1 "Fehlerspeichereintrag" ;
VAL_ 1626 FL1_FLA_aktiv 0 "nicht_aktiv" 1 "aktiv" ;
VAL_ 1626 FL1_ISP_defekt 0 "nicht_defekt" 1 "defekt" ;
VAL_ 1626 FL1_Sensor_blockiert 0 "Sensor_iO" 1 "Sensor_blockiert" ;
VAL_ 1626 FL1_Abblendursache 0 "keine" 1 "entg_Fzg" 2 "voraus_Fzg" 4 "v_unterschr" 8 "Ort_erkannt" 16 "zu_hell" 32 "Nebel" 64 "Uebertemp" 128 "Verz_Bed" 255 "Fehler" ;
VAL_ 1626 FL1_Fernlicht_PWM 127 "Fehler" ;
VAL_ 1626 FL1_ISP_Lichtwert_vo 62 "Init" 63 "Fehler" ;
VAL_ 1626 FL1_ISP_Lichtwert_hi 62 "Init" 63 "Fehler" ;
VAL_ 1626 FL1_ISP_Himmelsrichtung 30 "Init" 31 "Fehler" ;
VAL_ 1626 FL1_ISP_Taste 0 "nicht_betaetigt" 1 "betaetigt" ;
VAL_ 1626 FL1_ISP_EC_aktiv 0 "nicht_aktiv" 1 "aktiv" ;
VAL_ 1626 FL1_ISP_Kompass_aktiv 0 "nicht_aktiv" 1 "aktiv" ;
VAL_ 1626 FL1_Dimmwert_ASP 63 "Fehler" ;
VAL_ 1626 FL1_FLA_Aufblenden 0 "nicht_aufblenden" 1 "aufblenden" ;
VAL_ 912 GK1_Sta_RDK_Warn 0 "aktuell_empfangen" 1 "veraltet" ;
VAL_ 912 GK1_Sta_Anhaen 0 "aktuell_empfangen" 1 "veraltet" ;
VAL_ 912 GK1_Sta_Licht1 0 "aktuell_empfangen" 1 "veraltet" ;
VAL_ 912 GK1_Sta_Licht3 0 "aktuell_empfangen" 1 "veraltet" ;
VAL_ 912 GK1_Sta_Tuerkont 0 "aktuell_empfangen" 1 "veraltet" ;
VAL_ 912 GK1_Sta_Li_vorn 0 "aktuell_empfangen" 1 "veraltet" ;
VAL_ 912 GK1_SleepAckn 0 "CAN_Kom_erforderlich" 1 "Sleep_Mode_Befehl" ;
VAL_ 912 GK1_CharismaModus 0 "Init" 1 "comfort" 2 "normal" 3 "sport" ;
VAL_ 912 GK1_EfficiencyModus 0 "Aus" 1 "Ein" ;
VAL_ 912 GK1_SportModus 0 "Aus" 1 "Ein" ;
VAL_ 912 GK1_DriveSelectModus_1 0 "ds1_init" 1 "ds1_efficiency" 2 "ds1_auto" 3 "sport" ;
VAL_ 912 GK1_DriveSelectModus_2 0 "ds2_init" 1 "ds2_comfort" 2 "ds2_auto" 3 "ds2_dynamic" ;
VAL_ 912 GK1_SamFktNr 0 "ungueltig_Init" 1 "Charisma" 2 "Efficiency" 3 "Sport" 4 "DriveSelect_1" 5 "DriveSelect_2" ;
VAL_ 912 GK1_Fa_Tuerkont 0 "Tuer_geschlossen" 1 "Tuer_offen" ;
VAL_ 912 GK1_RueckfahrSch 0 "aus" 1 "ein" ;
VAL_ 912 GK1_ELV_verrieg 0 "ELV_nicht_verriegelt" 1 "ELV_verriegelt" ;
VAL_ 912 GK1_Sta_Kessy_2 0 "aktuell_empfangen" 1 "veraltet" ;
VAL_ 912 GK1_Sta_Stdhzg 0 "aktuell_empfangen" 1 "veraltet" ;
VAL_ 912 GK1_SH_Verbau 0 "Zuheizer" 1 "Standheizung" ;
VAL_ 912 GK1_ParkFrontWi 0 "keine_Parklage" 1 "Parklage" ;
VAL_ 912 GK1_KW_Warm 0 "nein" 1 "ja" ;
VAL_ 912 BCM_Remotestart_Betrieb 0 "kein_RS_Betrieb" 1 "RS_Betrieb" ;
VAL_ 912 BCM_Offroad_Taster 0 "nicht_betaetigt" 1 "betaetigt" ;
VAL_ 912 BSK_HL_geoeffnet 0 "Tuer_geschlossen" 1 "Tuer_offen" ;
VAL_ 912 BSK_HR_geoeffnet 0 "Tuer_geschlossen" 1 "Tuer_offen" ;
VAL_ 912 GK1_Rueckfahr 1 "Rueckfahrlicht_ein" ;
VAL_ 912 GK1_BrLi_links 0 "Leuchte_i_O" 1 "Bremslicht_HL_def" ;
VAL_ 912 GK1_BrLi_rechts 0 "Leuchte_i_O" 1 "Bremslicht_HR_def" ;
VAL_ 912 GK1_BrLi_mitte 0 "Leuchte_i_O" 1 "Bremslicht_oben_def" ;
VAL_ 912 GK1_BLS_ILM 0 "ok" 1 "unplausibel" ;
VAL_ 912 GK1_EDC_ILM 0 "ok" 1 "unplausibel" ;
VAL_ 912 GK1_Blinker_li 0 "aus" 1 "aktiviert" ;
VAL_ 912 GK1_Blinker_re 0 "aus" 1 "aktiviert" ;
VAL_ 912 GK1_def_P_verr 0 "OK" 1 "defekt" ;
VAL_ 912 GK1_LS1_Fernlicht 0 "Fernlichtschalter_aus" 1 "Fernlichtschalter_ein" ;
VAL_ 912 GK1_Sta_Licht2 0 "aktuell_empfangen" 1 "veraltet" ;
VAL_ 912 GK1_Sta_LSM 0 "aktuell_empfangen" 1 "veraltet" ;
VAL_ 912 BSK_BT_geoeffnet 0 "Tuer_geschlossen" 1 "Tuer_offen" ;
VAL_ 912 BCM_CV_Taster 0 "nicht_betaetigt" 1 "betaetigt" ;
VAL_ 912 BSK_HD_Hauptraste 0 "geschlossen" 1 "Hauptraste" ;
VAL_ 912 GK1_Anhaenger 0 "kein_Anhaenger_erkannt" 1 "Anhaenger_erkannt" ;
VAL_ 912 GK1_BrLi_Anhaen 0 "i_O" 1 "defekt" ;
VAL_ 912 GK1_Abblendlicht 0 "aus" 1 "Kl56b_ein" ;
VAL_ 912 GK1_Fernlicht 0 "aus" 1 "Kl56a_ein" ;
VAL_ 912 GK1_Wischer_vorn 0 "Wischer_aus" 1 "Wischer_vorne_laeuft" ;
VAL_ 912 GK1_Sta_ILM_F_1 0 "aktuell_empfangen" 1 "veraltet" ;
VAL_ 912 GK1_Abbl_VL_def 0 "Leuchte_i_O" 1 "Abblendlicht_VL_def" ;
VAL_ 912 GK1_Abbl_VR_def 0 "Leuchte_i_O" 1 "Abblendlicht_VR_def" ;
VAL_ 912 GK1_Blink_Autob 0 "Autobahnblinken_aus" 1 "Autobahnblinken_aktiviert" ;
VAL_ 912 GK1_Warnblk_Status 1 "Warnblinkstatus_ein" ;
VAL_ 912 GK1_SH_laeuft 0 "SH_aus" 1 "SH_ist_oder_war_aktiv" ;
VAL_ 912 SH1_ein_Wasserpumpe 0 "Wasserpumpe_AUS" 1 "Wasserpumpe_EIN" ;
VAL_ 912 GK1_Nebel_ein 0 "aus" 1 "Kl83a_ein" ;
VAL_ 912 GK1_Bremslicht 0 "aus" 1 "Bremslicht_ein" ;
VAL_ 912 GK1_Anh_abgesteckt 0 "nein" 1 "ja" ;
VAL_ 912 GK1_AnhKonLamp 0 "Lampe_aus" 1 "Lampe_ein" ;
VAL_ 912 LDS_Stellung_AFL 1 "LDS_Stellung_AFL" ;
VAL_ 912 GK1_SH_Zusatzfkt 0 "nicht_verf" 1 "verfuegbar" ;
VAL_ 914 GK2_Sta_LSM 0 "aktuell_empfangen" 1 "veraltet" ;
VAL_ 914 GK2_Sta_Lichtsensor 0 "aktuell_empfangen" 1 "veraltet" ;
VAL_ 914 GK2_Sta_Licht1 0 "aktuell_empfangen" 1 "veraltet" ;
VAL_ 914 GK2_Sta_VSG 0 "aktuell_empfangen" 1 "veraltet" ;
VAL_ 914 GK2_Sta_Schluessel 0 "aktuell_empfangen" 1 "veraltet" ;
VAL_ 914 GK2_Sta_Profil 0 "aktuell_empfangen" 1 "veraltet" ;
VAL_ 914 GK2_Sta_Clima2 0 "aktuell_empfangen" 1 "veraltet" ;
VAL_ 914 GK2_Sta_BSG4 0 "aktuell_empfangen" 1 "veraltet" ;
VAL_ 914 GK2_Sta_Kessy_4 0 "aktuell_empfangen" 1 "veraltet" ;
VAL_ 914 BS4_Gleitende_Leuchtw_Anf 0 "Aus" 1 "Ein" ;
VAL_ 914 BS4_GLW_Fernlicht_Anf 0 "Aus" 1 "Ein" ;
VAL_ 914 GK2_Blk_L_Kontrolle 1 "Kontrolllampe_Blk_L_ein" ;
VAL_ 914 GK2_Blk_R_Kontrolle 1 "Kontrolllampe_Blk_R_ein" ;
VAL_ 914 GK2_LS_KomFehler 0 "Werte_aktuell" 1 "Werte_veraltet" ;
VAL_ 914 GK2_LS_def 0 "Lichtsensor_i_O" 1 "Lichtsensor_defekt" ;
VAL_ 914 GK2_VD_zu_ver 0 "Verdeck_nicht_geschl_verr" 1 "Verdeck_geschl_verr" ;
VAL_ 914 GK2_VD_entriegelt 0 "Verdeck_und_VDKD_zu" 1 "Verdeck_bzw_VDKD_auf" ;
VAL_ 914 GK2_VD_offen_ver 0 "Verdeck_nicht_offen_verr" 1 "Verdeck_offen_verr" ;
VAL_ 914 GK2_Verdeck_Anf 0 "keine_Verdeckanforderung" 1 "Anforderung_Verdeckbetrieb" ;
VAL_ 914 GK2_VDKD_auf 0 "VDKD_nicht_vollst_auf" 1 "VDKD_vollstaendig_auf" ;
VAL_ 914 GK2_Schluessel 0 "ungueltig" ;
VAL_ 914 GK2_Hardtop 0 "Hardtop_nicht_montiert" 1 "Hardtop_montiert" ;
VAL_ 914 GK2_AFL_Schalter 0 "aus" 1 "AFL_Schalter_ein" ;
VAL_ 914 GK2_Nebelschluss 0 "aus" 1 "Kl83b_ein" ;
VAL_ 914 GK2_EM_LIN_ungueltig 0 "Signale_gueltig" 1 "Signale_ungueltig" ;
VAL_ 914 GK2_Kl_StSt_Info 0 "Motorlauf_nicht_notwendig_(Stoppfreigabe)" 1 "Motoranlauf_nicht_zwingend_notwendig_(Stoppverbot,keine_Startanforderung)" 2 "Motoranlauf_zwingend_notwendig_(Startanforderung)" 3 "Systemfehler" ;
VAL_ 914 GK2_BSG_StSt_Info 0 "Motorlauf_nicht_notwendig_(Stoppfreigabe)" 1 "Motoranlauf_nicht_zwingend_notwendig_(Stoppverbot,keine_Startanforderung)" 2 "Motoranlauf_zwingend_notwendig_(Startanforderung)" 3 "Systemfehler" ;
VAL_ 914 GK2_BEM_P_Generator 255 "Fehler" ;
VAL_ 914 GK2_BEM_Abschaltstufen 0 "Stufe0" 1 "Stufe1" 2 "Stufe2" 3 "Stufe3" ;
VAL_ 914 GK2_Kessy_StSt_Info 0 "Motorlauf_nicht_notwendig_(Stoppfreigabe)" 1 "Motoranlauf_nicht_zwingend_notwendig_(Stoppverbot,keine_Startanforderung)" 2 "Motoranlauf_zwingend_notwendig_(Startanforderung)" 3 "Systemfehler" ;
VAL_ 914 GK2_BEM_StSt_Info 0 "Motorlauf_nicht_notwendig_(Stoppfreigabe)" 1 "Motoranlauf_nicht_zwingend_notwendig_(Stoppverbot,keine_Startanforderung)" 2 "Motoranlauf_zwingend_notwendig_(Startanforderung)" 3 "Systemfehler" ;
VAL_ 914 BEM_Segel_Info 0 "keine_Anforderung" 1 "Mindestdrehzahl_1" 2 "Mindestdrehzahl_2" 3 "Segelveto" ;
VAL_ 914 LS1_FAS_Taster 0 "Unbetaetigt" 1 "Betaetigt" ;
VAL_ 914 LS1_Fehler_FAS_Taster 0 "kein_Fehler" 1 "Fehler" ;
VAL_ 915 GK3_Sta_Kessy_4 0 "aktuell_empfangen" 1 "veraltet" ;
VAL_ 915 GK3_Sta_BCM_KY1 0 "aktuell_empfangen" 1 "veraltet" ;
VAL_ 915 GK3_Sta_Clima_3 0 "aktuell_empfangen" 1 "veraltet" ;
VAL_ 915 GK3_Sta_TSG_FT_3 0 "aktuell_empfangen" 1 "veraltet" ;
VAL_ 915 GK3_Sta_HD_1 0 "aktuell_empfangen" 1 "veraltet" ;
VAL_ 915 GK3_Sta_Memory_1 0 "aktuell_empfangen" 1 "veraltet" ;
VAL_ 915 GK3_Sta_res_06 0 "aktuell_empfangen" 1 "veraltet" ;
VAL_ 915 GK3_Sta_res_07 0 "aktuell_empfangen" 1 "veraltet" ;
VAL_ 915 GK3_KY4_Meldungen 0 "keine_Meldung" 1 "Schluessel_nicht_gefunden" 2 "Schluessel_im_Kofferraum" 3 "Schluessel_im_Fahrzeug" 4 "Kessy_defekt" ;
VAL_ 915 GK3_KY4_Gong_600 0 "inaktiv" 1 "aktiv" ;
VAL_ 915 GK3_KY4_PassAL_Menue 0 "inaktiv" 1 "aktiv" ;
VAL_ 915 GK3_KY4_PassAL_akt 0 "inaktiv" 1 "aktiv" ;
VAL_ 915 GK3_BK1_IDGeb_1_Sta 0 "keine_Antwort" 1 "authentifiziert" 2 "UHV_Antwort_n_auth" ;
VAL_ 915 GK3_BK1_IDGeb_2_Sta 0 "keine_Antwort" 1 "authentifiziert" 2 "UHV_Antwort_n_auth" ;
VAL_ 915 ME1_EasyEntry_Menu 0 "nicht_verfuegbar" 1 "verfuegbar" ;
VAL_ 915 ME1_EasyEntry_aktiv 0 "inaktiv" 1 "aktiv" ;
VAL_ 915 GK3_BK1_IDGeb_3_Sta 0 "keine_Antwort" 1 "authentifiziert" 2 "UHV_Antwort_n_auth" ;
VAL_ 915 GK3_BK1_IDGeb_4_Sta 0 "keine_Antwort" 1 "authentifiziert" 2 "UHV_Antwort_n_auth" ;
VAL_ 915 GK3_BK1_Anlern_Info 0 "inaktiv" 1 "aktiv" ;
VAL_ 915 FT3_Auto_eKiSi_Menu 0 "inaktiv" 1 "aktiv" ;
VAL_ 915 FT3_Auto_eKiSi_Aktiv 0 "inaktiv" 1 "aktiv" ;
VAL_ 915 MKE_Texte 0 "keine_Anzeige" 1 "Warnstufe_1" 2 "Warnstufe_2" ;
VAL_ 915 HSA_unplausibel 0 "plausibel" 1 "nicht_plausibel" ;
VAL_ 915 CHA_Kombi_Texte 0 "keine_Anzeige" 1 "Text_1" 2 "Text_2" 3 "Text_3" 4 "Text_4" 5 "Text_5" 6 "Text_6" 7 "Text_7" 8 "Text_8" 9 "Text_9" 10 "Text_10" 11 "Text_11" 12 "Text_12" 13 "Text_13" 14 "Text_14" 15 "Text_15" ;
VAL_ 915 HD1_Position 0 "Heckdeckel_geschlossen" 200 "Endlage_oben_od_denormiert" ;
VAL_ 921 GK1_Sta_LSM 0 "aktuell_empfangen" 1 "veraltet" ;
VAL_ 921 GK4_Sta_MFA_6 0 "aktuell_empfangen" 1 "veraltet" ;
VAL_ 921 LS1_P_verriegelt 0 "P_Position" 1 "Waehlhebel_ausserhalb_Park_Position" ;
VAL_ 921 GK4_Ladesteckerentr_Anf 0 "keine_Anf" 1 "Anf_Ladestecker_entr" ;
VAL_ 684 GS1_Fahrtrichtung 0 "Vorwaerts" 1 "Rueckwaerts" ;
VAL_ 684 GS1_QBit_Rad_kmh 0 "gueltiger_Wert" 1 "Ersatz_Init_oder_Fehlerwert" ;
VAL_ 684 GS1_Rad_kmh 65416 "Init" 65433 "Ref_na" 65450 "Unterspannung" 65484 "Sensorfehler" ;
VAL_ 1088 GE1_Schaltung 0 "keine_Schaltung" 1 "Schaltung_laeuft" ;
VAL_ 1088 GE1_Sta_Schutz 0 "kein_Schutz" 1 "Schutz_angefordert" ;
VAL_ 1088 GE1_Klimakompr 0 "keine_Anforderung" 1 "Kompressor_aus" ;
VAL_ 1088 GE1_WK 0 "WK_geoeffnet" 1 "WK_geregelt" 2 "WK_geschlossen" 3 "Fehler" ;
VAL_ 1088 GE1_StSt_Info 0 "Motorlauf_nicht_notwendig_(Stoppfreigabe)" 1 "Motoranlauf_nicht_zwingend_notwendig_(Stoppverbot,keine_Startanforderung)" 2 "Motoranlauf_zwingend_notwendig_(Startanforderung)" 3 "Systemfehler" ;
VAL_ 1088 GE1_EGS_Anf 0 "keine_Anforderung" 1 "EGS_Anforderung" ;
VAL_ 1088 GE1_Zielgang 0 "Gang_P_N_ausgekuppelt" 1 "Gang_1" 2 "Gang_2" 3 "Gang_3" 4 "Gang_4" 5 "Gang_5" 6 "_1m_Gang" 7 "Gang_R" 8 "Gang_6" 9 "Gang_7" 10 "Gang_8" 14 "Istgang_nicht_definiert" 15 "Fehler" ;
VAL_ 1088 GE1_Wahl_Pos 0 "Zwischenstellung" 1 "Pos_1" 2 "Pos_2" 3 "Pos_3" 4 "Pos_4" 5 "Pos_D_oder_Automatic_Selespeed" 6 "Pos_N" 7 "Pos_R" 8 "Pos_P_oder_Key_Lock_Release_Selespeed" 9 "Pos_RSP_oder_Manual_Sport_Selespeed" 10 "Pos_Z1" 11 "Pos_Z2" 12 "Pos_S_oder_Automatic_Sport_Selespeed" 13 "Pos_L" 14 "Tipp_Gasse_oder_Manual_Selespeed" 15 "Fehler" ;
VAL_ 1088 GE1_Mrad_Mkurb 255 "Fehler" ;
VAL_ 1088 GE1_Soll_Mo 255 "Fehler" ;
VAL_ 1088 GE1_Fahrwistd 255 "Fehler" ;
VAL_ 1088 GE1_Notlauf 1 "kein_Schalten" 2 "Schalten_nach_n" 3 "Schalten_50_Prozent" 4 "Fahren_ohne_UEK" 5 "kein_Notlauf" 6 "kein_Notlauf" 7 "kein_Notlauf" 15 "Totalausfall" ;
VAL_ 1088 GE1_Kuehlung 0 "OFF" 1 "Stufe_1" 2 "Stufe_2" 3 "Stufe_3" ;
VAL_ 1088 GE1_Sta_OBD 0 "MIL_aus" 1 "MIL_ein" ;
VAL_ 1088 GE1_LaunchControl 0 "nicht_aktiv" 1 "aktiv" ;
VAL_ 1088 GE1_Infobit 0 "Stufenautomat" 1 "CVT" ;
VAL_ 1088 GE1_SleepInd 0 "CAN_wird_benoetigt" 1 "Sleep_bereit" ;
VAL_ 1088 GE1_Fehlereintr 0 "kein_Fehlerspeichereintrag" 1 "Fehlerspeichereintrag" ;
VAL_ 1088 GE1_WaVerl_Mo 255 "Fehler" ;
VAL_ 1344 GE2_LFR_Adap 0 "fuer_Adaption_geeignet" 1 "fuer_Adaption_nicht_geeignet" ;
VAL_ 1344 GE2_Sta_SAS 0 "inaktiv" 1 "aktiv" ;
VAL_ 1344 GE2_Sta_ZwGas 0 "inaktiv" 1 "aktiv" ;
VAL_ 1344 GE2_LL_Solldz 255 "Fehler" ;
VAL_ 1344 GE2_Grad_begr 255 "keine_Begrenzung" ;
VAL_ 1344 GE2_Sync_Zeit 255 "Fehler" ;
VAL_ 1344 GE2_DZM_Daempf 0 "normal" 1 "dynamisch" ;
VAL_ 1344 GE2_Gong 0 "Aus" 1 "Ein" ;
VAL_ 1344 GE2_Segeln_aktiv 0 "kein_Segeln" 1 "Segeln" ;
VAL_ 1344 GE2_Shift_Lock 0 "Lampe_aus" 1 "Lampe_ein" ;
VAL_ 1344 GE2_Senderkennung 0 "GSG_oder_MSG_E_Fzg" 1 "MSG" ;
VAL_ 1344 GE2_WBA_Blinken 0 "Lampe_aus_kein_Blinken" 1 "Lampe_ein_Blinken" ;
VAL_ 1344 GE2_Variante 0 "_5_Gang_automat" 1 "Automat_PRND" 2 "_4_Gang_Automat" 3 "ASG_Getriebe" 4 "Selespeed" 5 "Vorhalt_fuer_9_Gang_Automat_Tiptronic" 6 "Automat_PRNDS" 7 "Automat_PRNED" 8 "_4_Gang_Automat_Tiptronic" 9 "_5_Gang_Automat_Tiptronic" 11 "PRNDB_reserviert_fuer_EGolf" 12 "_6_Gang_Automat_Tiptronic" 13 "_7_Gang_Automat_Tiptronic" 14 "_8_Gang_Automat_Tiptronic" 15 "aktuell_eingelegter_Gang" ;
VAL_ 1344 GE2_5Gang 0 "Normaldarstellung" 1 "Inversdarstellung" 2 "P" 3 "R" 4 "N" 5 "D" 6 "_4" 7 "_3" 8 "_2" ;
VAL_ 1344 GE2_PRND 0 "Normaldarstellung" 1 "Inversdarstellung" 2 "P" 3 "R" 4 "N" 5 "D" ;
VAL_ 1344 GE2_4Gang 0 "Normaldarstellung" 1 "Inversdarstellung" 2 "P" 3 "R" 4 "N" 5 "D" 6 "_3" 7 "_2" 8 "_1" ;
VAL_ 1344 GE2_ASG 0 "Normaldarstellung" 1 "Inversdarstellung" 2 "S" 3 "R" 4 "N" 5 "D_E" 6 "E7" 7 "E6" 8 "E5" 9 "E4" 10 "E3" 11 "E2" 12 "E1" ;
VAL_ 1344 GE2_Selespeed 0 "Normaldarstellung" 1 "Inversdarstellung" 2 "M" 3 "M_S" 4 "M_W" 5 "A" 6 "A_S" 7 "A_W" 8 "keine_Anzeige" 9 "Vorhalt_S" 10 "Vorhalt_W" ;
VAL_ 1344 GE2_PRNDS 0 "Normaldarstellung" 1 "Inversdarstellung" 2 "P" 3 "R" 4 "N" 5 "D" 6 "S" ;
VAL_ 1344 GE2_PRNED 0 "Normaldarstellung" 1 "Inversdarstellung" 2 "P" 3 "R" 4 "N" 5 "E" 6 "D" ;
VAL_ 1344 GE2_Tip4Gang 0 "Normaldarstellung" 1 "Inversdarstellung" 2 "_1" 3 "_2" 4 "_3" 5 "_4" ;
VAL_ 1344 GE2_Tip5Gang 0 "Normaldarstellung" 1 "Inversdarstellung" 2 "_1" 3 "_2" 4 "_3" 5 "_4" 6 "_5" ;
VAL_ 1344 GE2_PRNDB 0 "Normaldarstellung" 1 "Inversdarstellung" 2 "P" 3 "R" 4 "N" 5 "D" 6 "B" ;
VAL_ 1344 GE2_Tip6Gang 0 "Normaldarstellung" 1 "Inversdarstellung" 2 "_1" 3 "_2" 4 "_3" 5 "_4" 6 "_5" 7 "_6" ;
VAL_ 1344 GE2_Tip7Gang 0 "Normaldarstellung" 1 "Inversdarstellung" 2 "_1" 3 "_2" 4 "_3" 5 "_4" 6 "_5" 7 "_6" 8 "_7" ;
VAL_ 1344 GE2_Tip8Gang 0 "Normaldarstellung" 1 "Inversdarstellung" 2 "_1" 3 "_2" 4 "_3" 5 "_4" 6 "_5" 7 "_6" 8 "_7" 9 "_8" ;
VAL_ 1344 GE2_akt_Gang 0 "kein_Gang_eingelegt" 2 "_1_ist_eingelegt" 3 "_2_ist_eingelegt" 4 "_3_ist_eingelegt" 5 "_4_ist_eingelegt" 6 "_5_ist_eingelegt" 7 "_6_ist_eingelegt" 8 "_7_ist_eingelegt" 9 "_8_ist_eingelegt" 12 "R_ist_eingelegt" 13 "N_ist_eingelegt" ;
VAL_ 1090 GM3_MomEingr 0 "keine_Freigabe" 1 "MomEingAnf_moeglich" ;
VAL_ 1090 GM3_MoSoMom 1022 "kein_Eingriff" 1023 "Fehler" ;
VAL_ 1090 GM3_StaSoMom 0 "keine_anforderung" 1 "reduz_Getriebeeingriff" 2 "erh_Getriebeeingriff" 3 "Fehler" ;
VAL_ 1090 GM3_MomID 0 "reserviert" 15 "Fehler" ;
VAL_ 1090 GM3_Moment 1023 "Neutralwert" ;
VAL_ 1090 GM3_QB_LangEingr 0 "gueltiger_Wert" 1 "Ersatz_Init_oder_Fehlerwert" ;
VAL_ 1090 GM3_LangEingr 1022 "kein_Eingriff" 1023 "Fehler" ;
VAL_ 1352 GE4_Shiftlock 0 "Waehlhebel_verriegelt" 1 "Waehlhebel_frei" ;
VAL_ 1352 GE4_AuslModus 0 "RDW" 1 "USA" ;
VAL_ 1352 GE4_Test 0 "kein_Test" 1 "Test_aktiv" ;
VAL_ 1352 GE4_Tasterausleuchtung 0 "Lampe_aus" 1 "Lampe_ein" ;
VAL_ 1352 GE4_Ausleuchtung 0 "Keine_Lampe_angesteuert" 1 "Position_1" 2 "Position_2" 3 "Position_3" 4 "Position_4" 5 "Position_D" 6 "Position_N" 7 "Position_R" 8 "Position_P_Stop" 10 "Position_Tipp_plus" 11 "Position_Tipp_minus" 12 "Position_S_Sport" 13 "Position_L" 14 "Tipp_Gasse" 15 "Fehler" ;
VAL_ 1346 GE5_Test 0 "kein_Test" 1 "Test_freigegeben" ;
VAL_ 1346 GE5_Abschalten 0 "Ein" 1 "Aus" ;
VAL_ 1346 GE5_Sta_Fahrstufe 0 "Fahrstufe_gueltig" 1 "Fahrstufe_ungueltig" ;
VAL_ 1346 GE5_Ausl_Sport 0 "inaktiv" 1 "aktiv" ;
VAL_ 1346 GE5_Ausl_Winter 0 "inaktiv" 1 "aktiv" ;
VAL_ 1346 GE5_Ausleuchtung 0 "R" 1 "N" 2 "Manuell" 3 "Automatik" ;
